VERSION "HNNBNNNYNNNNNNNNNNNNNNNNNNNNNNNNNNNNNNNNNN/4/%%%/4/'%**4NNN///"

NS_ :

BS_:

BU_: BAP_Tester Gateway_Max Getriebe_DQ Motor_konv Parksperre Schaltbetaetigung

BO_ 313 VMM_02_Auth: 32 Gateway_Max
 SG_ VMM_02_CRC : 0|8@1+ (1,0) [0|255] ""  Getriebe_DQ,Motor_konv
 SG_ VMM_02_BZ : 8|4@1+ (1,0) [0|15] ""  Getriebe_DQ,Motor_konv
 SG_ VZM_aktiver_Basisservice : 12|3@1+ (1.0,0.0) [0.0|7] ""  Motor_konv
 SG_ VZM_Anhalteweg_nicht_verfuegbar : 15|1@1+ (1.0,0.0) [0.0|1] ""  Vector__XXX
 SG_ VZM_Fahrer_bremst : 16|1@1+ (1.0,0.0) [0.0|1] ""  Motor_konv
 SG_ VZM_QBit_Fahrer_bremst : 17|1@1+ (1.0,0.0) [0.0|1] ""  Motor_konv
 SG_ VMM_MKB_codiert : 18|1@1+ (1.0,0.0) [0.0|1] ""  Vector__XXX
 SG_ VMM_Inkonsistenz_EBKV : 19|1@1+ (1.0,0.0) [0.0|1] ""  Vector__XXX
 SG_ VMM_Notstopp_Status : 20|3@1+ (1.0,0.0) [0.0|7] ""  Motor_konv
 SG_ VZM_Warnruck_nicht_verfuegbar : 23|1@1+ (1.0,0.0) [0.0|1] ""  Vector__XXX
 SG_ VZM_Warnruckeln_nicht_verfuegbar : 24|1@1+ (1.0,0.0) [0.0|1] ""  Vector__XXX
 SG_ VZM_Bkd_nicht_verfuegbar : 25|1@1+ (1.0,0.0) [0.0|1] ""  Vector__XXX
 SG_ VMM_Bremslicht_defekt : 26|1@1+ (1.0,0.0) [0.0|1] ""  Motor_konv
 SG_ VZM_Fahrer_bremst_deutlich : 27|1@1+ (1.0,0.0) [0.0|1] ""  Vector__XXX
 SG_ VZM_TSK_SRBM_Anf : 28|1@1+ (1.0,0.0) [0.0|1] ""  Motor_konv
 SG_ VZM_TSK_SRBM_nicht_verfuegbar : 29|1@1+ (1.0,0.0) [0.0|1] ""  Motor_konv
 SG_ VZM_Verz_Reg_aktiv : 30|5@1+ (1.0,0.0) [0.0|31] ""  Motor_konv
 SG_ VZM_Verz_Reg_nicht_verfuegbar : 35|1@1+ (1.0,0.0) [0.0|1] ""  Motor_konv
 SG_ VMM_Inkonsistenz_KAS : 36|1@1+ (1.0,0.0) [0.0|1] ""  Vector__XXX
 SG_ VMM_Bremslicht_unplausibel : 37|1@1+ (1.0,0.0) [0.0|1] ""  Motor_konv
 SG_ VMM_Inkonsistenz_ACC : 38|1@1+ (1.0,0.0) [0.0|1] ""  Vector__XXX
 SG_ VMM_Inkonsistenz_AWV_PCF : 39|1@1+ (1.0,0.0) [0.0|1] ""  Vector__XXX
 SG_ VMM_Inkonsistenz_ARA : 40|1@1+ (1.0,0.0) [0.0|1] ""  Vector__XXX
 SG_ VMM_Inkonsistenz_ParkAssist : 41|1@1+ (1.0,0.0) [0.0|1] ""  Vector__XXX
 SG_ VMM_Inkonsistenz_FAS_VK : 42|1@1+ (1.0,0.0) [0.0|1] ""  Vector__XXX
 SG_ VMM_Inkonsistenz_NV : 43|1@1+ (1.0,0.0) [0.0|1] ""  Vector__XXX
 SG_ VMM_Inkonsistenz_RCTA : 44|1@1+ (1.0,0.0) [0.0|1] ""  Vector__XXX
 SG_ VMM_Inkonsistenz_TSK : 45|1@1+ (1.0,0.0) [0.0|1] ""  Motor_konv
 SG_ VMM_Inkonsistenz_MO : 46|1@1+ (1.0,0.0) [0.0|1] ""  Motor_konv
 SG_ VMM_Inkonsistenz_AEB : 47|1@1+ (1.0,0.0) [0.0|1] ""  Vector__XXX
 SG_ VMM_Fahrer_Bremskraft_bestimmend : 48|1@1+ (1.0,0.0) [0.0|1] ""  Motor_konv
 SG_ VMM_Inkonsistenz_EA : 49|1@1+ (1.0,0.0) [0.0|1] ""  Vector__XXX
 SG_ VZM_Status_Wegregelung : 50|2@1+ (1.0,0.0) [0.0|3] ""  Motor_konv
 SG_ VZM_Verz_ASIL_Verfuegbarkeit : 52|3@1+ (1.0,0.0) [0.0|7] ""  Motor_konv
 SG_ VZM_aktives_System : 55|5@1+ (1.0,0.0) [0.0|31] ""  Motor_konv
 SG_ VZM_Verz_Begrenzung : 60|1@1+ (1.0,0.0) [0.0|1] ""  Motor_konv
 SG_ VZM_Systemstatus : 61|3@1+ (1.0,0.0) [0.0|7] ""  Motor_konv
 SG_ VZM_SRBM_Soll : 64|12@1+ (8,0) [0|32744] "Unit_NewtoMeter"  Vector__XXX
 SG_ VZM_SRBM_Ist : 76|12@1+ (8,0) [0|32744] "Unit_NewtoMeter"  Motor_konv
 SG_ VZM_SRBM_max_Gradient : 88|7@1+ (50,0) [0|6250] "Unit_NewtoMeterPerSecon"  Motor_konv
 SG_ VMM_Inkonsistenz_KAM : 95|1@1+ (1.0,0.0) [0.0|1] ""  Vector__XXX
 SG_ VMM_Inkonsistenz_RHP : 96|1@1+ (1.0,0.0) [0.0|1] ""  Vector__XXX
 SG_ HMS_P_beibehalten_GE : 172|2@1+ (1.0,0.0) [0.0|3] ""  Getriebe_DQ
 SG_ VZM_Unterdrueckung_Antriebsmom : 174|1@1+ (1.0,0.0) [0.0|1] ""  Getriebe_DQ,Motor_konv
 SG_ VMM_Inkonsistenz_VLK : 175|1@1+ (1.0,0.0) [0.0|1] ""  Vector__XXX
 SG_ HMS_halten_nicht_verfuegbar_02 : 176|2@1+ (1.0,0.0) [0.0|3] ""  Vector__XXX
 SG_ HMS_halten_nicht_verfuegbar : 180|1@1+ (1.0,0.0) [0.0|1] ""  Getriebe_DQ
 SG_ HMS_parken_nicht_verfuegbar : 192|1@1+ (1.0,0.0) [0.0|1] ""  Getriebe_DQ
 SG_ HMS_Anforderung_GE : 193|3@1+ (1.0,0.0) [0.0|7] ""  Getriebe_DQ
 SG_ HMS_Systemstatus : 196|4@1+ (1.0,0.0) [0.0|15] ""  Getriebe_DQ,Motor_konv
 SG_ HMS_Stillstand : 200|3@1+ (1.0,0.0) [0.0|7] ""  Getriebe_DQ,Motor_konv
 SG_ HMS_aktives_System : 203|5@1+ (1.0,0.0) [0.0|31] ""  Getriebe_DQ,Motor_konv
 SG_ VMM_Inkonsistenz_GE : 208|1@1+ (1.0,0.0) [0.0|1] ""  Vector__XXX
 SG_ VMM_Inkonsistenz_HVLM : 209|1@1+ (1.0,0.0) [0.0|1] ""  Vector__XXX
 SG_ HMS_Fehlerstatus : 210|3@1+ (1.0,0.0) [0.0|7] ""  Getriebe_DQ,Motor_konv
 SG_ HMS_Index_Haltemoment : 213|1@1+ (1.0,0.0) [0.0|1] ""  Motor_konv
 SG_ HMS_Haltemoment : 214|10@1+ (10,0) [0|10210] "Unit_NewtoMeter"  Motor_konv
 SG_ SOK_VMM_02_Signatur : 224|32@1+ (1,0) [0|4294967295] ""  Vector__XXX

BO_ 2331595858 vREM_01: 64 Gateway_Max
 SG_ vREM_Status : 12|3@1+ (1.0,0.0) [0.0|7] ""  Motor_konv
 SG_ vREM_Abstand_P0 : 15|9@1+ (1,0) [0|510] "Unit_Meter"  Motor_konv
 SG_ vREM_Abstand_P1 : 24|9@1+ (1,0) [0|510] "Unit_Meter"  Motor_konv
 SG_ vREM_Abstand_P2 : 33|9@1+ (1,0) [0|510] "Unit_Meter"  Motor_konv
 SG_ vREM_Abstand_P3 : 42|9@1+ (1,0) [0|510] "Unit_Meter"  Motor_konv
 SG_ vREM_Abstand_P4 : 51|9@1+ (1,0) [0|510] "Unit_Meter"  Motor_konv
 SG_ vREM_Abstand_P5 : 60|9@1+ (1,0) [0|510] "Unit_Meter"  Motor_konv
 SG_ vREM_Abstand_P6 : 69|9@1+ (1,0) [0|510] "Unit_Meter"  Motor_konv
 SG_ vREM_Abstand_P7 : 78|9@1+ (1,0) [0|510] "Unit_Meter"  Motor_konv
 SG_ vREM_Abstand_P8 : 87|9@1+ (1,0) [0|510] "Unit_Meter"  Motor_konv
 SG_ vREM_Abstand_P9 : 96|9@1+ (1,0) [0|510] "Unit_Meter"  Motor_konv
 SG_ vREM_Abstand_P10 : 105|9@1+ (1,0) [0|510] "Unit_Meter"  Motor_konv
 SG_ vREM_Abstand_P11 : 114|9@1+ (1,0) [0|510] "Unit_Meter"  Motor_konv
 SG_ vREM_Abstand_P12 : 123|9@1+ (1,0) [0|510] "Unit_Meter"  Motor_konv
 SG_ vREM_Abstand_P13 : 132|9@1+ (1,0) [0|510] "Unit_Meter"  Motor_konv
 SG_ vREM_Abstand_P14 : 141|9@1+ (1,0) [0|510] "Unit_Meter"  Motor_konv
 SG_ vREM_Abstand_P15 : 150|9@1+ (1,0) [0|510] "Unit_Meter"  Motor_konv
 SG_ vREM_Abstand_P16 : 159|9@1+ (1,0) [0|510] "Unit_Meter"  Motor_konv
 SG_ vREM_Abstand_P17 : 168|9@1+ (1,0) [0|510] "Unit_Meter"  Motor_konv
 SG_ vREM_Abstand_P18 : 177|9@1+ (1,0) [0|510] "Unit_Meter"  Motor_konv
 SG_ vREM_Abstand_P19 : 186|9@1+ (1,0) [0|510] "Unit_Meter"  Motor_konv
 SG_ vREM_Abstand_P20 : 195|9@1+ (1,0) [0|510] "Unit_Meter"  Motor_konv
 SG_ vREM_Abstand_P21 : 204|9@1+ (1,0) [0|510] "Unit_Meter"  Motor_konv
 SG_ vREM_Abstand_P22 : 213|9@1+ (1,0) [0|510] "Unit_Meter"  Motor_konv
 SG_ vREM_Abstand_P23 : 222|9@1+ (1,0) [0|510] "Unit_Meter"  Motor_konv
 SG_ vREM_Abstand_P24 : 231|9@1+ (1,0) [0|510] "Unit_Meter"  Motor_konv
 SG_ vREM_Abstand_P25 : 240|9@1+ (1,0) [0|510] "Unit_Meter"  Motor_konv
 SG_ vREM_Abstand_P26 : 249|9@1+ (1,0) [0|510] "Unit_Meter"  Motor_konv
 SG_ vREM_Abstand_P27 : 258|9@1+ (1,0) [0|510] "Unit_Meter"  Motor_konv
 SG_ vREM_Abstand_P28 : 267|9@1+ (1,0) [0|510] "Unit_Meter"  Motor_konv
 SG_ vREM_Abstand_P29 : 276|9@1+ (1,0) [0|510] "Unit_Meter"  Motor_konv
 SG_ vREM_Akt_Zaehler : 285|4@1+ (1,0) [0|15] ""  Motor_konv

BO_ 2331595859 vREM_02: 64 Gateway_Max
 SG_ vREM_Geschw_P0 : 16|8@1+ (0.2778,0) [0.0000|70.2834] "Unit_MeterPerSecon"  Motor_konv
 SG_ vREM_Geschw_P1 : 24|8@1+ (0.2778,0) [0.0000|70.2834] "Unit_MeterPerSecon"  Motor_konv
 SG_ vREM_Geschw_P2 : 32|8@1+ (0.2778,0) [0.0000|70.2834] "Unit_MeterPerSecon"  Motor_konv
 SG_ vREM_Geschw_P3 : 40|8@1+ (0.2778,0) [0.0000|70.2834] "Unit_MeterPerSecon"  Motor_konv
 SG_ vREM_Geschw_P4 : 48|8@1+ (0.2778,0) [0.0000|70.2834] "Unit_MeterPerSecon"  Motor_konv
 SG_ vREM_Geschw_P5 : 56|8@1+ (0.2778,0) [0.0000|70.2834] "Unit_MeterPerSecon"  Motor_konv
 SG_ vREM_Geschw_P6 : 64|8@1+ (0.2778,0) [0.0000|70.2834] "Unit_MeterPerSecon"  Motor_konv
 SG_ vREM_Geschw_P7 : 72|8@1+ (0.2778,0) [0.0000|70.2834] "Unit_MeterPerSecon"  Motor_konv
 SG_ vREM_Geschw_P8 : 80|8@1+ (0.2778,0) [0.0000|70.2834] "Unit_MeterPerSecon"  Motor_konv
 SG_ vREM_Geschw_P9 : 88|8@1+ (0.2778,0) [0.0000|70.2834] "Unit_MeterPerSecon"  Motor_konv
 SG_ vREM_Geschw_P10 : 96|8@1+ (0.2778,0) [0.0000|70.2834] "Unit_MeterPerSecon"  Motor_konv
 SG_ vREM_Geschw_P11 : 104|8@1+ (0.2778,0) [0.0000|70.2834] "Unit_MeterPerSecon"  Motor_konv
 SG_ vREM_Geschw_P12 : 112|8@1+ (0.2778,0) [0.0000|70.2834] "Unit_MeterPerSecon"  Motor_konv
 SG_ vREM_Geschw_P13 : 120|8@1+ (0.2778,0) [0.0000|70.2834] "Unit_MeterPerSecon"  Motor_konv
 SG_ vREM_Geschw_P14 : 128|8@1+ (0.2778,0) [0.0000|70.2834] "Unit_MeterPerSecon"  Motor_konv
 SG_ vREM_Geschw_P15 : 136|8@1+ (0.2778,0) [0.0000|70.2834] "Unit_MeterPerSecon"  Motor_konv
 SG_ vREM_Geschw_P16 : 144|8@1+ (0.2778,0) [0.0000|70.2834] "Unit_MeterPerSecon"  Motor_konv
 SG_ vREM_Geschw_P17 : 152|8@1+ (0.2778,0) [0.0000|70.2834] "Unit_MeterPerSecon"  Motor_konv
 SG_ vREM_Geschw_P18 : 160|8@1+ (0.2778,0) [0.0000|70.2834] "Unit_MeterPerSecon"  Motor_konv
 SG_ vREM_Geschw_P19 : 168|8@1+ (0.2778,0) [0.0000|70.2834] "Unit_MeterPerSecon"  Motor_konv
 SG_ vREM_Geschw_P20 : 176|8@1+ (0.2778,0) [0.0000|70.2834] "Unit_MeterPerSecon"  Motor_konv
 SG_ vREM_Geschw_P21 : 184|8@1+ (0.2778,0) [0.0000|70.2834] "Unit_MeterPerSecon"  Motor_konv
 SG_ vREM_Geschw_P22 : 192|8@1+ (0.2778,0) [0.0000|70.2834] "Unit_MeterPerSecon"  Motor_konv
 SG_ vREM_Geschw_P23 : 200|8@1+ (0.2778,0) [0.0000|70.2834] "Unit_MeterPerSecon"  Motor_konv
 SG_ vREM_Geschw_P24 : 208|8@1+ (0.2778,0) [0.0000|70.2834] "Unit_MeterPerSecon"  Motor_konv
 SG_ vREM_Geschw_P25 : 216|8@1+ (0.2778,0) [0.0000|70.2834] "Unit_MeterPerSecon"  Motor_konv
 SG_ vREM_Geschw_P26 : 224|8@1+ (0.2778,0) [0.0000|70.2834] "Unit_MeterPerSecon"  Motor_konv
 SG_ vREM_Geschw_P27 : 232|8@1+ (0.2778,0) [0.0000|70.2834] "Unit_MeterPerSecon"  Motor_konv
 SG_ vREM_Geschw_P28 : 240|8@1+ (0.2778,0) [0.0000|70.2834] "Unit_MeterPerSecon"  Motor_konv
 SG_ vREM_Geschw_P29 : 248|8@1+ (0.2778,0) [0.0000|70.2834] "Unit_MeterPerSecon"  Motor_konv

BO_ 2463978663 VZE_04: 32 Gateway_Max
 SG_ VZE_Anzeigemodus : 0|2@1+ (1.0,0.0) [0.0|3] ""  Vector__XXX
 SG_ VZE_Hinweistext : 2|3@1+ (1,0) [1|7] ""  Motor_konv
 SG_ VZE_Akustik_Limitwechsel : 5|1@1+ (1.0,0.0) [0.0|1] ""  Vector__XXX
 SG_ VZE_Modus_OptischeWarnung : 6|1@1+ (1.0,0.0) [0.0|1] ""  Vector__XXX
 SG_ VZE_Verkehrszeichen_Einheit : 8|1@1+ (1.0,0.0) [0.0|1] ""  Vector__XXX
 SG_ VZE_Anzeigeunterdrueck_Zeichen_3 : 9|1@1+ (1.0,0.0) [0.0|1] ""  Vector__XXX
 SG_ VZE_Anzeigeunterdrueck_Zeichen_2 : 10|1@1+ (1.0,0.0) [0.0|1] ""  Vector__XXX
 SG_ VZE_Verkehrszeichen_1 : 11|8@1+ (1,0) [1|255] ""  Motor_konv
 SG_ VZE_Verkehrszeichen_2 : 19|8@1+ (1,0) [1|255] ""  Vector__XXX
 SG_ VZE_Verkehrszeichen_3 : 27|8@1+ (1,0) [1|255] ""  Vector__XXX
 SG_ VZE_Warnung_Verkehrszeichen_1 : 35|1@1+ (1.0,0.0) [0.0|1] ""  Vector__XXX
 SG_ VZE_Warnung_Verkehrszeichen_2 : 36|1@1+ (1.0,0.0) [0.0|1] ""  Vector__XXX
 SG_ VZE_Warnung_Verkehrszeichen_3 : 37|1@1+ (1.0,0.0) [0.0|1] ""  Vector__XXX
 SG_ VZE_Zusatzschild_1 : 38|4@1+ (1,0) [1|15] ""  Vector__XXX
 SG_ VZE_Zusatzschild_2 : 42|4@1+ (1,0) [1|15] ""  Vector__XXX
 SG_ VZE_Zusatzschild_3 : 46|4@1+ (1,0) [1|15] ""  Vector__XXX
 SG_ VZE_Anzeigeunterdrueck_Zeichen_1 : 50|1@1+ (1.0,0.0) [0.0|1] ""  Vector__XXX
 SG_ VZE_Zeichen_01_KameraWied : 51|1@1+ (1.0,0.0) [0.0|1] ""  Motor_konv
 SG_ VZE_Zeichen_02_KameraWied : 52|1@1+ (1.0,0.0) [0.0|1] ""  Vector__XXX
 SG_ VZE_Zeichen_03_KameraWied : 53|1@1+ (1.0,0.0) [0.0|1] ""  Vector__XXX
 SG_ VZE_Zeichen_01_Kamera : 54|1@1+ (1.0,0.0) [0.0|1] ""  Motor_konv
 SG_ VZE_Zeichen_01_Karte : 55|1@1+ (1.0,0.0) [0.0|1] ""  Vector__XXX
 SG_ VZE_Zeichen_01_Gesetz : 56|1@1+ (1.0,0.0) [0.0|1] ""  Vector__XXX
 SG_ VZE_Zeichen_02_Kamera : 57|1@1+ (1.0,0.0) [0.0|1] ""  Vector__XXX
 SG_ VZE_Zeichen_02_Karte : 58|1@1+ (1.0,0.0) [0.0|1] ""  Vector__XXX
 SG_ VZE_Zeichen_02_Gesetz : 59|1@1+ (1.0,0.0) [0.0|1] ""  Vector__XXX
 SG_ VZE_Zeichen_03_Kamera : 60|1@1+ (1.0,0.0) [0.0|1] ""  Vector__XXX
 SG_ VZE_Zeichen_03_Karte : 61|1@1+ (1.0,0.0) [0.0|1] ""  Vector__XXX
 SG_ VZE_Zeichen_03_Gesetz : 62|1@1+ (1.0,0.0) [0.0|1] ""  Vector__XXX
 SG_ VZE_Gong : 63|1@1+ (1.0,0.0) [0.0|1] ""  Vector__XXX
 SG_ VZE_Akustik_Limitwechsel_Status : 69|1@1+ (1.0,0.0) [0.0|1] ""  Vector__XXX
 SG_ VZE_SLWF_Status : 70|2@1+ (1.0,0.0) [0.0|3] ""  Vector__XXX
 SG_ VZE_Anzeigeunterdrueck_Zeichen_5 : 72|1@1+ (1.0,0.0) [0.0|1] ""  Vector__XXX
 SG_ VZE_Zeichen_05_KameraWied : 73|1@1+ (1.0,0.0) [0.0|1] ""  Vector__XXX
 SG_ VZE_Zeichen_05_Kamera : 74|1@1+ (1.0,0.0) [0.0|1] ""  Vector__XXX
 SG_ VZE_Verkehrszeichen_4 : 75|8@1+ (1,0) [1|255] ""  Motor_konv
 SG_ VZE_Verkehrszeichen_5 : 83|8@1+ (1,0) [1|255] ""  Motor_konv
 SG_ VZE_Anhaenger_Vmax : 91|4@1+ (10,10) [10|140] "Unit_KiloMeterPerHour"  Motor_konv
 SG_ VZE_Zeichen_04_Gesetz : 95|1@1+ (1.0,0.0) [0.0|1] ""  Vector__XXX
 SG_ VZE_Zeichen_04_Kamera : 96|1@1+ (1.0,0.0) [0.0|1] ""  Vector__XXX
 SG_ VZE_Zeichen_04_KameraWied : 97|1@1+ (1.0,0.0) [0.0|1] ""  Vector__XXX
 SG_ VZE_Zeichen_04_Karte : 98|1@1+ (1.0,0.0) [0.0|1] ""  Vector__XXX
 SG_ VZE_Warnung_Verkehrszeichen_4 : 99|1@1+ (1.0,0.0) [0.0|1] ""  Vector__XXX
 SG_ VZE_Warnung_Verkehrszeichen_5 : 100|1@1+ (1.0,0.0) [0.0|1] ""  Vector__XXX
 SG_ VZE_Zeichen_05_Gesetz : 101|1@1+ (1.0,0.0) [0.0|1] ""  Vector__XXX
 SG_ VZE_Zusatzschild_4 : 102|4@1+ (1,0) [1|15] ""  Vector__XXX
 SG_ VZE_Zusatzschild_5 : 106|4@1+ (1,0) [1|15] ""  Vector__XXX
 SG_ VZE_Baustelle : 110|2@1+ (1.0,0.0) [0.0|3] ""  Vector__XXX
 SG_ VZE_Zeichen_05_Karte : 112|1@1+ (1.0,0.0) [0.0|1] ""  Vector__XXX
 SG_ VZE_Zeichen_05_Entfernung : 113|7@1+ (1,0) [1|127] "Unit_Meter"  Motor_konv
 SG_ VZE_Zeichen_05_Entfernung_StdA : 120|7@1+ (1,0) [1|127] "Unit_Meter"  Motor_konv
 SG_ VZE_Anzeigeunterdrueck_Zeichen_4 : 127|1@1+ (1.0,0.0) [0.0|1] ""  Vector__XXX
 SG_ VZE_Verkehrszeichen_6 : 128|8@1+ (1,0) [1|255] "Unit_None"  Motor_konv
 SG_ VZE_Zusatzschild_6 : 136|4@1+ (1,0) [1|15] ""  Vector__XXX
 SG_ VZE_Zeichen_06_Entfernung : 140|7@1+ (1,0) [1|127] "Unit_Meter"  Motor_konv
 SG_ VZE_Zeichen_06_Entfernung_StdA : 147|7@1+ (1,0) [1|127] "Unit_Meter"  Motor_konv
 SG_ VZE_Umweltinfo_Naesse : 154|1@1+ (1.0,0.0) [0.0|1] ""  Motor_konv
 SG_ VZE_Umweltinfo_Nebel : 155|1@1+ (1.0,0.0) [0.0|1] ""  Motor_konv
 SG_ VZE_Umweltinfo_Anhaengerbetrieb : 156|1@1+ (1.0,0.0) [0.0|1] ""  Motor_konv
 SG_ VZE_Erweiterte_Information : 157|8@1+ (1,0) [1|255] "Unit_None"  Vector__XXX
 SG_ VZE_Tempowarnung_Status : 165|1@1+ (1.0,0.0) [0.0|1] ""  Vector__XXX
 SG_ VZE_Tempowarnung_Einheit : 166|1@1+ (1.0,0.0) [0.0|1] ""  Vector__XXX
 SG_ VZE_Tempowarnung_Offset : 167|5@1+ (1,0) [1|31] ""  Vector__XXX
 SG_ VZE_FoD_Status : 206|2@1+ (1.0,0.0) [0.0|3] ""  Motor_konv
 SG_ VZE_Anzeige_ZS_1 : 208|4@1+ (1,0) [1|15] "Unit_None"  Vector__XXX
 SG_ VZE_Anzeige_ZS_2 : 212|4@1+ (1,0) [1|15] "Unit_None"  Vector__XXX
 SG_ VZE_Anzeige_ZS_3 : 216|4@1+ (1,0) [1|15] "Unit_None"  Vector__XXX
 SG_ VZE_Hinweistext_03 : 220|4@1+ (1,0) [1|15] ""  Vector__XXX
 SG_ VZE_Land : 224|5@1+ (1,0) [1|31] ""  Vector__XXX
 SG_ VZE_Warnung_VZ_1 : 229|1@1+ (1.0,0.0) [0.0|1] ""  Vector__XXX
 SG_ VZE_Warnung_VZ_2 : 230|1@1+ (1.0,0.0) [0.0|1] ""  Vector__XXX
 SG_ VZE_Warnung_VZ_3 : 231|1@1+ (1.0,0.0) [0.0|1] ""  Vector__XXX
 SG_ VZE_Anzeige_VZ_1 : 232|8@1+ (1,0) [1|255] ""  Vector__XXX
 SG_ VZE_Anzeige_VZ_2 : 240|8@1+ (1,0) [1|255] "Unit_None"  Vector__XXX
 SG_ VZE_Anzeige_VZ_3 : 248|8@1+ (1,0) [1|255] "Unit_None"  Vector__XXX

BO_ 181 Waehlhebel_04: 8 Gateway_Max
 SG_ Waehlhebel_04_CRC : 0|8@1+ (1,0) [0|255] ""  Getriebe_DQ
 SG_ Waehlhebel_04_BZ : 8|4@1+ (1,0) [0|15] ""  Getriebe_DQ
 SG_ WH_gespeicherte_Fahrstufe : 12|3@1+ (1.0,0.0) [0.0|7] ""  Gateway_Max,Getriebe_DQ
 SG_ WH_Initialisierung : 15|1@1+ (1.0,0.0) [0.0|1] ""  Vector__XXX
 SG_ WH_SensorPos_roh : 16|4@1+ (1.0,0.0) [0.0|15] ""  Vector__XXX
 SG_ WH_SensorPos_roh_inv : 20|4@1+ (1.0,0.0) [0.0|15] ""  Vector__XXX
 SG_ WH_Testergebnis : 24|8@1+ (1,0) [0|255] ""  Vector__XXX
 SG_ WH_Test_Aktiv : 32|1@1+ (1.0,0.0) [0.0|1] ""  Vector__XXX
 SG_ WH_Ist_Haltemagnet : 33|2@1+ (1.0,0.0) [0.0|3] ""  Vector__XXX
 SG_ WH_Variante : 35|4@1+ (1.0,0.0) [0.0|15] ""  Getriebe_DQ
 SG_ WH_Entsperrtaste_02 : 39|2@1+ (1.0,0.0) [0.0|3] ""  Getriebe_DQ
 SG_ WH_P_Taste : 41|2@1+ (1.0,0.0) [0.0|3] ""  Getriebe_DQ
 SG_ WH_Ende_N_Haltephase : 43|1@1+ (1.0,0.0) [0.0|1] ""  Vector__XXX
 SG_ WH_Fahrstufe : 44|4@1+ (1.0,0.0) [0.0|15] ""  Getriebe_DQ
 SG_ WH_Status_Shiftlock : 48|3@1+ (1.0,0.0) [0.0|7] ""  Vector__XXX
 SG_ WH_Zustand_N_Haltephase : 51|2@1+ (1.0,0.0) [0.0|3] ""  Vector__XXX
 SG_ WH_Zustand_N_Haltephase_2 : 53|3@1+ (1.0,0.0) [0.0|7] ""  Vector__XXX

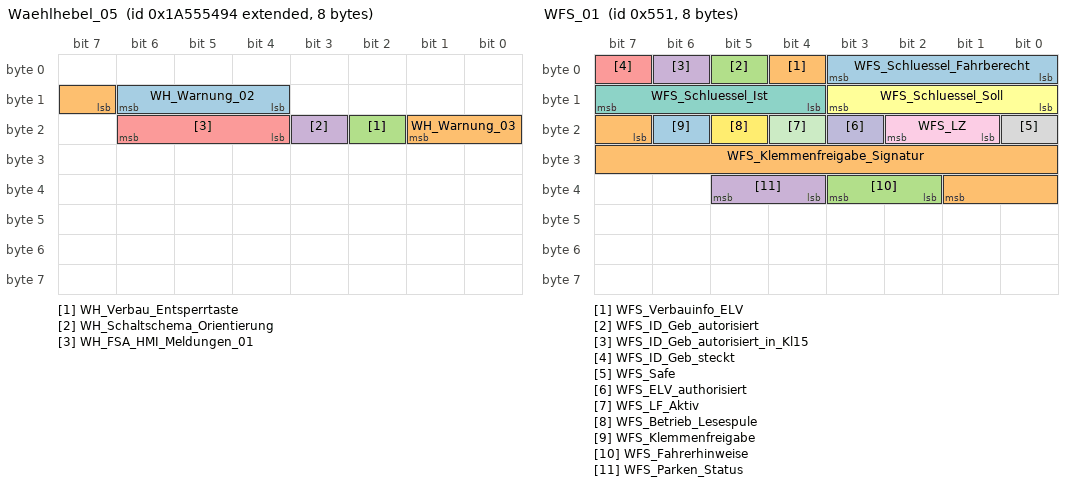
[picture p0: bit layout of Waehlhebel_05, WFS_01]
BO_ 2589283476 Waehlhebel_05: 8 Getriebe_DQ
 SG_ WH_Warnung_02 : 12|3@1+ (1.0,0.0) [0.0|7] ""  Gateway_Max
 SG_ WH_Warnung_03 : 15|3@1+ (1.0,0.0) [0.0|7] ""  Gateway_Max
 SG_ WH_Verbau_Entsperrtaste : 18|1@1+ (1.0,0.0) [0.0|1] ""  Gateway_Max
 SG_ WH_Schaltschema_Orientierung : 19|1@1+ (1.0,0.0) [0.0|1] ""  Gateway_Max
 SG_ WH_FSA_HMI_Meldungen_01 : 20|3@1+ (1.0,0.0) [0.0|7] ""  Gateway_Max

BO_ 2463978687 Waehlhebel_06: 8 Gateway_Max
 SG_ WH_Fehler_Haltemagnet : 40|1@1+ (1.0,0.0) [0.0|1] ""  Vector__XXX
 SG_ WH_Fehler_Haltemagnet_Status : 41|1@1+ (1.0,0.0) [0.0|1] ""  Vector__XXX
 SG_ WH_Fehler_CRC_SBM : 42|1@1+ (1.0,0.0) [0.0|1] ""  Getriebe_DQ
 SG_ WH_Fehler_CRC_SBM_Status : 43|1@1+ (1.0,0.0) [0.0|1] ""  Getriebe_DQ
 SG_ WH_Fehler_Timeout_SBM : 44|1@1+ (1.0,0.0) [0.0|1] ""  Getriebe_DQ
 SG_ WH_Fehler_Timeout_SBM_Status : 45|1@1+ (1.0,0.0) [0.0|1] ""  Getriebe_DQ
 SG_ WH_Fehler_Ueberspannung : 46|1@1+ (1.0,0.0) [0.0|1] ""  Getriebe_DQ
 SG_ WH_Fehler_Ueberspannung_Status : 47|1@1+ (1.0,0.0) [0.0|1] ""  Getriebe_DQ
 SG_ WH_Fehler_BZ_SBM : 48|1@1+ (1.0,0.0) [0.0|1] ""  Getriebe_DQ
 SG_ WH_Fehler_BZ_SBM_Status : 49|1@1+ (1.0,0.0) [0.0|1] ""  Getriebe_DQ
 SG_ WH_Fehler_Unterspannung : 50|1@1+ (1.0,0.0) [0.0|1] ""  Getriebe_DQ
 SG_ WH_Fehler_Unterspannung_Status : 51|1@1+ (1.0,0.0) [0.0|1] ""  Getriebe_DQ
 SG_ WH_Fehler_Ausleuchtung : 52|1@1+ (1.0,0.0) [0.0|1] ""  Getriebe_DQ
 SG_ WH_Fehler_Ausleuchtung_Status : 53|1@1+ (1.0,0.0) [0.0|1] ""  Getriebe_DQ
 SG_ WH_Fehler_Entsperrtaste : 54|1@1+ (1.0,0.0) [0.0|1] ""  Getriebe_DQ
 SG_ WH_Fehler_Entsperrtaste_Status : 55|1@1+ (1.0,0.0) [0.0|1] ""  Getriebe_DQ
 SG_ WH_Fehler_P_Taste : 56|1@1+ (1.0,0.0) [0.0|1] ""  Getriebe_DQ
 SG_ WH_Fehler_P_Taste_Status : 57|1@1+ (1.0,0.0) [0.0|1] ""  Getriebe_DQ
 SG_ WH_Fehler_Sensor_einfach : 58|1@1+ (1.0,0.0) [0.0|1] ""  Getriebe_DQ
 SG_ WH_Fehler_Sensor_einfach_Status : 59|1@1+ (1.0,0.0) [0.0|1] ""  Getriebe_DQ
 SG_ WH_Fehler_Sensor_mehrfach : 60|1@1+ (1.0,0.0) [0.0|1] ""  Getriebe_DQ
 SG_ WH_Fehler_Sensor_mehrfach_Status : 61|1@1+ (1.0,0.0) [0.0|1] ""  Getriebe_DQ
 SG_ WH_Fehler_Shiftlock : 62|1@1+ (1.0,0.0) [0.0|1] ""  Getriebe_DQ
 SG_ WH_Fehler_Shiftlock_Status : 63|1@1+ (1.0,0.0) [0.0|1] ""  Getriebe_DQ

BO_ 916 WBA_03: 8 Getriebe_DQ
 SG_ WBA_03_CRC : 0|8@1+ (1,0) [0|255] ""  Gateway_Max
 SG_ WBA_03_BZ : 8|4@1+ (1,0) [0|15] ""  Gateway_Max
 SG_ WBA_Fahrstufe_02 : 12|4@1+ (1.0,0.0) [0.0|15] ""  Gateway_Max
 SG_ WBA_ZielFahrstufe : 16|4@1+ (1.0,0.0) [0.0|15] ""  Gateway_Max
 SG_ WBA_GE_Warnung_02 : 20|4@1+ (1.0,0.0) [0.0|15] ""  Gateway_Max
 SG_ WBA_eing_Gang_02 : 24|4@1+ (1.0,0.0) [0.0|15] ""  Gateway_Max
 SG_ WBA_GE_Texte : 28|3@1+ (1.0,0.0) [0.0|7] ""  Gateway_Max
 SG_ WBA_Segeln_aktiv : 31|1@1+ (1.0,0.0) [0.0|1] ""  Gateway_Max,Motor_konv
 SG_ WBA_Schaltschema_02 : 32|3@1+ (1.0,0.0) [0.0|7] ""  Gateway_Max
 SG_ WBA_Schaltschema_FS_inaktiv : 35|2@1+ (1.0,0.0) [0.0|3] ""  Gateway_Max
 SG_ WBA_GE_Zusatzwarnungen : 37|3@1+ (1.0,0.0) [0.0|7] ""  Gateway_Max
 SG_ GE_Sollgang : 40|4@1+ (1.0,0.0) [0.0|15] ""  Gateway_Max,Motor_konv
 SG_ GE_Tipschaltempf_verfuegbar : 44|1@1+ (1.0,0.0) [0.0|1] ""  Gateway_Max
 SG_ WBA_GE_Texte_02 : 45|3@1+ (1.0,0.0) [0.0|7] ""  Gateway_Max
 SG_ WBA_Schaltschema_Tippgasse : 48|1@1+ (1.0,0.0) [0.0|1] ""  Gateway_Max
 SG_ WBA_Schaltschema_Fahreraktion : 49|1@1+ (1.0,0.0) [0.0|1] ""  Gateway_Max
 SG_ WBA_Schaltschema_FS_vorwaerts : 50|2@1+ (1.0,0.0) [0.0|3] ""  Gateway_Max
 SG_ WBA_Shiftlock_Lampe : 52|1@1+ (1.0,0.0) [0.0|1] ""  Gateway_Max
 SG_ WBA_Anforderung_Akustik : 53|1@1+ (1.0,0.0) [0.0|1] ""  Gateway_Max
 SG_ WBA_Blinken : 54|1@1+ (1.0,0.0) [0.0|1] ""  Gateway_Max
 SG_ GE_Wiederstart_Anz_Std : 55|1@1+ (1.0,0.0) [0.0|1] ""  Gateway_Max
 SG_ GE_Stoppverbot_Anz_01 : 56|1@1+ (1.0,0.0) [0.0|1] ""  Gateway_Max
 SG_ GE_Stoppverbot_Anz_02 : 57|1@1+ (1.0,0.0) [0.0|1] ""  Gateway_Max
 SG_ GE_Stoppverbot_Anz_03 : 58|1@1+ (1.0,0.0) [0.0|1] ""  Gateway_Max
 SG_ GE_Stoppverbot_Anz_04 : 59|1@1+ (1.0,0.0) [0.0|1] ""  Gateway_Max
 SG_ GE_Stoppverbot_Anz_05 : 60|1@1+ (1.0,0.0) [0.0|1] ""  Gateway_Max
 SG_ GE_Stoppverbot_Anz_06 : 61|1@1+ (1.0,0.0) [0.0|1] ""  Gateway_Max
 SG_ GE_Stoppverbot_Anz_07 : 62|1@1+ (1.0,0.0) [0.0|1] ""  Gateway_Max
 SG_ GE_Stoppverbot_Anz_Std : 63|1@1+ (1.0,0.0) [0.0|1] ""  Gateway_Max

BO_ 1361 WFS_01: 8 Gateway_Max
 SG_ WFS_Schluessel_Fahrberecht : 0|4@1+ (1.0,0.0) [0.0|15] ""  Vector__XXX
 SG_ WFS_Verbauinfo_ELV : 4|1@1+ (1.0,0.0) [0.0|1] ""  Vector__XXX
 SG_ WFS_ID_Geb_autorisiert : 5|1@1+ (1.0,0.0) [0.0|1] ""  Vector__XXX
 SG_ WFS_ID_Geb_autorisiert_in_Kl15 : 6|1@1+ (1.0,0.0) [0.0|1] ""  Motor_konv
 SG_ WFS_ID_Geb_steckt : 7|1@1+ (1.0,0.0) [0.0|1] ""  Vector__XXX
 SG_ WFS_Schluessel_Soll : 8|4@1+ (1,0) [0|8] "Unit_None"  Vector__XXX
 SG_ WFS_Schluessel_Ist : 12|4@1+ (1,0) [0|8] "Unit_None"  Vector__XXX
 SG_ WFS_Safe : 16|1@1+ (1.0,0.0) [0.0|1] ""  Vector__XXX
 SG_ WFS_LZ : 17|2@1+ (1.0,0.0) [0.0|3] ""  Vector__XXX
 SG_ WFS_ELV_authorisiert : 19|1@1+ (1.0,0.0) [0.0|1] ""  Vector__XXX
 SG_ WFS_LF_Aktiv : 20|1@1+ (1.0,0.0) [0.0|1] ""  Vector__XXX
 SG_ WFS_Betrieb_Lesespule : 21|1@1+ (1.0,0.0) [0.0|1] ""  Vector__XXX
 SG_ WFS_Klemmenfreigabe : 22|1@1+ (1.0,0.0) [0.0|1] ""  Motor_konv
 SG_ WFS_Klemmenfreigabe_Signatur : 23|11@1+ (1,0) [0|2047] ""  Vector__XXX
 SG_ WFS_Fahrerhinweise : 34|2@1+ (1.0,0.0) [0.0|3] ""  Vector__XXX
 SG_ WFS_Parken_Status : 36|2@1+ (1.0,0.0) [0.0|3] ""  Vector__XXX

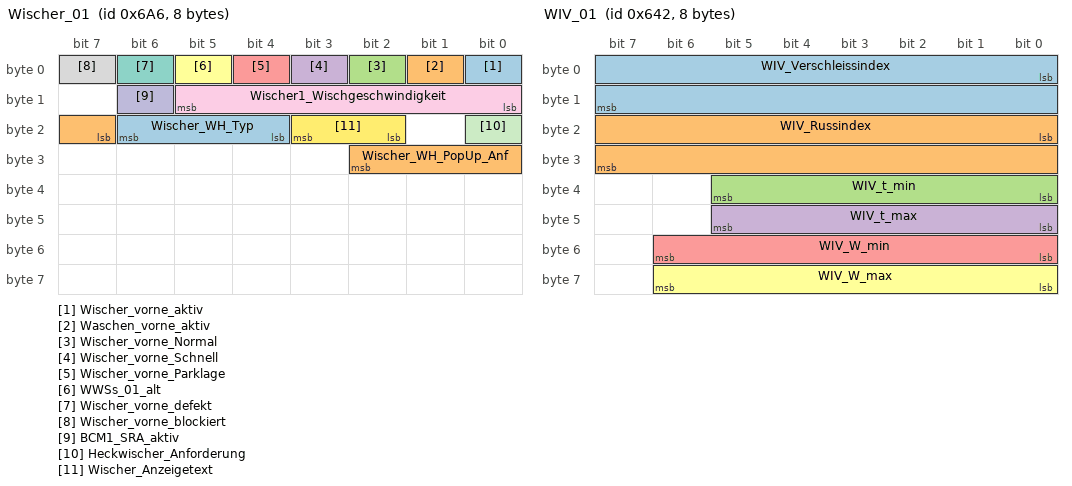
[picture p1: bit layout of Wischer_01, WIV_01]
BO_ 1702 Wischer_01: 8 Gateway_Max
 SG_ Wischer_vorne_aktiv : 0|1@1+ (1.0,0.0) [0.0|1] ""  Motor_konv
 SG_ Waschen_vorne_aktiv : 1|1@1+ (1.0,0.0) [0.0|1] ""  Motor_konv
 SG_ Wischer_vorne_Normal : 2|1@1+ (1.0,0.0) [0.0|1] ""  Vector__XXX
 SG_ Wischer_vorne_Schnell : 3|1@1+ (1.0,0.0) [0.0|1] ""  Vector__XXX
 SG_ Wischer_vorne_Parklage : 4|1@1+ (1.0,0.0) [0.0|1] ""  Vector__XXX
 SG_ WWSs_01_alt : 5|1@1+ (1.0,0.0) [0.0|1] ""  Vector__XXX
 SG_ Wischer_vorne_defekt : 6|1@1+ (1.0,0.0) [0.0|1] ""  Vector__XXX
 SG_ Wischer_vorne_blockiert : 7|1@1+ (1.0,0.0) [0.0|1] ""  Vector__XXX
 SG_ Wischer1_Wischgeschwindigkeit : 8|6@1+ (1,9) [10|70] "Unit_MinutInver"  Vector__XXX
 SG_ BCM1_SRA_aktiv : 14|1@1+ (1.0,0.0) [0.0|1] ""  Vector__XXX
 SG_ Heckwischer_Anforderung : 16|1@1+ (1.0,0.0) [0.0|1] ""  Vector__XXX
 SG_ Wischer_Anzeigetext : 18|2@1+ (1.0,0.0) [0.0|3] ""  Vector__XXX
 SG_ Wischer_WH_Typ : 20|3@1+ (1.0,0.0) [0.0|7] ""  Vector__XXX
 SG_ Wischer_WH_PopUp_Anf : 23|4@1+ (1.0,0.0) [0.0|15] ""  Vector__XXX

BO_ 1602 WIV_01: 8 Motor_konv
 SG_ WIV_Verschleissindex : 0|16@1+ (2E-8,0) [0E-8|0.00131068] ""  Gateway_Max
 SG_ WIV_Russindex : 16|16@1+ (2E-8,0) [0E-8|0.00131068] ""  Gateway_Max
 SG_ WIV_t_min : 32|6@1+ (1,0) [0|63] "Unit_Month"  Gateway_Max
 SG_ WIV_t_max : 40|6@1+ (1,0) [0|63] "Unit_Month"  Gateway_Max
 SG_ WIV_W_min : 48|7@1+ (1000,0) [0|127000] "Unit_KiloMeter"  Gateway_Max
 SG_ WIV_W_max : 56|7@1+ (1000,0) [0|127000] "Unit_KiloMeter"  Gateway_Max

BO_ 2617228832 XCP_Getriebe_CRO_20: 64 Vector__XXX
 SG_ XCP_Getriebe_CRO_20_Data : 0|512@1+ (1.0,0.0) [0.0|13407807929942597099574024998205846127479365820592393377723561443721764030073546976801874298166903427690031858186486050853753882811946569946433649006084095] ""  Getriebe_DQ

BO_ 2617228834 XCP_Getriebe_CRO_22: 64 Vector__XXX
 SG_ XCP_Getriebe_CRO_22_Data : 0|512@1+ (1.0,0.0) [0.0|13407807929942597099574024998205846127479365820592393377723561443721764030073546976801874298166903427690031858186486050853753882811946569946433649006084095] ""  Getriebe_DQ

BO_ 2617228836 XCP_Getriebe_CRO_24: 64 Vector__XXX
 SG_ XCP_Getriebe_CRO_24_Data : 0|512@1+ (1.0,0.0) [0.0|13407807929942597099574024998205846127479365820592393377723561443721764030073546976801874298166903427690031858186486050853753882811946569946433649006084095] ""  Getriebe_DQ

BO_ 2617228833 XCP_Getriebe_DTO_21: 64 Getriebe_DQ
 SG_ XCP_Getriebe_DTO_21_Data : 0|512@1+ (1.0,0.0) [0.0|13407807929942597099574024998205846127479365820592393377723561443721764030073546976801874298166903427690031858186486050853753882811946569946433649006084095] ""  Vector__XXX

BO_ 2617228835 XCP_Getriebe_DTO_23: 64 Getriebe_DQ
 SG_ XCP_Getriebe_DTO_23_Data : 0|512@1+ (1.0,0.0) [0.0|13407807929942597099574024998205846127479365820592393377723561443721764030073546976801874298166903427690031858186486050853753882811946569946433649006084095] ""  Vector__XXX

BO_ 2617228837 XCP_Getriebe_DTO_25: 64 Getriebe_DQ
 SG_ XCP_Getriebe_DTO_25_Data : 0|512@1+ (1.0,0.0) [0.0|13407807929942597099574024998205846127479365820592393377723561443721764030073546976801874298166903427690031858186486050853753882811946569946433649006084095] ""  Vector__XXX

BO_ 2617226768 XCP_Motor_CRO_01: 64 Vector__XXX
 SG_ XCP_Motor_CRO_01_Data : 0|64@1+ (1.0,0.0) [0.0|18446744073709551615] ""  Motor_konv

BO_ 2617226769 XCP_Motor_DTO_01: 64 Motor_konv
 SG_ XCP_Motor_DTO_01_Data : 0|64@1+ (1.0,0.0) [0.0|18446744073709551615] ""  Vector__XXX

BO_ 2566734336 XCP_Parksperre_CRO_01: 8 Vector__XXX
 SG_ XCP_Parksperre_CRO_01_Data : 0|64@1+ (1.0,0.0) [0.0|18446744073709551615] ""  Parksperre

BO_ 2566734337 XCP_Parksperre_DTO_01: 8 Parksperre
 SG_ XCP_Parksperre_DTO_01_Data : 0|64@1+ (1.0,0.0) [0.0|18446744073709551615] ""  Vector__XXX

BO_ 388 ZV_01: 8 Gateway_Max
 SG_ ZV_01_CRC : 0|8@1+ (1,0) [0|255] ""  Vector__XXX
 SG_ ZV_01_BZ : 8|4@1+ (1,0) [0|15] ""  Vector__XXX
 SG_ ZV_FT_verriegeln : 12|1@1+ (1.0,0.0) [0.0|1] ""  Vector__XXX
 SG_ ZV_FT_entriegeln : 13|1@1+ (1.0,0.0) [0.0|1] ""  Vector__XXX
 SG_ ZV_BT_verriegeln : 14|1@1+ (1.0,0.0) [0.0|1] ""  Vector__XXX
 SG_ ZV_BT_entriegeln : 15|1@1+ (1.0,0.0) [0.0|1] ""  Vector__XXX
 SG_ ZV_HFS_verriegeln : 16|1@1+ (1.0,0.0) [0.0|1] ""  Vector__XXX
 SG_ ZV_HFS_entriegeln : 17|1@1+ (1.0,0.0) [0.0|1] ""  Vector__XXX
 SG_ ZV_HBFS_verriegeln : 18|1@1+ (1.0,0.0) [0.0|1] ""  Vector__XXX
 SG_ ZV_HBFS_entriegeln : 19|1@1+ (1.0,0.0) [0.0|1] ""  Vector__XXX
 SG_ ZV_zentral_safen : 20|1@1+ (1.0,0.0) [0.0|1] ""  Vector__XXX
 SG_ ZV_zentral_entsafen : 21|1@1+ (1.0,0.0) [0.0|1] ""  Vector__XXX
 SG_ ZV_Spg_Anklappen : 22|1@1+ (1.0,0.0) [0.0|1] ""  Vector__XXX
 SG_ ZV_Softtouch_betaetigt : 23|1@1+ (1.0,0.0) [0.0|1] ""  Vector__XXX
 SG_ ZV_LED_Steuerung : 24|1@1+ (1.0,0.0) [0.0|1] ""  Vector__XXX
 SG_ ZV_LED_Uebernahme : 25|1@1+ (1.0,0.0) [0.0|1] ""  Vector__XXX
 SG_ ZV_auf_FT : 26|1@1+ (1.0,0.0) [0.0|1] ""  Vector__XXX
 SG_ ZV_zu_FT : 27|1@1+ (1.0,0.0) [0.0|1] ""  Vector__XXX
 SG_ ZV_auf_BT : 28|1@1+ (1.0,0.0) [0.0|1] ""  Vector__XXX
 SG_ ZV_zu_BT : 29|1@1+ (1.0,0.0) [0.0|1] ""  Vector__XXX
 SG_ ZV_auf_Kessy : 30|1@1+ (1.0,0.0) [0.0|1] ""  Vector__XXX
 SG_ ZV_zu_Kessy : 31|1@1+ (1.0,0.0) [0.0|1] ""  Vector__XXX
 SG_ ZV_auf_Funk : 32|1@1+ (1.0,0.0) [0.0|1] ""  Vector__XXX
 SG_ ZV_zu_Funk : 33|1@1+ (1.0,0.0) [0.0|1] ""  Vector__XXX
 SG_ VIP_Sensor_betaetigt : 34|1@1+ (1.0,0.0) [0.0|1] ""  Vector__XXX
 SG_ VIP_Freigabe : 35|1@1+ (1.0,0.0) [0.0|1] ""  Vector__XXX
 SG_ ZV_zu_Zeitl_Nachverr : 36|1@1+ (1.0,0.0) [0.0|1] ""  Vector__XXX
 SG_ ZV_HSK_entriegeln : 37|1@1+ (1.0,0.0) [0.0|1] ""  Vector__XXX
 SG_ ZV_HSK_verriegeln : 38|1@1+ (1.0,0.0) [0.0|1] ""  Vector__XXX
 SG_ ZV_Verdeck_zu : 39|1@1+ (1.0,0.0) [0.0|1] ""  Vector__XXX
 SG_ ZV_Verdeck_auf : 40|1@1+ (1.0,0.0) [0.0|1] ""  Vector__XXX
 SG_ FH_FT_hoch : 41|1@1+ (1.0,0.0) [0.0|1] ""  Vector__XXX
 SG_ FH_FT_tief : 42|1@1+ (1.0,0.0) [0.0|1] ""  Vector__XXX
 SG_ FH_BT_hoch : 43|1@1+ (1.0,0.0) [0.0|1] ""  Vector__XXX
 SG_ FH_BT_tief : 44|1@1+ (1.0,0.0) [0.0|1] ""  Vector__XXX
 SG_ FH_HFS_hoch : 45|1@1+ (1.0,0.0) [0.0|1] ""  Vector__XXX
 SG_ FH_HFS_tief : 46|1@1+ (1.0,0.0) [0.0|1] ""  Vector__XXX
 SG_ FH_HBFS_hoch : 47|1@1+ (1.0,0.0) [0.0|1] ""  Vector__XXX
 SG_ FH_HBFS_tief : 48|1@1+ (1.0,0.0) [0.0|1] ""  Vector__XXX
 SG_ BCM_Spg_Synchron : 49|1@1+ (1.0,0.0) [0.0|1] ""  Vector__XXX
 SG_ BCM_BF_Spg_Absenkung : 50|1@1+ (1.0,0.0) [0.0|1] ""  Vector__XXX
 SG_ ZV_Signatur : 51|11@1+ (1,0) [0|2047] ""  Vector__XXX
 SG_ ZV_entriegeln_Anf : 62|1@1+ (1.0,0.0) [0.0|1] ""  Getriebe_DQ
 SG_ ZV_auto_Ansteuerung : 63|1@1+ (1.0,0.0) [0.0|1] ""  Vector__XXX

BO_ 1411 ZV_02: 8 Gateway_Max
 SG_ ZV_verriegeln_Anf : 0|1@1+ (1.0,0.0) [0.0|1] ""  Vector__XXX
 SG_ ZV_STSG_HFS_Anf : 1|1@1+ (1.0,0.0) [0.0|1] ""  Vector__XXX
 SG_ ZV_STSG_HBFS_Anf : 2|1@1+ (1.0,0.0) [0.0|1] ""  Vector__XXX
 SG_ ZV_Anf_Challenge_Auth : 3|1@1+ (1.0,0.0) [0.0|1] ""  Vector__XXX
 SG_ ZV_STSG_Crashzustand : 4|1@1+ (1.0,0.0) [0.0|1] ""  Vector__XXX
 SG_ ZV_STSG_eKiSi_defekt : 5|1@1+ (1.0,0.0) [0.0|1] ""  Vector__XXX
 SG_ ZV_eRWK_Umfeld_Pruefung : 6|1@1+ (1.0,0.0) [0.0|1] ""  Vector__XXX
 SG_ VIP_Sensor_STSG_HFS_betaetigt : 10|1@1+ (1.0,0.0) [0.0|1] ""  Vector__XXX
 SG_ VIP_Sensor_STSG_HBFS_betaetigt : 11|1@1+ (1.0,0.0) [0.0|1] ""  Vector__XXX
 SG_ BCM_FH_Freigabe : 12|1@1+ (1.0,0.0) [0.0|1] ""  Vector__XXX
 SG_ BCM_Komfortfkt_Freigabe : 13|1@1+ (1.0,0.0) [0.0|1] ""  Vector__XXX
 SG_ BCM_HSK_Freigabe : 14|1@1+ (1.0,0.0) [0.0|1] ""  Vector__XXX
 SG_ BCM_Verdeck_Freigabe : 15|1@1+ (1.0,0.0) [0.0|1] ""  Vector__XXX
 SG_ ZV_verriegelt_intern_ist : 16|1@1+ (1.0,0.0) [0.0|1] ""  Vector__XXX
 SG_ ZV_verriegelt_extern_ist : 17|1@1+ (1.0,0.0) [0.0|1] ""  Vector__XXX
 SG_ ZV_verriegelt_intern_soll : 18|1@1+ (1.0,0.0) [0.0|1] ""  Vector__XXX
 SG_ ZV_verriegelt_extern_soll : 19|1@1+ (1.0,0.0) [0.0|1] ""  Vector__XXX
 SG_ ZV_gesafet_extern_ist : 20|1@1+ (1.0,0.0) [0.0|1] ""  Vector__XXX
 SG_ ZV_gesafet_extern_soll : 21|1@1+ (1.0,0.0) [0.0|1] ""  Vector__XXX
 SG_ ZV_Einzeltuerentriegelung : 22|1@1+ (1.0,0.0) [0.0|1] ""  Vector__XXX
 SG_ ZV_Heckeinzelentriegelung : 23|1@1+ (1.0,0.0) [0.0|1] ""  Vector__XXX
 SG_ ZV_FT_offen : 24|1@1+ (1.0,0.0) [0.0|1] ""  Getriebe_DQ,Motor_konv
 SG_ ZV_BT_offen : 25|1@1+ (1.0,0.0) [0.0|1] ""  Motor_konv
 SG_ ZV_HFS_offen : 26|1@1+ (1.0,0.0) [0.0|1] ""  Motor_konv
 SG_ ZV_HBFS_offen : 27|1@1+ (1.0,0.0) [0.0|1] ""  Motor_konv
 SG_ ZV_HD_offen : 28|1@1+ (1.0,0.0) [0.0|1] ""  Motor_konv
 SG_ ZV_HS_offen : 29|1@1+ (1.0,0.0) [0.0|1] ""  Vector__XXX
 SG_ IRUE_aktiv : 30|1@1+ (1.0,0.0) [0.0|1] ""  Vector__XXX
 SG_ DWA_aktiv : 31|1@1+ (1.0,0.0) [0.0|1] ""  Vector__XXX
 SG_ HD_Hauptraste : 32|1@1+ (1.0,0.0) [0.0|1] ""  Vector__XXX
 SG_ HD_Vorraste : 33|1@1+ (1.0,0.0) [0.0|1] ""  Vector__XXX
 SG_ FFB_HDF_Taste : 34|1@1+ (1.0,0.0) [0.0|1] ""  Vector__XXX
 SG_ FFB_Panik_Taste : 35|1@1+ (1.0,0.0) [0.0|1] ""  Vector__XXX
 SG_ FFB_Auf_Taste : 36|1@1+ (1.0,0.0) [0.0|1] ""  Vector__XXX
 SG_ FFB_Zu_Taste : 37|1@1+ (1.0,0.0) [0.0|1] ""  Vector__XXX
 SG_ FFB_CarFinder : 38|1@1+ (1.0,0.0) [0.0|1] ""  Vector__XXX
 SG_ FFB_Komfortoeffnen : 39|1@1+ (1.0,0.0) [0.0|1] ""  Vector__XXX
 SG_ FFB_Komfortschliessen : 40|1@1+ (1.0,0.0) [0.0|1] ""  Vector__XXX
 SG_ FBS_IDG_in_Reichweite : 41|1@1+ (1.0,0.0) [0.0|1] ""  Vector__XXX
 SG_ ZV_Schluessel_Zugang : 42|4@1+ (1.0,0.0) [0.0|15] ""  Vector__XXX
 SG_ ZV_SafeFunktion_aktiv : 46|1@1+ (1.0,0.0) [0.0|1] ""  Vector__XXX
 SG_ FBS_Warn_Schluessel_Batt : 47|1@1+ (1.0,0.0) [0.0|1] ""  Vector__XXX
 SG_ ZV_Oeffnungsmodus : 48|2@1+ (1.0,0.0) [0.0|3] ""  Vector__XXX
 SG_ HFS_verriegelt : 50|1@1+ (1.0,0.0) [0.0|1] ""  Vector__XXX
 SG_ HFS_gesafet : 51|1@1+ (1.0,0.0) [0.0|1] ""  Vector__XXX
 SG_ HBFS_verriegelt : 52|1@1+ (1.0,0.0) [0.0|1] ""  Vector__XXX
 SG_ HBFS_gesafet : 53|1@1+ (1.0,0.0) [0.0|1] ""  Vector__XXX
 SG_ ZV_ist_Zustand_verfuegbar : 54|1@1+ (1.0,0.0) [0.0|1] ""  Vector__XXX
 SG_ IRUE_Taster_Fkts_LED : 55|1@1+ (1.0,0.0) [0.0|1] ""  Vector__XXX
 SG_ ZV_Tankklappe_offen : 56|1@1+ (1.0,0.0) [0.0|1] ""  Vector__XXX
 SG_ ZV_Rollo_auf : 57|1@1+ (1.0,0.0) [0.0|1] ""  Vector__XXX
 SG_ ZV_Rollo_zu : 58|1@1+ (1.0,0.0) [0.0|1] ""  Vector__XXX
 SG_ ZV_SAD_auf : 59|1@1+ (1.0,0.0) [0.0|1] ""  Vector__XXX
 SG_ ZV_SAD_zu : 60|1@1+ (1.0,0.0) [0.0|1] ""  Vector__XXX
 SG_ BCM_Tankklappensteller_Fehler : 61|1@1+ (1.0,0.0) [0.0|1] ""  Vector__XXX
 SG_ ZV_verriegelt_soll : 62|2@1+ (1.0,0.0) [0.0|3] ""  Vector__XXX

BO_TX_BU_ 181 :Gateway_Max,Schaltbetaetigung;
BO_TX_BU_ 2463978687 :Gateway_Max,Schaltbetaetigung;
CM_ BO_ 916 "ersetzt WBA_02";
CM_ BO_ 1702 "MLBevo";

CM_ SG_ 313 HMS_aktives_System "Zeigt an, von welchem System die Anforderung gerade umgesetzt wird.";
CM_ SG_ 313 HMS_Anforderung_GE "Fordert vom Getriebe bestimmte Schaltstellungen an.";
CM_ SG_ 313 HMS_Fehlerstatus "Zeigt den Fehlerstatus des Haltemanagementsystems HMS an.
Details zu den Werten 3/4:
3=Systemeinschränkung, Parken EPB oder GSG nicht möglich
4=Systemstörung bzw. Parken EPB und GSG nicht möglich  ";
CM_ SG_ 313 HMS_Haltemoment "Zeigt in Abhängigkeit von HMS_Index_Haltemoment das notwendige Summen-Radmoment an (bergab: Bremsmoment; bergauf: Antriebsmoment), das mindestens notwendig ist um das Fahrzeug an der aktuellen Neigung zu halten.";
CM_ SG_ 313 HMS_halten_nicht_verfuegbar "Rueckmeldung HMS-Teilfunktion 'Halten' nicht verfuegbar.";
CM_ SG_ 313 HMS_halten_nicht_verfuegbar_02 "Erweiterung des Signals 'HMS_halten_nicht_verfuegbar':
Für Remotevorgänge (Ein-, Ausparken, etc.) ohne anwesenden Fahrer soll das Signal eine Halteverfügbarkeit signalisieren durch 'verfuegbar_ohne_Fahrer'.";
CM_ SG_ 313 HMS_Index_Haltemoment "Zeigt an, ob das Summen-HMS_Haltemoment ein Bremsmoment (bergab) oder ein Antriebsmoment (bergauf) darstellt.";
CM_ SG_ 313 HMS_P_beibehalten_GE "Fordert das Getriebe auf in Stellung 'P' zu bleiben.";
CM_ SG_ 313 HMS_parken_nicht_verfuegbar "Rueckmeldung HMS-Teilfunktionen 'Parken' nicht verfuegbar.";
CM_ SG_ 313 HMS_Stillstand "Das Signal zeigt, basierend auf den vier ESP-Raddrehzahlinformatioen, gefiltert und/oder entprellt mehrstufig den Fahrzeuggeschwindigkeitszustand an.";
CM_ SG_ 313 HMS_Systemstatus "Zeigt den aktuellen Systemstatus des HMS an.";
CM_ SG_ 313 SOK_VMM_02_Signatur "Signatur im Rahmen der durch SOK geschützten Broadcast-Kommunikation

Geschützte Funktionen: Airbag-Funktionen, Bremsfunktionen
Geschützte Botschaft: VMM_02";
CM_ SG_ 313 VMM_02_BZ "4bit Botschaftszähler, wird mit jeder Sendebotschaft inkrementiert";
CM_ SG_ 313 VMM_02_CRC "Für MLB:
Berechnung siehe Lastenheft 'Kommunikationsabsicherung für FlexRay und CAN'
Ab MQB und MLBevo:
Berechnung siehe Lastenheft 'End-to-End Kommunikationsabsicherung'

Endwerte siehe Begleitdokument 'S-PDU Kennungsfolgen'";
CM_ SG_ 313 VMM_Bremslicht_defekt "Rückmeldung ob beide Bremslichter defekt sind. Bei gestecktem Anhänger werden die Anhängerbremslichter ausgewertet.";
CM_ SG_ 313 VMM_Bremslicht_unplausibel "Bremslichtplausibilität aus Basis der CAN Anforderung";
CM_ SG_ 313 VMM_Fahrer_Bremskraft_bestimmend "Dieses Signal gibt eine Rückmeldung ob der Fahrer stärker bremst als die angeforderte Bremsung.";
CM_ SG_ 313 VMM_Inkonsistenz_ACC "Rückmeldung Inkonsistenz ACC";
CM_ SG_ 313 VMM_Inkonsistenz_AEB "Rückmeldung Inkonsistenz vom AEB";
CM_ SG_ 313 VMM_Inkonsistenz_ARA "Rückmeldung Inkonsistenz ARA 1.0";
CM_ SG_ 313 VMM_Inkonsistenz_AWV_PCF "Rückmeldung Inkonsistenz AWV PCF";
CM_ SG_ 313 VMM_Inkonsistenz_EA "Rückmeldung Inkonsistenz EA";
CM_ SG_ 313 VMM_Inkonsistenz_EBKV "Rückmeldung Inkonsistenz EBKV";
CM_ SG_ 313 VMM_Inkonsistenz_FAS_VK "Rückmeldung Inkonsistenz Fahrerassistenzsystem";
CM_ SG_ 313 VMM_Inkonsistenz_GE "Zeigt an, ob die Kommunikation und die Anforderungen plausibel sind.";
CM_ SG_ 313 VMM_Inkonsistenz_HVLM "Rückmeldung Inkonsistenz HVLM";
CM_ SG_ 313 VMM_Inkonsistenz_KAM "Rückmeldung Inkonsistenz der Kamera";
CM_ SG_ 313 VMM_Inkonsistenz_KAS "Rückmeldung Inkonsistenz KAS";
CM_ SG_ 313 VMM_Inkonsistenz_MO "Rückmeldung Inkonsistenz MO";
CM_ SG_ 313 VMM_Inkonsistenz_NV "Rückmeldung Inkonsistenz Nightvision";
CM_ SG_ 313 VMM_Inkonsistenz_ParkAssist "Rückmeldung Inkonsistenz der Parkenden Systeme";
CM_ SG_ 313 VMM_Inkonsistenz_RCTA "Rückmeldung Inkonsistenz des RCTA";
CM_ SG_ 313 VMM_Inkonsistenz_RHP "Rückmeldung Inkonsistenz RHP (Rush Hour pilot).";
CM_ SG_ 313 VMM_Inkonsistenz_TSK "Rückmeldung Inkonsistenz TSK";
CM_ SG_ 313 VMM_Inkonsistenz_VLK "Rückmeldung Inkonsistenz VLK";
CM_ SG_ 313 VMM_MKB_codiert "Das Signal kennzeichnet den Codierstatus des ESC-SG bzgl. der Funktion Multikollisionsbremse.";
CM_ SG_ 313 VMM_Notstopp_Status "Status des Notstoppsystems";
CM_ SG_ 313 VZM_aktiver_Basisservice "In diesem Signal wird der aktive Basisservice des Verzögerungsmanagement zurück gegeben.";
CM_ SG_ 313 VZM_aktives_System "Rückmeldung über das  aktiv anfordernde System bei dem Verzögerungsmanagement.";
CM_ SG_ 313 VZM_Anhalteweg_nicht_verfuegbar "Rückmeldung ob die Anhaltewegregelung verfügbar ist.";
CM_ SG_ 313 VZM_Bkd_nicht_verfuegbar "Dieses Signal gibt eine Rückmeldung ob eine Bremsenkonditionierung (Prefill und Systemtotzeitminimierung) verfügbar ist.";
CM_ SG_ 313 VZM_Fahrer_bremst "Bit wird gesetzt beim Überschreiten der Bremsdruckschwelle

Weiterführende Informationen im Lastenheft spezifiziert und in der entsprechenden Fachabteilung zu erfragen.";
CM_ SG_ 313 VZM_Fahrer_bremst_deutlich "Rückmeldung an AWV ob der Fahrer das Bremspedal deutlich betätigt hat";
CM_ SG_ 313 VZM_QBit_Fahrer_bremst "Gültigkeit der Bremsdruckschwelleninformation des Signals VZM_Fahrer_bremst und VZM_Fahrer_bremst_deutlich
0x1 = Druckschwelleninformation kann noch nicht oder aufgrund eines Fehlers nicht ausgegeben werden";
CM_ SG_ 313 VZM_SRBM_Ist "Gibt das aktuelle Summenradbremsmoment aus.";
CM_ SG_ 313 VZM_SRBM_max_Gradient "Rückmeldung aktueller Maximalgradient";
CM_ SG_ 313 VZM_SRBM_Soll "Gibt das angeforderte Summenradbremsmoment aus.";
CM_ SG_ 313 VZM_Status_Wegregelung "Rückmeldung der Wegregelung ob dieser Service Inaktiv, aktiv oder passiv ist.
Bei Passiv_Überwachend Bremseingriff durch VZM im Notfall möglich.";
CM_ SG_ 313 VZM_Systemstatus "In diesem Signal wird der aktuelle Systemstatus des Verzögerungsmanagments ausgeben.";
CM_ SG_ 313 VZM_TSK_SRBM_Anf "Quittierung für TSK (SRBM = Summenradbremsmoment) Anforderung";
CM_ SG_ 313 VZM_TSK_SRBM_nicht_verfuegbar "Rückmeldung ob das ein Summenradbremsmoment angefordert werden kann.";
CM_ SG_ 313 VZM_Unterdrueckung_Antriebsmom "Mit diesem Signal wird dem TSK signalisiert ob ein positives Antriebsmoment angefordert werden kann. In einer Notbremsung ist das positive Antriebsmoment zu unterdrücken.";
CM_ SG_ 313 VZM_Verz_ASIL_Verfuegbarkeit "Dieses Signal gibt die Rückmeldung in welchem ASIL Bereich aktuell verzögert wird.";
CM_ SG_ 313 VZM_Verz_Begrenzung "Rückmeldung angeforderte Verzögerung oder Summenradbremsmoment wird begrenzt umgesetzt";
CM_ SG_ 313 VZM_Verz_Reg_aktiv "Rueckmeldung Verzoegerungsregelung aktiv";
CM_ SG_ 313 VZM_Verz_Reg_nicht_verfuegbar "In diesem Signal wird ausgegeben ob eine Verzögerungsregelung verfügbar ist.";
CM_ SG_ 313 VZM_Warnruck_nicht_verfuegbar "Rückmeldung ob ein einfacher Warnruck angefordert werden kann.";
CM_ SG_ 313 VZM_Warnruckeln_nicht_verfuegbar "Rückmeldung ob mehrfach ein Warnruck durchgeführt werden kann.";

CM_ SG_ 2331595858 vREM_Abstand_P0 "Abstand zur REM Geschwindigkeit von Punkt Px";
CM_ SG_ 2331595858 vREM_Abstand_P1 "Abstand zur REM Geschwindigkeit von Punkt Px";
CM_ SG_ 2331595858 vREM_Abstand_P10 "Abstand zur REM Geschwindigkeit von Punkt Px";
CM_ SG_ 2331595858 vREM_Abstand_P11 "Abstand zur REM Geschwindigkeit von Punkt Px";
CM_ SG_ 2331595858 vREM_Abstand_P12 "Abstand zur REM Geschwindigkeit von Punkt Px";
CM_ SG_ 2331595858 vREM_Abstand_P13 "Abstand zur REM Geschwindigkeit von Punkt Px";
CM_ SG_ 2331595858 vREM_Abstand_P14 "Abstand zur REM Geschwindigkeit von Punkt Px";
CM_ SG_ 2331595858 vREM_Abstand_P15 "Abstand zur REM Geschwindigkeit von Punkt Px";
CM_ SG_ 2331595858 vREM_Abstand_P16 "Abstand zur REM Geschwindigkeit von Punkt Px";
CM_ SG_ 2331595858 vREM_Abstand_P17 "Abstand zur REM Geschwindigkeit von Punkt Px";
CM_ SG_ 2331595858 vREM_Abstand_P18 "Abstand zur REM Geschwindigkeit von Punkt Px";
CM_ SG_ 2331595858 vREM_Abstand_P19 "Abstand zur REM Geschwindigkeit von Punkt Px";
CM_ SG_ 2331595858 vREM_Abstand_P2 "Abstand zur REM Geschwindigkeit von Punkt Px";
CM_ SG_ 2331595858 vREM_Abstand_P20 "Abstand zur REM Geschwindigkeit von Punkt Px";
CM_ SG_ 2331595858 vREM_Abstand_P21 "Abstand zur REM Geschwindigkeit von Punkt Px";
CM_ SG_ 2331595858 vREM_Abstand_P22 "Abstand zur REM Geschwindigkeit von Punkt Px";
CM_ SG_ 2331595858 vREM_Abstand_P23 "Abstand zur REM Geschwindigkeit von Punkt Px";
CM_ SG_ 2331595858 vREM_Abstand_P24 "Abstand zur REM Geschwindigkeit von Punkt Px";
CM_ SG_ 2331595858 vREM_Abstand_P25 "Abstand zur REM Geschwindigkeit von Punkt Px";
CM_ SG_ 2331595858 vREM_Abstand_P26 "Abstand zur REM Geschwindigkeit von Punkt Px";
CM_ SG_ 2331595858 vREM_Abstand_P27 "Abstand zur REM Geschwindigkeit von Punkt Px";
CM_ SG_ 2331595858 vREM_Abstand_P28 "Abstand zur REM Geschwindigkeit von Punkt Px";
CM_ SG_ 2331595858 vREM_Abstand_P29 "Abstand zur REM Geschwindigkeit von Punkt Px";
CM_ SG_ 2331595858 vREM_Abstand_P3 "Abstand zur REM Geschwindigkeit von Punkt Px";
CM_ SG_ 2331595858 vREM_Abstand_P4 "Abstand zur REM Geschwindigkeit von Punkt Px";
CM_ SG_ 2331595858 vREM_Abstand_P5 "Abstand zur REM Geschwindigkeit von Punkt Px";
CM_ SG_ 2331595858 vREM_Abstand_P6 "Abstand zur REM Geschwindigkeit von Punkt Px";
CM_ SG_ 2331595858 vREM_Abstand_P7 "Abstand zur REM Geschwindigkeit von Punkt Px";
CM_ SG_ 2331595858 vREM_Abstand_P8 "Abstand zur REM Geschwindigkeit von Punkt Px";
CM_ SG_ 2331595858 vREM_Abstand_P9 "Abstand zur REM Geschwindigkeit von Punkt Px";
CM_ SG_ 2331595858 vREM_Akt_Zaehler "4-bit Überlaufcounter zwischen MFK und Frontradar";
CM_ SG_ 2331595858 vREM_Status "Status der REM Geschwindigkeit";

CM_ SG_ 2331595859 vREM_Geschw_P0 "Aktuell gültige REM Geschwindigkeit bei Punkt Px";
CM_ SG_ 2331595859 vREM_Geschw_P1 "Aktuell gültige REM Geschwindigkeit bei Punkt Px";
CM_ SG_ 2331595859 vREM_Geschw_P10 "Aktuell gültige REM Geschwindigkeit bei Punkt Px";
CM_ SG_ 2331595859 vREM_Geschw_P11 "Aktuell gültige REM Geschwindigkeit bei Punkt Px";
CM_ SG_ 2331595859 vREM_Geschw_P12 "Aktuell gültige REM Geschwindigkeit bei Punkt Px";
CM_ SG_ 2331595859 vREM_Geschw_P13 "Aktuell gültige REM Geschwindigkeit bei Punkt Px";
CM_ SG_ 2331595859 vREM_Geschw_P14 "Aktuell gültige REM Geschwindigkeit bei Punkt Px";
CM_ SG_ 2331595859 vREM_Geschw_P15 "Aktuell gültige REM Geschwindigkeit bei Punkt Px";
CM_ SG_ 2331595859 vREM_Geschw_P16 "Aktuell gültige REM Geschwindigkeit bei Punkt Px";
CM_ SG_ 2331595859 vREM_Geschw_P17 "Aktuell gültige REM Geschwindigkeit bei Punkt Px";
CM_ SG_ 2331595859 vREM_Geschw_P18 "Aktuell gültige REM Geschwindigkeit bei Punkt Px";
CM_ SG_ 2331595859 vREM_Geschw_P19 "Aktuell gültige REM Geschwindigkeit bei Punkt Px";
CM_ SG_ 2331595859 vREM_Geschw_P2 "Aktuell gültige REM Geschwindigkeit bei Punkt Px";
CM_ SG_ 2331595859 vREM_Geschw_P20 "Aktuell gültige REM Geschwindigkeit bei Punkt Px";
CM_ SG_ 2331595859 vREM_Geschw_P21 "Aktuell gültige REM Geschwindigkeit bei Punkt Px";
CM_ SG_ 2331595859 vREM_Geschw_P22 "Aktuell gültige REM Geschwindigkeit bei Punkt Px";
CM_ SG_ 2331595859 vREM_Geschw_P23 "Aktuell gültige REM Geschwindigkeit bei Punkt Px";
CM_ SG_ 2331595859 vREM_Geschw_P24 "Aktuell gültige REM Geschwindigkeit bei Punkt Px";
CM_ SG_ 2331595859 vREM_Geschw_P25 "Aktuell gültige REM Geschwindigkeit bei Punkt Px";
CM_ SG_ 2331595859 vREM_Geschw_P26 "Aktuell gültige REM Geschwindigkeit bei Punkt Px";
CM_ SG_ 2331595859 vREM_Geschw_P27 "Aktuell gültige REM Geschwindigkeit bei Punkt Px";
CM_ SG_ 2331595859 vREM_Geschw_P28 "Aktuell gültige REM Geschwindigkeit bei Punkt Px";
CM_ SG_ 2331595859 vREM_Geschw_P29 "Aktuell gültige REM Geschwindigkeit bei Punkt Px";
CM_ SG_ 2331595859 vREM_Geschw_P3 "Aktuell gültige REM Geschwindigkeit bei Punkt Px";
CM_ SG_ 2331595859 vREM_Geschw_P4 "Aktuell gültige REM Geschwindigkeit bei Punkt Px";
CM_ SG_ 2331595859 vREM_Geschw_P5 "Aktuell gültige REM Geschwindigkeit bei Punkt Px";
CM_ SG_ 2331595859 vREM_Geschw_P6 "Aktuell gültige REM Geschwindigkeit bei Punkt Px";
CM_ SG_ 2331595859 vREM_Geschw_P7 "Aktuell gültige REM Geschwindigkeit bei Punkt Px";
CM_ SG_ 2331595859 vREM_Geschw_P8 "Aktuell gültige REM Geschwindigkeit bei Punkt Px";
CM_ SG_ 2331595859 vREM_Geschw_P9 "Aktuell gültige REM Geschwindigkeit bei Punkt Px";

CM_ SG_ 2463978663 VZE_Akustik_Limitwechsel "Anforderung eines Signaltons bei Tempolimitwechsel.";
CM_ SG_ 2463978663 VZE_Akustik_Limitwechsel_Status "Das Signal überträgt die Information, ob der Kunde, in den Einstellungen, die akustische Information, bei einem Tempolimitwechsel, ausgewählt hat.";
CM_ SG_ 2463978663 VZE_Anhaenger_Vmax "Übertragung der aus Kundeneinstellung und länderspezifischen Regelungen (StVO, Rechtsprechung...) berechneten legalen Höchstgeschwindigkeit für das Gespann.

10+ 0*10 = 10 km/h
10+ 1*10 = 20 km/h
...
10+ 5*10 = 60 km/h
10+ 6*10 = 70 km/h
...
10+ 1";
CM_ SG_ 2463978663 VZE_Anzeige_VZ_1 "Das Signal spiegelt eines der Verkehrszeichen: Geschwindigkeitsgebot, Überholverbot, Aufhebungszeichen wider.

Wertebereich lt. Hashtabelle";
CM_ SG_ 2463978663 VZE_Anzeige_VZ_2 "Das Signal spiegelt eines der Verkehrszeichen: Geschwindigkeitsgebot, Überholverbot, Aufhebungszeichen wider.

Wertebereich lt. Hashtabelle";
CM_ SG_ 2463978663 VZE_Anzeige_VZ_3 "Das Signal spiegelt eines der Verkehrszeichen: Geschwindigkeitsgebot, Überholverbot, Aufhebungszeichen wider.

Wertebereich lt. Hashtabelle";
CM_ SG_ 2463978663 VZE_Anzeige_ZS_1 "Zusatzsschild, das zu Verkehrszeichen 1 angezeigt werden soll.

Wertebereich lt. Hashtabelle";
CM_ SG_ 2463978663 VZE_Anzeige_ZS_2 "Zusatzsschild, das zu Verkehrszeichen 1 angezeigt werden soll.

Wertebereich lt. Hashtabelle";
CM_ SG_ 2463978663 VZE_Anzeige_ZS_3 "Zusatzsschild, das zu Verkehrszeichen 1 angezeigt werden soll.

Wertebereich lt. Hashtabelle";
CM_ SG_ 2463978663 VZE_Anzeigemodus "Steuert die verschiedenen Möglichkeiten der Anzeige.";
CM_ SG_ 2463978663 VZE_Anzeigeunterdrueck_Zeichen_1 "Steuerungssignal zur Steuerung der Sichtbarkeit von Verkehrszeichen ";
CM_ SG_ 2463978663 VZE_Anzeigeunterdrueck_Zeichen_2 "Anzeigerelevanz des Zeichens in VZE_Verkehrszeichen_2";
CM_ SG_ 2463978663 VZE_Anzeigeunterdrueck_Zeichen_3 "Anzeigerelevanz des Zeichens in VZE_Verkehrszeichen_3";
CM_ SG_ 2463978663 VZE_Anzeigeunterdrueck_Zeichen_4 "Anzeigerelevanz des Zeichens in VZE_Anzeigerelevanz_Zeichen_4";
CM_ SG_ 2463978663 VZE_Anzeigeunterdrueck_Zeichen_5 "Anzeigerelevanz des Zeichens in VZE_Anzeigerelevanz_Zeichen_5";
CM_ SG_ 2463978663 VZE_Baustelle "Das Signal gibt an, ob aktuell ein Baustellenschild von der VZE erkannt wurde.";
CM_ SG_ 2463978663 VZE_Erweiterte_Information "In dem Signal spiegelt erweiterte Verkehrszeicheninformationen wieder (Ortsschild, Autobahnbeginn, Autobahnende)

Wertebereich lt. Hashtabelle";
CM_ SG_ 2463978663 VZE_FoD_Status "Status der VZE für FoD";
CM_ SG_ 2463978663 VZE_Gong "Das Signal signalisiert dem Kombiinstrument ob bei der VZE-Tempowarnung ein Gong getriggert werden soll.";
CM_ SG_ 2463978663 VZE_Hinweistext "Über Index wird ein Hinweistext beschrieben, der durch das Kombi dargestellte werden soll.

Wertebereich lt. Hashtabelle";
CM_ SG_ 2463978663 VZE_Hinweistext_03 "Über Index wird ein Hinweistext beschrieben, der durch das Kombi dargestellte werden soll.

Wertebereich lt. Hashtabelle";
CM_ SG_ 2463978663 VZE_Land "Steuert die verschiedenen Möglichkeiten der Anzeige.";
CM_ SG_ 2463978663 VZE_Modus_OptischeWarnung "Das Signal gibt an, ob eine optische Warnung blinkend oder dauerhaft ausgegeben werden soll.";
CM_ SG_ 2463978663 VZE_SLWF_Status "Das Signal zeigt den SLWF Zustand der VZE an.";
CM_ SG_ 2463978663 VZE_Tempowarnung_Einheit "0 - Einheit Warnoffset km/h
1 -  Einheit Warnoffset mph";
CM_ SG_ 2463978663 VZE_Tempowarnung_Offset "das Signal überträgt den im CAR:Menü gewählten Offset für die VZE-Tempowarnung an das pACC Steuergerät. Die zugrhörige Einheit wird im Signal VZE_Tempowarnung_Einheit übertragen";
CM_ SG_ 2463978663 VZE_Tempowarnung_Status "0 - Tempowarnung aktiv
1 -  Tempowarnung desktiv";
CM_ SG_ 2463978663 VZE_Umweltinfo_Anhaengerbetrieb "In dem Signal werden für die Verkehrszeichenerkennung relevante Umweltinformationen übertragen.

Info: Anhängerbetrieb";
CM_ SG_ 2463978663 VZE_Umweltinfo_Naesse "In dem Signal werden für die Verkehrszeichenerkennung relevante Umweltinformationen übertragen.

Info: Nässe";
CM_ SG_ 2463978663 VZE_Umweltinfo_Nebel "In dem Signal werden für die Verkehrszeichenerkennung relevante Umweltinformationen übertragen.

Info: Nebel";
CM_ SG_ 2463978663 VZE_Verkehrszeichen_1 "Das Signal spiegelt eines der Verkehrszeichen: Geschwindigkeitsgebot, Überholverbot, Aufhebungszeichen wider.

Wertebereich lt. Hashtabelle";
CM_ SG_ 2463978663 VZE_Verkehrszeichen_2 "Das Signal spiegelt eines der Verkehrszeichen: Geschwindigkeitsgebot, Überholverbot, Aufhebungszeichen wider.

Wertebereich lt. Hashtabelle";
CM_ SG_ 2463978663 VZE_Verkehrszeichen_3 "Das Signal spiegelt eines der Verkehrszeichen: Geschwindigkeitsgebot, Überholverbot, Aufhebungszeichen wider.

Wertebereich lt. Hashtabelle";
CM_ SG_ 2463978663 VZE_Verkehrszeichen_4 "Das Signal spiegelt eines der Verkehrszeichen: Geschwindigkeitsgebot, Überholverbot, Aufhebungszeichen wider.

Wertebereich lt. Hashtabelle";
CM_ SG_ 2463978663 VZE_Verkehrszeichen_5 "Das Signal spiegelt eines der Verkehrszeichen: Geschwindigkeitsgebot, Überholverbot, Aufhebungszeichen wider.

Wertebereich lt. Hashtabelle";
CM_ SG_ 2463978663 VZE_Verkehrszeichen_6 "Das Signal spiegelt eines der Verkehrszeichen: Geschwindigkeitsgebot, Überholverbot, Aufhebungszeichen wider.

Wertebereich lt. Hashtabelle";
CM_ SG_ 2463978663 VZE_Verkehrszeichen_Einheit "Signal gibt an ob das übertragene Verkehrszeichen in mph oder km/h übermittelt wird";
CM_ SG_ 2463978663 VZE_Warnung_Verkehrszeichen_1 "Ist das Signal gesetzt, so ist für das Verkehrszeichen 1 eine Warnung auszugeben.";
CM_ SG_ 2463978663 VZE_Warnung_Verkehrszeichen_2 "Ist das Signal gesetzt, so ist für das Verkehrszeichen 2 eine Warnung auszugeben.";
CM_ SG_ 2463978663 VZE_Warnung_Verkehrszeichen_3 "Ist das Signal gesetzt, so ist für das Verkehrszeichen 3 eine Warnung auszugeben.";
CM_ SG_ 2463978663 VZE_Warnung_Verkehrszeichen_4 "Ist das Signal gesetzt, so ist für das Verkehrszeichen 4 eine Warnung auszugeben.";
CM_ SG_ 2463978663 VZE_Warnung_Verkehrszeichen_5 "Ist das Signal gesetzt, so ist für das Verkehrszeichen 5 eine Warnung auszugeben.";
CM_ SG_ 2463978663 VZE_Warnung_VZ_1 "Ist das Signal gesetzt, so ist für das Verkehrszeichen 1 eine Warnung auszugeben.";
CM_ SG_ 2463978663 VZE_Warnung_VZ_2 "Ist das Signal gesetzt, so ist für das Verkehrszeichen 1 eine Warnung auszugeben.";
CM_ SG_ 2463978663 VZE_Warnung_VZ_3 "Ist das Signal gesetzt, so ist für das Verkehrszeichen 1 eine Warnung auszugeben.";
CM_ SG_ 2463978663 VZE_Zeichen_01_Gesetz "Das VZE-Tempolimit in Verkehrszeichen1  ist das gesetzlich geltende Tempolimit (je Land/Straßenklasse).";
CM_ SG_ 2463978663 VZE_Zeichen_01_Kamera "Das VZE-Tempolimit in Verkehrszeichen1 wurde von der Kamera erkannt.";
CM_ SG_ 2463978663 VZE_Zeichen_01_KameraWied "Das VZE-Tempolimit  in Verkehrszeichen1 wurde als Wiederholungsschild von der Kamera erkannt.";
CM_ SG_ 2463978663 VZE_Zeichen_01_Karte "Das VZE-Tempolimit in Verkehrszeichen1 stammt aus den Navigationskartendaten.";
CM_ SG_ 2463978663 VZE_Zeichen_02_Gesetz "Das VZE-Tempolimit in Verkehrszeichen2  ist das gesetzlich geltende Tempolimit (je Land/Straßenklasse).";
CM_ SG_ 2463978663 VZE_Zeichen_02_Kamera "Das VZE-Tempolimit in Verkehrszeichen2 wurde von der Kamera erkannt.";
CM_ SG_ 2463978663 VZE_Zeichen_02_KameraWied "Das VZE-Tempolimit  in Verkehrszeichen2 wurde als Wiederholungsschild von der Kamera erkannt.";
CM_ SG_ 2463978663 VZE_Zeichen_02_Karte "Das VZE-Tempolimit in Verkehrszeichen2 stammt aus den Navigationskartendaten.";
CM_ SG_ 2463978663 VZE_Zeichen_03_Gesetz "Das VZE-Tempolimit in Verkehrszeichen3  ist das gesetzlich geltende Tempolimit (je Land/Straßenklasse).";
CM_ SG_ 2463978663 VZE_Zeichen_03_Kamera "Das VZE-Tempolimit in Verkehrszeichen3 wurde von der Kamera erkannt.";
CM_ SG_ 2463978663 VZE_Zeichen_03_KameraWied "Das VZE-Tempolimit  in Verkehrszeichen3 wurde als Wiederholungsschild von der Kamera erkannt.";
CM_ SG_ 2463978663 VZE_Zeichen_03_Karte "Das VZE-Tempolimit in Verkehrszeichen3 stammt aus den Navigationskartendaten.";
CM_ SG_ 2463978663 VZE_Zeichen_04_Gesetz "Das VZE-Tempolimit ist das gesetzlich geltende Tempolimit (je Land/Straßenklasse).";
CM_ SG_ 2463978663 VZE_Zeichen_04_Kamera "Das VZE-Tempolimit wurde von der Kamera erkannt.";
CM_ SG_ 2463978663 VZE_Zeichen_04_KameraWied "Das VZE-Tempolimit wurde als Wiederholungsschild von der Kamera erkannt.";
CM_ SG_ 2463978663 VZE_Zeichen_04_Karte "Das VZE-Tempolimit stammt aus den Navigationskartendaten.";
CM_ SG_ 2463978663 VZE_Zeichen_05_Entfernung "In dem Signal wird die Entfernung zum Verkehrszeichen5 übertragen";
CM_ SG_ 2463978663 VZE_Zeichen_05_Entfernung_StdA "In dem Signal wird die Standardabweichung bzgl. der Entfernung zum Verkehrszeichen5 übertragen ";
CM_ SG_ 2463978663 VZE_Zeichen_05_Gesetz "Das VZE-Tempolimit ist das gesetzlich geltende Tempolimit (je Land/Straßenklasse).";
CM_ SG_ 2463978663 VZE_Zeichen_05_Kamera "Das VZE-Tempolimit wurde von der Kamera erkannt.";
CM_ SG_ 2463978663 VZE_Zeichen_05_KameraWied "Das VZE-Tempolimit wurde als Wiederholungsschild von der Kamera erkannt.";
CM_ SG_ 2463978663 VZE_Zeichen_05_Karte "Das VZE-Tempolimit stammt aus den Navigationskartendaten.";
CM_ SG_ 2463978663 VZE_Zeichen_06_Entfernung "In dem Signal wird die Entfernung zum Verkehrszeichen6 übertragen";
CM_ SG_ 2463978663 VZE_Zeichen_06_Entfernung_StdA "In dem Signal wird die Standardabweichung bzgl. der Entfernung zum Verkehrszeichen6 übertragen ";
CM_ SG_ 2463978663 VZE_Zusatzschild_1 "Zusatzsschild, das zu Verkehrszeichen 1 angezeigt werden soll.

Wertebereich lt. Hashtabelle";
CM_ SG_ 2463978663 VZE_Zusatzschild_2 "Zusatzsschild, das zu Verkehrszeichen 2 angezeigt werden soll.

Wertebereich lt. Hashtabelle";
CM_ SG_ 2463978663 VZE_Zusatzschild_3 "Zusatzsschild, das zu Verkehrszeichen 3 angezeigt werden soll.

Wertebereich lt. Hashtabelle";
CM_ SG_ 2463978663 VZE_Zusatzschild_4 "Zusatzsschild, das zu Verkehrszeichen 4 angezeigt werden soll.

Wertebereich lt. Hashtabelle";
CM_ SG_ 2463978663 VZE_Zusatzschild_5 "Zusatzsschild, das zu Verkehrszeichen 5 angezeigt werden soll.

Wertebereich lt. Hashtabelle";
CM_ SG_ 2463978663 VZE_Zusatzschild_6 "Zusatzsschild, das zu Verkehrszeichen 6 angezeigt werden soll.

Wertebereich lt. Hashtabelle";

CM_ SG_ 181 Waehlhebel_04_CRC "Für MLB:
'Berechnung siehe Lastenheft 'Kommunikationsabsicherung für FlexRay und CAN''

Ab MQB und MLBevo:
'Berechnung siehe Lastenheft 'End-to-End Kommunikationsabsicherung''

Endwerte siehe Begleitdokument 'S-PDU Kennungsfolgen'";
CM_ SG_ 181 WH_Ende_N_Haltephase "Signalisiert dem Getriebe/ASG das Ende der N-Haltephase, damit die Parksperre eingelegt werden kann.";
CM_ SG_ 181 WH_Entsperrtaste_02 "Das Bit zeigt den entprellten Status der Entsperrtaste am Wählhebel an, inklusive Fehler- und Init-Zuständen.";
CM_ SG_ 181 WH_Fahrstufe "Fahrstufenwunsch der Schaltbetätigung (berechnet aus Fahreraktion am Bedienelement)";
CM_ SG_ 181 WH_gespeicherte_Fahrstufe "Kurzzeit-Fahrstufenspeicherung in Abhängigkeit von GE_Ist_Fahrstufe.";
CM_ SG_ 181 WH_Initialisierung "Das Bit zeigt dem Empfänger an, dass der Wählhebel in der Initialisierung ist (z.B. Reset). Das Signal steht für maximal 500ms ab Sendebeginn auf 1, danach dauerhaft auf 0.";
CM_ SG_ 181 WH_Ist_Haltemagnet "Status der Ansteuerung des Parksperren - Haltemagneten im Waehlhebel";
CM_ SG_ 181 WH_P_Taste "Das Signal zeigt den Status der P-Taste an.";
CM_ SG_ 181 WH_SensorPos_roh "Zustand Wählhebelposition. Wird das Signal WH_Variante nicht bedient, ist die Signalcodierung 
wie im MQB zu verwenden.

MQB:
0=Init
1=Position_1
2=Position_2
3=Position_3
4=nicht_betaetigt
5=Position_D
6=Position_N
7=Position_R
8=Position_P
";
CM_ SG_ 181 WH_SensorPos_roh_inv "Zustand Wählhebelposition. Wird das Signal WH_Variante nicht bedient, ist die Signalcodierung 
wie im MQB zu verwenden.

MQB:
0=Fehler
1=Position_Tipp_Gasse
2=Position_L
3=Position_S
4=Position_Tipp_-
5=Position_Tipp_+
6=Position_N_ohne_Spotausl";
CM_ SG_ 181 WH_Status_Shiftlock "Status des Hardware-Shiftlocks (die Schaltbetätigung kann in P oder N gesperrt werden)";
CM_ SG_ 181 WH_Test_Aktiv "Das Bit wird auf 1 gesetzt, wenn ein gültiges Testergebnis (Antwort) gesendet wird.";
CM_ SG_ 181 WH_Testergebnis "Ergebnis (Antwort) des Controllertests initiert durch Test Freigabe Flag
und Testparameter 1 + 2";
CM_ SG_ 181 WH_Variante "Verwendete Schaltungs-Variante im Fahrzeug
Beschreibung:

Rastierter Wählhebel
Übermittlung Absolutpositionen P,R,N,D,S,M

Tasten:
Übermittlung Absolutpositionen P,R,N,D

Monostabil_2x2:
Übermittlung Relativpositionen, Entsperrtaste und P-Taste";
CM_ SG_ 181 WH_Zustand_N_Haltephase "Signalisiert dem Schaltbetätigungsmaster (GSG bzw. ASG), in welchem Zustand sich die N-Haltephase in der Schaltbetätigung befindet. Abhängig davon fordert der Schaltbetätigungsmster P an oder behält N bei.";
CM_ SG_ 181 WH_Zustand_N_Haltephase_2 "Signalisiert dem Schaltbetaetigungsmaster den Zustand der N Haltephase";

CM_ SG_ 2589283476 WH_FSA_HMI_Meldungen_01 "FuRe Fahrstufenauswahl: Fahrerhinweise für das HMI";
CM_ SG_ 2589283476 WH_Schaltschema_Orientierung "Gibt für die Schaltschemaanzeige im Kombi an, wie die Fahrstufen auf der Schaltbetätigung positioniert sind. Die erstgenannte Fahrstufe liegt 'vorne' (in Kombianzeige 'oben'), die letztgenannte 'hinten' (in Kombianzeige 'unten'). Das Signal ist nur im Zus";
CM_ SG_ 2589283476 WH_Verbau_Entsperrtaste "Zeigt dem Kombi-Instument den Verbau der Entsperrtaste in der Schaltbetätigung an.
Diese Info wird benötigt, um zwischen „Zum Einlegen einer Fahrstufe Fußbremse betätigen' und „Zum Einlegen einer Fahrstufe Fußbremse UND ENTSPERRTASTE betätigen“ untersche";
CM_ SG_ 2589283476 WH_Warnung_02 "Warnmeldungen vom Waehlhebel an das Kombi";
CM_ SG_ 2589283476 WH_Warnung_03 "Warnungen des CGS im Lambo Urus";

CM_ SG_ 2463978687 WH_Fehler_Ausleuchtung "Fehler in der Ausleuchtung der Fahrstufe erkannt";
CM_ SG_ 2463978687 WH_Fehler_Ausleuchtung_Status "Status des Tests 'Fehler in der Ausleuchtung der Fahrstufe erkannt'";
CM_ SG_ 2463978687 WH_Fehler_BZ_SBM "Fehler des Botschaftszählers des Schaltbetätigungsmasters erkannt";
CM_ SG_ 2463978687 WH_Fehler_BZ_SBM_Status "Status des Tests 'Fehler des Botschaftszählers des Schaltbetätigungsmasters erkannt'";
CM_ SG_ 2463978687 WH_Fehler_CRC_SBM "Fehler der Checksumme des Schaltbetätigungsmasters erkannt";
CM_ SG_ 2463978687 WH_Fehler_CRC_SBM_Status "Status des Tests 'Fehler der Checksumme des Schaltbetätigungsmasters erkannt'";
CM_ SG_ 2463978687 WH_Fehler_Entsperrtaste "Fehler der Entsperrtaste erkannt";
CM_ SG_ 2463978687 WH_Fehler_Entsperrtaste_Status "Status des Tests 'Fehler der Entsperrtaste erkannt'";
CM_ SG_ 2463978687 WH_Fehler_Haltemagnet "Elektrischer_Fehler_Ansteuerung_Haltemagnet erkannt";
CM_ SG_ 2463978687 WH_Fehler_Haltemagnet_Status "Status des Tests 'Elektrischer Fehler Haltemagnetansteuerung'";
CM_ SG_ 2463978687 WH_Fehler_P_Taste "Fehler der P-Taste erkannt";
CM_ SG_ 2463978687 WH_Fehler_P_Taste_Status "Status des Tests 'Fehler der P-Taste erkannt'";
CM_ SG_ 2463978687 WH_Fehler_Sensor_einfach "Einfacher Positionssensorfehler erkannt";
CM_ SG_ 2463978687 WH_Fehler_Sensor_einfach_Status "Status des Tests 'einfacher Positionssensorfehler erkannt'";
CM_ SG_ 2463978687 WH_Fehler_Sensor_mehrfach "Mehrfacher Positionssensorfehler erkannt";
CM_ SG_ 2463978687 WH_Fehler_Sensor_mehrfach_Status "Status des Tests 'mehrfacher Positionssensorfehler erkannt'";
CM_ SG_ 2463978687 WH_Fehler_Shiftlock "Fehler Hardware-Shiftlock erkannt";
CM_ SG_ 2463978687 WH_Fehler_Shiftlock_Status "Status des Tests 'Fehler Hardware-Shiftlock erkannt'";
CM_ SG_ 2463978687 WH_Fehler_Timeout_SBM "Timeout des Schaltbetätigungsmasters erkannt";
CM_ SG_ 2463978687 WH_Fehler_Timeout_SBM_Status "Status des Tests 'Timeout des Schaltbetätigungsmasters erkannt'";
CM_ SG_ 2463978687 WH_Fehler_Ueberspannung "Ueberspannungsfehler erkannt";
CM_ SG_ 2463978687 WH_Fehler_Ueberspannung_Status "Status des Tests 'Ueberspannungsfehler erkannt'";
CM_ SG_ 2463978687 WH_Fehler_Unterspannung "Unterspannungsfehler erkannt";
CM_ SG_ 2463978687 WH_Fehler_Unterspannung_Status "Status des Tests 'Unterspannungsfehler erkannt'";

CM_ SG_ 916 GE_Sollgang "Signalisiert den Sollgang, in den getippt werden soll. Abhängig vom Signal 'WBA_eing_Gang_02' und dem Sollgang kann dann das Kombi die Hochschaltempfehlung in Tip darstellen.";
CM_ SG_ 916 GE_Stoppverbot_Anz_01 "Dieses Signal gibt die detaillierte Begründung für ein Stoppverbot vom Getriebesteuergerät an.";
CM_ SG_ 916 GE_Stoppverbot_Anz_02 "Dieses Signal gibt die detaillierte Begründung für ein Stoppverbot vom Getriebesteuergerät an.";
CM_ SG_ 916 GE_Stoppverbot_Anz_03 "Dieses Signal gibt die detaillierte Begründung für ein Stoppverbot vom Getriebesteuergerät an.";
CM_ SG_ 916 GE_Stoppverbot_Anz_04 "Dieses Signal gibt die detaillierte Begründung für ein Stoppverbot vom Getriebesteuergerät an.";
CM_ SG_ 916 GE_Stoppverbot_Anz_05 "Dieses Signal gibt die detaillierte Begründung für ein Stoppverbot vom Getriebesteuergerät an.";
CM_ SG_ 916 GE_Stoppverbot_Anz_06 "Dieses Signal gibt die detaillierte Begründung für ein Stoppverbot vom Getriebesteuergerät an.";
CM_ SG_ 916 GE_Stoppverbot_Anz_07 "Dieses Signal gibt die detaillierte Begründung für ein Stoppverbot vom Getriebesteuergerät an.";
CM_ SG_ 916 GE_Stoppverbot_Anz_Std "Dieses Signal gibt die detaillierte Begründung für ein Stoppverbot vom Getriebesteuergerät an.";
CM_ SG_ 916 GE_Tipschaltempf_verfuegbar "Signalisierung, ob eine Hochschaltempfehlung im Tipmodus verfügbar ist oder nicht.";
CM_ SG_ 916 GE_Wiederstart_Anz_Std "Dieses Signal gibt die detaillierte Begründung für einen Wiederstart vom Getriebesteuergerät an. ";
CM_ SG_ 916 WBA_03_CRC "Für MLB:
'Berechnung siehe Lastenheft 'Kommunikationsabsicherung für FlexRay und CAN''

Ab MQB und MLBevo:
'Berechnung siehe Lastenheft 'End-to-End Kommunikationsabsicherung''

Endwerte siehe Begleitdokument 'S-PDU Kennungsfolgen'";
CM_ SG_ 916 WBA_Anforderung_Akustik "Anforderung eines Signaltons bei Anwahl der Fahrstufe R";
CM_ SG_ 916 WBA_Blinken "Dieses Bit steuert die Fehlerlampe an oder wird zum Blinken der WBA-Anzeige genutzt - nur falls WBA_Senderkennung = 00 (GSG)
";
CM_ SG_ 916 WBA_eing_Gang_02 "Das Automatikgetriebe gibt den aktuell eingelegten Gang aus.
Besonderheiten:
0x0 = marktabhängig wird auf Ganganzeige zur Fahrstufe komplett verzichtet
0xA = kurzzeitige Unterdrückung der Ganganzeige (z. B. Segeln, Zwischenstellung, etc.)";
CM_ SG_ 916 WBA_Fahrstufe_02 "Bei Automatgetrieben wird in diesem Signal die aktuelle anzuzeigende Fahrstufe ausgegeben.

Die Signalkodierungen 0x9, 0xA und 0xB werden im MSS-R8NF und MQB-A1/B/A2 verwendet.

Die Signalkodierungen 0xC und 0xD werden nur im MQB-A1/B/A2 verwendet.
";
CM_ SG_ 916 WBA_GE_Texte "Fahrerhinweise für das Kombi";
CM_ SG_ 916 WBA_GE_Texte_02 "Fahrerhinweise für das Kombi";
CM_ SG_ 916 WBA_GE_Warnung_02 "Prioritätswarnungen Getriebe";
CM_ SG_ 916 WBA_GE_Zusatzwarnungen "Prioritaetswarnungen Getriebe an Kombi
Audi MLB Wertebereich 0 bis 3
VW MQB Projekte verwenden nur den Wertebereich 0 bis 2
VW MQB Getriebefehler werden über das Signal  GE_Warnungen_02 gesendet.";
CM_ SG_ 916 WBA_Schaltschema_02 "Basis-Layout des Schaltschemas zur Anzeige im Kombiinstrument";
CM_ SG_ 916 WBA_Schaltschema_Fahreraktion "Signalisiert Fahreraktion an der Schaltbetaetigung";
CM_ SG_ 916 WBA_Schaltschema_FS_inaktiv "Gibt an, welche Fahrstufen innerhalb von WBA_Schaltschema_02 aktuell nicht erreichbar sind (z.B. aufgrund zu hoher Fahrzeuggeschwindigkeit oder fehlender Fahrbereitschaft).";
CM_ SG_ 916 WBA_Schaltschema_FS_vorwaerts "Zeigt an, welche der zwei Vorwärtsfahrstufen aktiv ist und ob in die inaktive geschaltet werden kann.";
CM_ SG_ 916 WBA_Schaltschema_Tippgasse "Zeigt den Verbau einer Tippgasse zur Anzeige im Schaltschema an.";
CM_ SG_ 916 WBA_Segeln_aktiv "Getriebe geht in den Segelbetrieb";
CM_ SG_ 916 WBA_Shiftlock_Lampe "Signalisiert dem Kombi, dass die Shiftlock-Lampe (grünes 'Bremse treten' Symbol) anzuzeigen ist.

Anmerkung: Signal ist nur von Kombis auszuwerten, die die Shiftlock-Info über Soft- oder Hard-LED und nicht als reine Textmeldung anzeigen.";
CM_ SG_ 916 WBA_ZielFahrstufe "Zielfahrprogramm (Darstellung), für getipptes S/E/M mit neuem Wählhebel im MQB";

CM_ SG_ 1361 WFS_Betrieb_Lesespule "Schlüsselkommunikation über die Lesespule";
CM_ SG_ 1361 WFS_ELV_authorisiert "Authorisierung der elektrischen Lenkungsverriegelung an der WFS";
CM_ SG_ 1361 WFS_Fahrerhinweise "Meldungen, Fahrer- und Warnhinweise der Wegfahrsperre";
CM_ SG_ 1361 WFS_ID_Geb_autorisiert "Authorisierung Schluessel (ID-Geber)";
CM_ SG_ 1361 WFS_ID_Geb_autorisiert_in_Kl15 "Authorisierung des Schlüssels im aktiven Klemme-15-Zyklus";
CM_ SG_ 1361 WFS_ID_Geb_steckt "Schluessel (ID-Geber) im Zuendschloss
";
CM_ SG_ 1361 WFS_Klemmenfreigabe "Freigabe von der WFS zum Einschalten der Klemme 15 und Klemme S";
CM_ SG_ 1361 WFS_Klemmenfreigabe_Signatur "Signatur zur Klemmenfreigabe durch die WFS";
CM_ SG_ 1361 WFS_LF_Aktiv "LF Schluesselkommunikation
";
CM_ SG_ 1361 WFS_LZ "Anforderung aus Lastenheft WFS V
";
CM_ SG_ 1361 WFS_Parken_Status "Schnittstelle zwischen WFS und ZFAS für das Pilotierte Parken um in Richtung ZFAS den Status der WFS im BCM2 zu kommunizieren";
CM_ SG_ 1361 WFS_Safe "Status WFS";
CM_ SG_ 1361 WFS_Schluessel_Fahrberecht "Schlüsselnummer Fahrberechtigung
0 = ungueltig, xxxx = Schluessel-Nr.";
CM_ SG_ 1361 WFS_Schluessel_Ist "Istwert der gelernten Schluessel";
CM_ SG_ 1361 WFS_Schluessel_Soll "Sollwert der zu lernenden Schluessel";
CM_ SG_ 1361 WFS_Verbauinfo_ELV "Info über die Konfiguration der ELV im WFS-Master";

CM_ SG_ 1702 BCM1_SRA_aktiv "Status Scheinwerferreinigungsanlage";
CM_ SG_ 1702 Heckwischer_Anforderung "Das Signal beschreibt die Anforderung an den Signalausgang im BCM2 zur Ansteuerung des Heckwischers.";
CM_ SG_ 1702 Waschen_vorne_aktiv "Status: Waschen vorne aktiv";
CM_ SG_ 1702 Wischer1_Wischgeschwindigkeit "aktuelle, durch Sensorik gemessene Wischgeschwindigkeit";
CM_ SG_ 1702 Wischer_Anzeigetext "Das Signal fordert einen Kombi-Pop-Up mit entsprechenden Texten an";
CM_ SG_ 1702 Wischer_vorne_aktiv "Status: Wischer vorne";
CM_ SG_ 1702 Wischer_vorne_blockiert "Blockade Wischer vorne (z.B. durch Schnee)";
CM_ SG_ 1702 Wischer_vorne_defekt "Fehlerstatus Wischer vorne (Anzeige im Kombi)";
CM_ SG_ 1702 Wischer_vorne_Normal "Wischer Front normal aktiv";
CM_ SG_ 1702 Wischer_vorne_Parklage "Wischer Front in Parklage";
CM_ SG_ 1702 Wischer_vorne_Schnell "Wischer vorne schnell aktiv";
CM_ SG_ 1702 Wischer_WH_PopUp_Anf "Anzeige von Wischerstufen im Kombi.";
CM_ SG_ 1702 Wischer_WH_Typ "Signal beinhaltet Lenkstockschaltertyp für grafische Anzeige im Kombi zur Wischerfunktion";
CM_ SG_ 1702 WWSs_01_alt "Veraltet Bit für die LIN-Botschaft WWSs_01.

Betroffene Signale:

Wischer_vorne_aktiv";

CM_ SG_ 1602 WIV_Russindex "Nur für Diesel, Rußwert, bei Otto Wert = 0";
CM_ SG_ 1602 WIV_t_max "Maximales Wartungsintervall für WIV in Monaten";
CM_ SG_ 1602 WIV_t_min "Minimales Wartungsintervall für WIV in Monaten";
CM_ SG_ 1602 WIV_Verschleissindex "Bei Otto Verbrauch, bei Diesel Verschleiss";
CM_ SG_ 1602 WIV_W_max "Maximales Wartungsintervall für WIV in km";
CM_ SG_ 1602 WIV_W_min "Minimales Wartungsintervall für WIV in km";

CM_ SG_ 2617226768 XCP_Motor_CRO_01_Data "INCA -> MSG";

CM_ SG_ 2617226769 XCP_Motor_DTO_01_Data "MSG -> INCA";

CM_ SG_ 388 BCM_BF_Spg_Absenkung "Spiegelabsenkung Beifahrerseite";
CM_ SG_ 388 BCM_Spg_Synchron "Anforderung zur Aktivierung der synchronen Spiegelverstellung";
CM_ SG_ 388 FH_BT_hoch "Freigabeinformation fuer die FH-Komfortfunktion";
CM_ SG_ 388 FH_BT_tief "Freigabeinformation fuer die FH-Komfortfunktion";
CM_ SG_ 388 FH_FT_hoch "Freigabeinformation fuer die FH-Komfortfunktion";
CM_ SG_ 388 FH_FT_tief "Freigabeinformation fuer die FH-Komfortfunktion";
CM_ SG_ 388 FH_HBFS_hoch "Freigabeinformation fuer die FH-Komfortfunktion";
CM_ SG_ 388 FH_HBFS_tief "Freigabeinformation fuer die FH-Komfortfunktion";
CM_ SG_ 388 FH_HFS_hoch "Freigabeinformation fuer die FH-Komfortfunktion";
CM_ SG_ 388 FH_HFS_tief "Freigabeinformation fuer die FH-Komfortfunktion";
CM_ SG_ 388 VIP_Freigabe "Vituelles Pedal ist über HMI freigeschaltet.";
CM_ SG_ 388 VIP_Sensor_betaetigt "Heckentriegelung durch die Bedienstelle Virtuelles Pedal(VIP) erkannt. Der VIP Sensor hat eine Fusskickbewegung erkannt und es wurde ein Kessy - Schlüssel im Heckaussenbereich erkannt.";
CM_ SG_ 388 ZV_01_CRC "Für MLB:
'Berechnung siehe Lastenheft 'Kommunikationsabsicherung für FlexRay und CAN''

Ab MQB und MLBevo:
'Berechnung siehe Lastenheft 'End-to-End Kommunikationsabsicherung''

Endwerte siehe Begleitdokument 'S-PDU Kennungsfolgen'";
CM_ SG_ 388 ZV_auf_BT "ZV Schliessstelle";
CM_ SG_ 388 ZV_auf_FT "ZV Schliessstelle";
CM_ SG_ 388 ZV_auf_Funk "ZV Schliessstelle";
CM_ SG_ 388 ZV_auf_Kessy "ZV Schliessstelle";
CM_ SG_ 388 ZV_auto_Ansteuerung "Kennung für die automatische Ansteuerung der Zentralverriegelung (Autolock/Autounlock)";
CM_ SG_ 388 ZV_BT_entriegeln "Beifahrertür entriegeln (Anforderung ZV)";
CM_ SG_ 388 ZV_BT_verriegeln "Verriegelungsanforderung ZV für BT";
CM_ SG_ 388 ZV_entriegeln_Anf "Bei ZV Anforderung erfolgt die Entriegelung des Ladesteckers";
CM_ SG_ 388 ZV_FT_entriegeln "Entriegelungsanforderung ZV für FT";
CM_ SG_ 388 ZV_FT_verriegeln "Verriegelungsanforderung ZV für FT";
CM_ SG_ 388 ZV_HBFS_entriegeln "Entriegelungsanforderung ZV für HBFS
";
CM_ SG_ 388 ZV_HBFS_verriegeln "Verriegelungsanforderung ZV für HBFS
";
CM_ SG_ 388 ZV_HFS_entriegeln "Entriegelungsanforderung ZV für HFS
";
CM_ SG_ 388 ZV_HFS_verriegeln "Verriegelungsanforderung ZV für HFS
";
CM_ SG_ 388 ZV_HSK_entriegeln "Anforderungssignal zur Ansteuerung des Handschuhkastenmotors in Richtung Entriegeln. ";
CM_ SG_ 388 ZV_HSK_verriegeln "Anforderungssignal zur Ansteuerung des Handschuhkastenmotors in Richtung Verriegeln. ";
CM_ SG_ 388 ZV_LED_Steuerung "Ansteuerung der LED's in den Tueren; BAF gilt nicht für dieses Bit";
CM_ SG_ 388 ZV_LED_Uebernahme "Uebernahme der LED Steuerung durch das TSG FT";
CM_ SG_ 388 ZV_Signatur "Signatur der ZV";
CM_ SG_ 388 ZV_Softtouch_betaetigt "Betätigung Softtouch";
CM_ SG_ 388 ZV_Spg_Anklappen "Anforderung über ZV: Spiegel sind anzuklappen";
CM_ SG_ 388 ZV_Verdeck_auf "Anforderungssignal für ein Komfortöffnen des Verdecks. 
Signal wird angefordert wenn  SKontakt = 0 und eine Doppelbetätigung Schließzylinder_auf oder Funkfernbedienung_Taste_auf  innerhalb zwei Sekunden empfangen wird. Signal wird auch angefordert wenn S";
CM_ SG_ 388 ZV_Verdeck_zu "Anforderungssignal für ein Komfortschließen des Verdecks. 
Signal wird angefordert wenn  SKontakt = 0 und eine Doppelbetätigung Schließzylinder_Zu oder Funkfernbedienung_Taste_zu  innerhalb zwei Sekunden empfangen wird. Signal wird auch angefordert wenn ";
CM_ SG_ 388 ZV_zentral_entsafen "Zentral entsafen";
CM_ SG_ 388 ZV_zentral_safen "Zentral safen";
CM_ SG_ 388 ZV_zu_BT "ZV Schliessstelle";
CM_ SG_ 388 ZV_zu_FT "ZV Schliessstelle";
CM_ SG_ 388 ZV_zu_Funk "ZV Schliessstelle";
CM_ SG_ 388 ZV_zu_Kessy "ZV Schliessstelle";
CM_ SG_ 388 ZV_zu_Zeitl_Nachverr "ZV Schliessstelle";

CM_ SG_ 1411 BCM_FH_Freigabe "Funktionsfreigabe Fensterheber";
CM_ SG_ 1411 BCM_HSK_Freigabe "Handschuhkastenfreigabe";
CM_ SG_ 1411 BCM_Komfortfkt_Freigabe "globale Freigabe der Komfortfunktion";
CM_ SG_ 1411 BCM_Tankklappensteller_Fehler "Fehler: nicht Funktionalität des Tankklappenstellers";
CM_ SG_ 1411 BCM_Verdeck_Freigabe "Freigabe Verdeckbetrieb
";
CM_ SG_ 1411 DWA_aktiv "Status DWA  aktiv";
CM_ SG_ 1411 FBS_IDG_in_Reichweite "Für elektrisch betätigte Türen und Klappen muss für eine Betätigung über Funk eine Reichweitenbegrenzung eingeführt werden. Diese Bit zeigt an, dass sich der Funkschlüssel innerhalb der geforderten Reichweite befindet";
CM_ SG_ 1411 FBS_Warn_Schluessel_Batt "Kombi Prio Warnung Schluessel Batterie
'Bitte Schlüsselbatterie wechseln!'";
CM_ SG_ 1411 FFB_Auf_Taste "Auf-Taste Funkschluessel

";
CM_ SG_ 1411 FFB_CarFinder "Car Finder Funktion (Blinken ohne zu entriegeln)";
CM_ SG_ 1411 FFB_HDF_Taste "HDF Taste am Funkschluessel
";
CM_ SG_ 1411 FFB_Komfortoeffnen "Komfortoeffnen Funk
";
CM_ SG_ 1411 FFB_Komfortschliessen "Komfortschliessen Funk
";
CM_ SG_ 1411 FFB_Panik_Taste "Panik Taste Funkschluessel
";
CM_ SG_ 1411 FFB_Zu_Taste "Zu-Taste Funkschluessel
";
CM_ SG_ 1411 HBFS_gesafet "HBFS Tuer gesafet.
Im Zustand Safe wird auch das Signal HBFS_verriegelt = 1 gesendet.";
CM_ SG_ 1411 HBFS_verriegelt "Verriegelungsstatus Tür";
CM_ SG_ 1411 HD_Hauptraste "SBL-Schloss (MQB/MLBevo): Drehfalle Heckdeckel
sonst (MQB): Hauptraste Heckdeckel";
CM_ SG_ 1411 HD_Vorraste "SBL_Schloss (MQB/MLBevo): Sperrklinke Heckdeckel
sonst (MQB): Vorraste Heckdeckel";
CM_ SG_ 1411 HFS_gesafet "HFS Tuer gesafet.
Im Zustand Safe wird auch das Signal HFS_verriegelt = 1 gesendet.";
CM_ SG_ 1411 HFS_verriegelt "HFS Tuer verriegelt";
CM_ SG_ 1411 IRUE_aktiv "Status Innenraumüberwachung
";
CM_ SG_ 1411 IRUE_Taster_Fkts_LED "Anforderung Funktions-LED IRUE-Taster (LED wird vom TSG angesteuert)
MQB: Bei Verbau eines einzelnen Taster zur Deaktivierung von IRUE und NGS wird dieses Signal zur Ansteuerung der Funktions-LED gesendet.";
CM_ SG_ 1411 VIP_Sensor_STSG_HBFS_betaetigt "Schiebetürlauf HBFS wurde durch VIP angefordert und als berechtigt eingestuft.";
CM_ SG_ 1411 VIP_Sensor_STSG_HFS_betaetigt "Schiebetürlauf HFS wurde durch VIP angefordert und als berechtigt eingestuft.";
CM_ SG_ 1411 ZV_Anf_Challenge_Auth "Anforderung an alle beteiligten Steuergeräte die Challenge an den ZV-Master zu senden.";
CM_ SG_ 1411 ZV_BT_offen "gespiegeltes Bit BT_Tuer_geoeffnet TSG_BT_1 Botschaft";
CM_ SG_ 1411 ZV_Einzeltuerentriegelung "Einzeltürentriegelung ZV
";
CM_ SG_ 1411 ZV_eRWK_Umfeld_Pruefung "Anforderung an PDC/PLA im eRWK-Modus eine Umfeldprüfung durchzuführen";
CM_ SG_ 1411 ZV_FT_offen "gespiegeltes Bit FT_Tuer_geoeffnet TSG_FT_1 Botschaft";
CM_ SG_ 1411 ZV_gesafet_extern_ist "Istzustand: Fahrzeug aussen gesafet
";
CM_ SG_ 1411 ZV_gesafet_extern_soll "Sollzustand: Fahrzeug gesafet extern
";
CM_ SG_ 1411 ZV_HBFS_offen "gespiegeltes Bit HBFS_Tuer_geoeffnet TSG_HBFS_1 Botschaft";
CM_ SG_ 1411 ZV_HD_offen "Status Heckdeckel
";
CM_ SG_ 1411 ZV_Heckeinzelentriegelung "Heckdeckeleinzelentriegelung";
CM_ SG_ 1411 ZV_HFS_offen "gespiegeltes Bit HFS_Tuer_geoeffnet TSG_HFS_1 Botschaft";
CM_ SG_ 1411 ZV_HS_offen "Status Heckscheibe
";
CM_ SG_ 1411 ZV_ist_Zustand_verfuegbar "Verfügbarkeit IST-Zustand ZV

";
CM_ SG_ 1411 ZV_Oeffnungsmodus "Konfigurierter Oeffnungsmodus fuer ZV:
0 = globale Oeffnung (alle Tueren)
1 = ZV mit Einzeltuerentriegelung (FFB - nur Fahrertuer, Kessy - nur bediente Tuer)
2 = ZV individuell selektive Oeffnung (FFB - Fahrerseite, Kessy - bediente Tuer + Fahrertuer)";
CM_ SG_ 1411 ZV_Rollo_auf "Komfortöffnen des Dachrollos";
CM_ SG_ 1411 ZV_Rollo_zu "Komfortschließen des Dachrollos";
CM_ SG_ 1411 ZV_SAD_auf "Komfortöffnen des Schiebeausstelldaches";
CM_ SG_ 1411 ZV_SAD_zu "Komfortschließen des Schiebeausstelldaches";
CM_ SG_ 1411 ZV_SafeFunktion_aktiv "Statusübermittlung ob die Safe Funktion im Fzg. aktiv ist. Das Kombi benötigt das Signal, um den Text Safelock aktiv anzuzeigen. ";
CM_ SG_ 1411 ZV_Schluessel_Zugang "aktuelle Funkschlüsselnummer";
CM_ SG_ 1411 ZV_STSG_Crashzustand "Statusübermittlung ob der Crashzustand der Schiebetüren dauerhaft im Fzg. aktiv ist. Das Kombi benötigt das Signal, um die Meldung anzuzeigen.";
CM_ SG_ 1411 ZV_STSG_eKiSi_defekt "Statusübermittlung ob die elektronische Kindersicherung der Schiebetüren im Fzg. defekt ist. Das Kombi benötigt das Signal, um die Meldung anzuzeigen.";
CM_ SG_ 1411 ZV_STSG_HBFS_Anf "Die ZV fordert einen Lauf bzw. Stopp der Schiebetür an.";
CM_ SG_ 1411 ZV_STSG_HFS_Anf "Die ZV fordert einen Lauf bzw. Stopp der Schiebetür an.";
CM_ SG_ 1411 ZV_Tankklappe_offen "Öffnungsstatus der Tankklappe";
CM_ SG_ 1411 ZV_verriegeln_Anf "Gesammelte externe ZV-Verriegelungsanforderung des Kunden (z. B. zur Aktivierung der Anzeige des Ladezustands über Aussenlicht).";
CM_ SG_ 1411 ZV_verriegelt_extern_ist "Istzustand: Verriegelung Fahrzeug aussen
";
CM_ SG_ 1411 ZV_verriegelt_extern_soll "Sollzustand: Verriegelung Fahrzeug aussen
";
CM_ SG_ 1411 ZV_verriegelt_intern_ist "Istzustand: Verriegelung Fahrzeug innen
";
CM_ SG_ 1411 ZV_verriegelt_intern_soll "Sollzustand: Verriegelung Fahrzeug innen
";
CM_ SG_ 1411 ZV_verriegelt_soll "Fahrzeug Gesamtverriegelungsstatus Sollzustand für Ladestecker- und Ladeklappenverriegelung. ";
BA_DEF_REL_ BU_SG_REL_  "GenSigTimeoutTime" INT 0 65535;
BA_DEF_ BO_  "DiagRequest" ENUM "No", "Yes";
BA_DEF_ BO_  "DiagResponse" ENUM "No", "Yes";
BA_DEF_ BO_  "DiagState" ENUM "No", "Yes";
BA_DEF_ BO_  "GenMsgChkConstant" HEX 0 4095;
BA_DEF_ BO_  "GenMsgCycleTime" INT 0 65535;
BA_DEF_ BO_  "GenMsgCycleTimeFast" INT 0 65535;
BA_DEF_ BO_  "GenMsgDelayTime" INT 0 100000;
BA_DEF_ BO_  "GenMsgILSupport" ENUM "No", "Yes";
BA_DEF_ BO_  "GenMsgNrOfRepetition" INT 0 100;
BA_DEF_ BO_  "GenMsgPDUConstants" STRING;
BA_DEF_ BO_  "GenMsgSendType" ENUM "Cyclic", "not_used", "not_used", "not_used", "not_used", "not_used", "not_used", "IfActive", "NoMsgSendType";
BA_DEF_ BO_  "GenMsgStartDelayTime" INT 0 100000;
BA_DEF_ BO_  "NmMessage" ENUM "No", "Yes";
BA_DEF_ BO_  "NmhMessage" ENUM "No", "Yes";
BA_DEF_ BO_  "MsgType" ENUM "Application", "NM ", "NMH", "TP2.0", "ISO-TP ", "BAP", "EID", "KS", "XCP_PRE_CONFIGURED", "XCP_RUNTIME_CONFIGURED";
BA_DEF_ BO_  "VAGTP20_API" HEX 0 255;
BA_DEF_ BO_  "VAGTP20_DynConnection" ENUM "No", "Yes";
BA_DEF_ BO_  "VAGTP20_DynSetup" ENUM "No", "Yes";
BA_DEF_ BO_  "VAGTP20_StatConnection" ENUM "No", "Yes";
BA_DEF_ BO_  "CANFD_BRS" ENUM "0", "1";
BA_DEF_ BO_  "VFrameFormat" ENUM "StandardCAN", "ExtendedCAN", "reserved", "reserved", "reserved", "reserved", "reserved", "reserved", "reserved", "reserved", "reserved", "reserved", "reserved", "reserved", "StandardCAN_FD", "ExtendedCAN_FD";
BA_DEF_ SG_  "GenSigActiveRepetitions" INT -2147483648 2147483647;
BA_DEF_ SG_  "GenSigInactiveValue" INT -2147483648 2147483647;
BA_DEF_ SG_  "GenSigSendType" ENUM "Cyclic", "OnWrite", "OnWriteWithRepetition", "OnChange", "OnChangeWithRepetition", "IfActive", "IfActiveWithRepetition", "NoSigSendType", "OnChangeAndIfActive", "OnChangeAndIfActiveWithRepetition";
BA_DEF_ SG_  "GenSigStartValue" INT -2147483648 2147483647;
BA_DEF_ SG_  "NWM-WakeupAllowed" ENUM "No", "Yes";
BA_DEF_ SG_  "GenSigFuncType" ENUM "NoFunction", "MsgCounter", "CRC-8", "XOR", "XOR-2", "DatedBit", "SW-Kl15", "CHK", "Constant", "Protocol", "CRC-8-SAE_J1850", "CRC-32", "DataLength", "DataID", "MsgCounter16", "SOK-Signatur", "Cluster";
BA_DEF_ SG_  "GenSigSwitchedByIgnition" ENUM "No", "Yes";
BA_DEF_ SG_  "Fehlerwert" HEX 0 2147483647;
BA_DEF_ SG_  "GenSigMissingSourceValue" HEX 0 2147483647;
BA_DEF_DEF_REL_  "GenSigTimeoutTime" 0;
BA_DEF_DEF_  "DiagRequest" "No";
BA_DEF_DEF_  "DiagResponse" "No";
BA_DEF_DEF_  "DiagState" "No";
BA_DEF_DEF_  "GenMsgChkConstant" 0;
BA_DEF_DEF_  "GenMsgCycleTime" 0;
BA_DEF_DEF_  "GenMsgCycleTimeFast" 0;
BA_DEF_DEF_  "GenMsgDelayTime" 0;
BA_DEF_DEF_  "GenMsgILSupport" "No";
BA_DEF_DEF_  "GenMsgNrOfRepetition" 0;
BA_DEF_DEF_  "GenMsgPDUConstants" "";
BA_DEF_DEF_  "GenMsgSendType" "NoMsgSendType";
BA_DEF_DEF_  "GenMsgStartDelayTime" 0;
BA_DEF_DEF_  "NmMessage" "No";
BA_DEF_DEF_  "NmhMessage" "No";
BA_DEF_DEF_  "MsgType" "Application";
BA_DEF_DEF_  "VAGTP20_API" 0;
BA_DEF_DEF_  "VAGTP20_DynConnection" "No";
BA_DEF_DEF_  "VAGTP20_DynSetup" "No";
BA_DEF_DEF_  "VAGTP20_StatConnection" "No";
BA_DEF_DEF_  "CANFD_BRS" "1";
BA_DEF_DEF_  "VFrameFormat" "StandardCAN";
BA_DEF_DEF_  "GenSigActiveRepetitions" 0;
BA_DEF_DEF_  "GenSigInactiveValue" 0;
BA_DEF_DEF_  "GenSigSendType" "NoSigSendType";
BA_DEF_DEF_  "GenSigStartValue" 0;
BA_DEF_DEF_  "NWM-WakeupAllowed" "No";
BA_DEF_DEF_  "GenSigFuncType" "NoFunction";
BA_DEF_DEF_  "GenSigSwitchedByIgnition" "Yes";
BA_DEF_DEF_  "Fehlerwert" 0;
BA_DEF_DEF_  "GenSigMissingSourceValue" 0;
BA_ "GenMsgCycleTime" BO_ 313 20;
BA_ "GenMsgILSupport" BO_ 313 1;
BA_ "GenMsgPDUConstants" BO_ 313 "0x96,0x92,0x95,0xb5,0x6e,0xe3,0xbd,0xb4,0xfa,0xae,0xbe,0xcb,0xcf,0xa5,0x77,0xef";
BA_ "GenMsgSendType" BO_ 313 0;
BA_ "VFrameFormat" BO_ 313 14;
BA_ "GenMsgCycleTime" BO_ 2331595858 40;
BA_ "GenMsgILSupport" BO_ 2331595858 1;
BA_ "GenMsgSendType" BO_ 2331595858 0;
BA_ "VFrameFormat" BO_ 2331595858 15;
BA_ "GenMsgCycleTime" BO_ 2331595859 40;
BA_ "GenMsgILSupport" BO_ 2331595859 1;
BA_ "GenMsgSendType" BO_ 2331595859 0;
BA_ "VFrameFormat" BO_ 2331595859 15;
BA_ "GenMsgCycleTime" BO_ 2463978663 200;
BA_ "GenMsgDelayTime" BO_ 2463978663 40;
BA_ "GenMsgILSupport" BO_ 2463978663 1;
BA_ "GenMsgSendType" BO_ 2463978663 0;
BA_ "VFrameFormat" BO_ 2463978663 15;
BA_ "GenMsgChkConstant" BO_ 181 228;
BA_ "GenMsgCycleTime" BO_ 181 10;
BA_ "GenMsgILSupport" BO_ 181 1;
BA_ "GenMsgPDUConstants" BO_ 181 "0xe4,0xe4,0xe4,0xe4,0xe4,0xe4,0xe4,0xe4,0xe4,0xe4,0xe4,0xe4,0xe4,0xe4,0xe4,0xe4";
BA_ "GenMsgSendType" BO_ 181 0;
BA_ "VFrameFormat" BO_ 181 14;
BA_ "GenMsgCycleTime" BO_ 2589283476 1000;
BA_ "GenMsgDelayTime" BO_ 2589283476 100;
BA_ "GenMsgILSupport" BO_ 2589283476 1;
BA_ "GenMsgSendType" BO_ 2589283476 0;
BA_ "VFrameFormat" BO_ 2589283476 15;
BA_ "GenMsgCycleTime" BO_ 2463978687 1000;
BA_ "GenMsgDelayTime" BO_ 2463978687 100;
BA_ "GenMsgILSupport" BO_ 2463978687 1;
BA_ "GenMsgSendType" BO_ 2463978687 0;
BA_ "VFrameFormat" BO_ 2463978687 15;
BA_ "GenMsgCycleTime" BO_ 916 160;
BA_ "GenMsgCycleTimeFast" BO_ 916 10;
BA_ "GenMsgDelayTime" BO_ 916 10;
BA_ "GenMsgILSupport" BO_ 916 1;
BA_ "GenMsgNrOfRepetition" BO_ 916 3;
BA_ "GenMsgPDUConstants" BO_ 916 "0x47,0x94,0x92,0x6a,0x67,0xb5,0x0d,0x38,0xe3,0x8a,0x5d,0xb4,0x54,0xab,0xae,0x27";
BA_ "GenMsgSendType" BO_ 916 0;
BA_ "VFrameFormat" BO_ 916 14;
BA_ "GenMsgCycleTime" BO_ 1361 200;
BA_ "GenMsgDelayTime" BO_ 1361 50;
BA_ "GenMsgILSupport" BO_ 1361 1;
BA_ "GenMsgSendType" BO_ 1361 0;
BA_ "VFrameFormat" BO_ 1361 14;
BA_ "GenMsgCycleTime" BO_ 1702 1000;
BA_ "GenMsgDelayTime" BO_ 1702 50;
BA_ "GenMsgILSupport" BO_ 1702 1;
BA_ "GenMsgSendType" BO_ 1702 0;
BA_ "VFrameFormat" BO_ 1702 14;
BA_ "GenMsgCycleTime" BO_ 1602 2000;
BA_ "GenMsgILSupport" BO_ 1602 1;
BA_ "GenMsgSendType" BO_ 1602 0;
BA_ "VFrameFormat" BO_ 1602 14;
BA_ "MsgType" BO_ 2617228832 6;
BA_ "VFrameFormat" BO_ 2617228832 15;
BA_ "MsgType" BO_ 2617228834 6;
BA_ "VFrameFormat" BO_ 2617228834 15;
BA_ "MsgType" BO_ 2617228836 6;
BA_ "VFrameFormat" BO_ 2617228836 15;
BA_ "MsgType" BO_ 2617228833 6;
BA_ "VFrameFormat" BO_ 2617228833 15;
BA_ "MsgType" BO_ 2617228835 6;
BA_ "VFrameFormat" BO_ 2617228835 15;
BA_ "MsgType" BO_ 2617228837 6;
BA_ "VFrameFormat" BO_ 2617228837 15;
BA_ "MsgType" BO_ 2617226768 8;
BA_ "VFrameFormat" BO_ 2617226768 15;
BA_ "MsgType" BO_ 2617226769 9;
BA_ "VFrameFormat" BO_ 2617226769 15;
BA_ "MsgType" BO_ 2566734336 8;
BA_ "VFrameFormat" BO_ 2566734336 15;
BA_ "MsgType" BO_ 2566734337 9;
BA_ "VFrameFormat" BO_ 2566734337 15;
BA_ "GenMsgCycleTime" BO_ 388 1000;
BA_ "GenMsgCycleTimeFast" BO_ 388 20;
BA_ "GenMsgILSupport" BO_ 388 1;
BA_ "GenMsgNrOfRepetition" BO_ 388 5;
BA_ "GenMsgPDUConstants" BO_ 388 "0xe3,0xe8,0xc4,0x7f,0xf1,0x95,0xd8,0xb0,0xc7,0xa3,0xf4,0x6c,0xe7,0xc3,0x5a,0xf7";
BA_ "GenMsgSendType" BO_ 388 0;
BA_ "VFrameFormat" BO_ 388 14;
BA_ "GenMsgCycleTime" BO_ 1411 200;
BA_ "GenMsgCycleTimeFast" BO_ 1411 50;
BA_ "GenMsgDelayTime" BO_ 1411 20;
BA_ "GenMsgILSupport" BO_ 1411 1;
BA_ "GenMsgNrOfRepetition" BO_ 1411 3;
BA_ "GenMsgSendType" BO_ 1411 0;
BA_ "VFrameFormat" BO_ 1411 14;
BA_ "GenSigSendType" SG_ 313 HMS_aktives_System 0;
BA_ "GenSigSwitchedByIgnition" SG_ 313 HMS_aktives_System 0;
BA_ "GenSigSendType" SG_ 313 HMS_Anforderung_GE 0;
BA_ "GenSigSwitchedByIgnition" SG_ 313 HMS_Anforderung_GE 0;
BA_ "GenSigSendType" SG_ 313 HMS_Fehlerstatus 0;
BA_ "GenSigSwitchedByIgnition" SG_ 313 HMS_Fehlerstatus 0;
BA_ "GenSigSendType" SG_ 313 HMS_Haltemoment 0;
BA_ "GenSigStartValue" SG_ 313 HMS_Haltemoment 1022;
BA_ "GenSigSwitchedByIgnition" SG_ 313 HMS_Haltemoment 0;
BA_ "Fehlerwert" SG_ 313 HMS_Haltemoment 1023;
BA_ "GenSigSendType" SG_ 313 HMS_halten_nicht_verfuegbar 0;
BA_ "GenSigSwitchedByIgnition" SG_ 313 HMS_halten_nicht_verfuegbar 0;
BA_ "GenSigSendType" SG_ 313 HMS_halten_nicht_verfuegbar_02 0;
BA_ "GenSigSwitchedByIgnition" SG_ 313 HMS_halten_nicht_verfuegbar_02 0;
BA_ "GenSigSendType" SG_ 313 HMS_Index_Haltemoment 0;
BA_ "GenSigSwitchedByIgnition" SG_ 313 HMS_Index_Haltemoment 0;
BA_ "GenSigSendType" SG_ 313 HMS_P_beibehalten_GE 0;
BA_ "GenSigStartValue" SG_ 313 HMS_P_beibehalten_GE 2;
BA_ "GenSigSwitchedByIgnition" SG_ 313 HMS_P_beibehalten_GE 0;
BA_ "Fehlerwert" SG_ 313 HMS_P_beibehalten_GE 3;
BA_ "GenSigSendType" SG_ 313 HMS_parken_nicht_verfuegbar 0;
BA_ "GenSigSwitchedByIgnition" SG_ 313 HMS_parken_nicht_verfuegbar 0;
BA_ "GenSigSendType" SG_ 313 HMS_Stillstand 0;
BA_ "GenSigStartValue" SG_ 313 HMS_Stillstand 6;
BA_ "GenSigSwitchedByIgnition" SG_ 313 HMS_Stillstand 0;
BA_ "Fehlerwert" SG_ 313 HMS_Stillstand 7;
BA_ "GenSigSendType" SG_ 313 HMS_Systemstatus 0;
BA_ "GenSigStartValue" SG_ 313 HMS_Systemstatus 14;
BA_ "GenSigSwitchedByIgnition" SG_ 313 HMS_Systemstatus 0;
BA_ "Fehlerwert" SG_ 313 HMS_Systemstatus 15;
BA_ "GenSigSendType" SG_ 313 SOK_VMM_02_Signatur 0;
BA_ "GenSigFuncType" SG_ 313 SOK_VMM_02_Signatur 15;
BA_ "GenSigSendType" SG_ 313 VMM_02_BZ 0;
BA_ "GenSigFuncType" SG_ 313 VMM_02_BZ 1;
BA_ "GenSigSwitchedByIgnition" SG_ 313 VMM_02_BZ 0;
BA_ "GenSigSendType" SG_ 313 VMM_02_CRC 0;
BA_ "GenSigFuncType" SG_ 313 VMM_02_CRC 2;
BA_ "GenSigSwitchedByIgnition" SG_ 313 VMM_02_CRC 0;
BA_ "GenSigSendType" SG_ 313 VMM_Bremslicht_defekt 0;
BA_ "GenSigSwitchedByIgnition" SG_ 313 VMM_Bremslicht_defekt 0;
BA_ "GenSigSendType" SG_ 313 VMM_Bremslicht_unplausibel 0;
BA_ "GenSigSwitchedByIgnition" SG_ 313 VMM_Bremslicht_unplausibel 0;
BA_ "GenSigSendType" SG_ 313 VMM_Fahrer_Bremskraft_bestimmend 0;
BA_ "GenSigSwitchedByIgnition" SG_ 313 VMM_Fahrer_Bremskraft_bestimmend 0;
BA_ "GenSigSendType" SG_ 313 VMM_Inkonsistenz_ACC 0;
BA_ "GenSigSwitchedByIgnition" SG_ 313 VMM_Inkonsistenz_ACC 0;
BA_ "GenSigSendType" SG_ 313 VMM_Inkonsistenz_AEB 0;
BA_ "GenSigSwitchedByIgnition" SG_ 313 VMM_Inkonsistenz_AEB 0;
BA_ "GenSigSendType" SG_ 313 VMM_Inkonsistenz_ARA 0;
BA_ "GenSigSwitchedByIgnition" SG_ 313 VMM_Inkonsistenz_ARA 0;
BA_ "GenSigSendType" SG_ 313 VMM_Inkonsistenz_AWV_PCF 0;
BA_ "GenSigSwitchedByIgnition" SG_ 313 VMM_Inkonsistenz_AWV_PCF 0;
BA_ "GenSigSendType" SG_ 313 VMM_Inkonsistenz_EA 0;
BA_ "GenSigSwitchedByIgnition" SG_ 313 VMM_Inkonsistenz_EA 0;
BA_ "GenSigSendType" SG_ 313 VMM_Inkonsistenz_EBKV 0;
BA_ "GenSigSwitchedByIgnition" SG_ 313 VMM_Inkonsistenz_EBKV 0;
BA_ "GenSigSendType" SG_ 313 VMM_Inkonsistenz_FAS_VK 0;
BA_ "GenSigSwitchedByIgnition" SG_ 313 VMM_Inkonsistenz_FAS_VK 0;
BA_ "GenSigSendType" SG_ 313 VMM_Inkonsistenz_GE 0;
BA_ "GenSigSwitchedByIgnition" SG_ 313 VMM_Inkonsistenz_GE 0;
BA_ "GenSigSendType" SG_ 313 VMM_Inkonsistenz_HVLM 0;
BA_ "GenSigSwitchedByIgnition" SG_ 313 VMM_Inkonsistenz_HVLM 0;
BA_ "GenSigSendType" SG_ 313 VMM_Inkonsistenz_KAM 0;
BA_ "GenSigSwitchedByIgnition" SG_ 313 VMM_Inkonsistenz_KAM 0;
BA_ "GenSigSendType" SG_ 313 VMM_Inkonsistenz_KAS 0;
BA_ "GenSigSwitchedByIgnition" SG_ 313 VMM_Inkonsistenz_KAS 0;
BA_ "GenSigSendType" SG_ 313 VMM_Inkonsistenz_MO 0;
BA_ "GenSigSwitchedByIgnition" SG_ 313 VMM_Inkonsistenz_MO 0;
BA_ "GenSigSendType" SG_ 313 VMM_Inkonsistenz_NV 0;
BA_ "GenSigSwitchedByIgnition" SG_ 313 VMM_Inkonsistenz_NV 0;
BA_ "GenSigSendType" SG_ 313 VMM_Inkonsistenz_ParkAssist 0;
BA_ "GenSigSwitchedByIgnition" SG_ 313 VMM_Inkonsistenz_ParkAssist 0;
BA_ "GenSigSendType" SG_ 313 VMM_Inkonsistenz_RCTA 0;
BA_ "GenSigSwitchedByIgnition" SG_ 313 VMM_Inkonsistenz_RCTA 0;
BA_ "GenSigSendType" SG_ 313 VMM_Inkonsistenz_RHP 0;
BA_ "GenSigSwitchedByIgnition" SG_ 313 VMM_Inkonsistenz_RHP 0;
BA_ "GenSigSendType" SG_ 313 VMM_Inkonsistenz_TSK 0;
BA_ "GenSigSwitchedByIgnition" SG_ 313 VMM_Inkonsistenz_TSK 0;
BA_ "GenSigSendType" SG_ 313 VMM_Inkonsistenz_VLK 0;
BA_ "GenSigSwitchedByIgnition" SG_ 313 VMM_Inkonsistenz_VLK 0;
BA_ "GenSigSendType" SG_ 313 VMM_MKB_codiert 0;
BA_ "GenSigSwitchedByIgnition" SG_ 313 VMM_MKB_codiert 0;
BA_ "GenSigSendType" SG_ 313 VMM_Notstopp_Status 0;
BA_ "GenSigSwitchedByIgnition" SG_ 313 VMM_Notstopp_Status 0;
BA_ "Fehlerwert" SG_ 313 VMM_Notstopp_Status 7;
BA_ "GenSigSendType" SG_ 313 VZM_aktiver_Basisservice 0;
BA_ "GenSigSwitchedByIgnition" SG_ 313 VZM_aktiver_Basisservice 0;
BA_ "GenSigSendType" SG_ 313 VZM_aktives_System 0;
BA_ "GenSigSwitchedByIgnition" SG_ 313 VZM_aktives_System 0;
BA_ "GenSigSendType" SG_ 313 VZM_Anhalteweg_nicht_verfuegbar 0;
BA_ "GenSigSwitchedByIgnition" SG_ 313 VZM_Anhalteweg_nicht_verfuegbar 0;
BA_ "GenSigSendType" SG_ 313 VZM_Bkd_nicht_verfuegbar 0;
BA_ "GenSigSwitchedByIgnition" SG_ 313 VZM_Bkd_nicht_verfuegbar 0;
BA_ "GenSigSendType" SG_ 313 VZM_Fahrer_bremst 0;
BA_ "GenSigSwitchedByIgnition" SG_ 313 VZM_Fahrer_bremst 0;
BA_ "GenSigSendType" SG_ 313 VZM_Fahrer_bremst_deutlich 0;
BA_ "GenSigSwitchedByIgnition" SG_ 313 VZM_Fahrer_bremst_deutlich 0;
BA_ "GenSigSendType" SG_ 313 VZM_QBit_Fahrer_bremst 0;
BA_ "GenSigStartValue" SG_ 313 VZM_QBit_Fahrer_bremst 1;
BA_ "GenSigSwitchedByIgnition" SG_ 313 VZM_QBit_Fahrer_bremst 0;
BA_ "GenSigSendType" SG_ 313 VZM_SRBM_Ist 0;
BA_ "GenSigStartValue" SG_ 313 VZM_SRBM_Ist 4094;
BA_ "GenSigSwitchedByIgnition" SG_ 313 VZM_SRBM_Ist 0;
BA_ "Fehlerwert" SG_ 313 VZM_SRBM_Ist 4095;
BA_ "GenSigSendType" SG_ 313 VZM_SRBM_max_Gradient 0;
BA_ "GenSigStartValue" SG_ 313 VZM_SRBM_max_Gradient 126;
BA_ "GenSigSwitchedByIgnition" SG_ 313 VZM_SRBM_max_Gradient 0;
BA_ "Fehlerwert" SG_ 313 VZM_SRBM_max_Gradient 127;
BA_ "GenSigSendType" SG_ 313 VZM_SRBM_Soll 0;
BA_ "GenSigStartValue" SG_ 313 VZM_SRBM_Soll 4094;
BA_ "GenSigSwitchedByIgnition" SG_ 313 VZM_SRBM_Soll 0;
BA_ "Fehlerwert" SG_ 313 VZM_SRBM_Soll 4095;
BA_ "GenSigSendType" SG_ 313 VZM_Status_Wegregelung 0;
BA_ "GenSigSwitchedByIgnition" SG_ 313 VZM_Status_Wegregelung 0;
BA_ "GenSigSendType" SG_ 313 VZM_Systemstatus 0;
BA_ "GenSigSwitchedByIgnition" SG_ 313 VZM_Systemstatus 0;
BA_ "Fehlerwert" SG_ 313 VZM_Systemstatus 4;
BA_ "GenSigSendType" SG_ 313 VZM_TSK_SRBM_Anf 0;
BA_ "GenSigSwitchedByIgnition" SG_ 313 VZM_TSK_SRBM_Anf 0;
BA_ "GenSigSendType" SG_ 313 VZM_TSK_SRBM_nicht_verfuegbar 0;
BA_ "GenSigSwitchedByIgnition" SG_ 313 VZM_TSK_SRBM_nicht_verfuegbar 0;
BA_ "GenSigSendType" SG_ 313 VZM_Unterdrueckung_Antriebsmom 0;
BA_ "GenSigSwitchedByIgnition" SG_ 313 VZM_Unterdrueckung_Antriebsmom 0;
BA_ "GenSigSendType" SG_ 313 VZM_Verz_ASIL_Verfuegbarkeit 0;
BA_ "GenSigSwitchedByIgnition" SG_ 313 VZM_Verz_ASIL_Verfuegbarkeit 0;
BA_ "GenSigSendType" SG_ 313 VZM_Verz_Begrenzung 0;
BA_ "GenSigSwitchedByIgnition" SG_ 313 VZM_Verz_Begrenzung 0;
BA_ "GenSigSendType" SG_ 313 VZM_Verz_Reg_aktiv 0;
BA_ "GenSigSwitchedByIgnition" SG_ 313 VZM_Verz_Reg_aktiv 0;
BA_ "GenSigSendType" SG_ 313 VZM_Verz_Reg_nicht_verfuegbar 0;
BA_ "GenSigSwitchedByIgnition" SG_ 313 VZM_Verz_Reg_nicht_verfuegbar 0;
BA_ "GenSigSendType" SG_ 313 VZM_Warnruck_nicht_verfuegbar 0;
BA_ "GenSigSwitchedByIgnition" SG_ 313 VZM_Warnruck_nicht_verfuegbar 0;
BA_ "GenSigSendType" SG_ 313 VZM_Warnruckeln_nicht_verfuegbar 0;
BA_ "GenSigSwitchedByIgnition" SG_ 313 VZM_Warnruckeln_nicht_verfuegbar 0;
BA_ "GenSigSendType" SG_ 2331595858 vREM_Abstand_P0 0;
BA_ "GenSigStartValue" SG_ 2331595858 vREM_Abstand_P0 511;
BA_ "GenSigSwitchedByIgnition" SG_ 2331595858 vREM_Abstand_P0 0;
BA_ "GenSigSendType" SG_ 2331595858 vREM_Abstand_P1 0;
BA_ "GenSigStartValue" SG_ 2331595858 vREM_Abstand_P1 511;
BA_ "GenSigSwitchedByIgnition" SG_ 2331595858 vREM_Abstand_P1 0;
BA_ "GenSigSendType" SG_ 2331595858 vREM_Abstand_P10 0;
BA_ "GenSigStartValue" SG_ 2331595858 vREM_Abstand_P10 511;
BA_ "GenSigSwitchedByIgnition" SG_ 2331595858 vREM_Abstand_P10 0;
BA_ "GenSigSendType" SG_ 2331595858 vREM_Abstand_P11 0;
BA_ "GenSigStartValue" SG_ 2331595858 vREM_Abstand_P11 511;
BA_ "GenSigSwitchedByIgnition" SG_ 2331595858 vREM_Abstand_P11 0;
BA_ "GenSigSendType" SG_ 2331595858 vREM_Abstand_P12 0;
BA_ "GenSigStartValue" SG_ 2331595858 vREM_Abstand_P12 511;
BA_ "GenSigSwitchedByIgnition" SG_ 2331595858 vREM_Abstand_P12 0;
BA_ "GenSigSendType" SG_ 2331595858 vREM_Abstand_P13 0;
BA_ "GenSigStartValue" SG_ 2331595858 vREM_Abstand_P13 511;
BA_ "GenSigSwitchedByIgnition" SG_ 2331595858 vREM_Abstand_P13 0;
BA_ "GenSigSendType" SG_ 2331595858 vREM_Abstand_P14 0;
BA_ "GenSigStartValue" SG_ 2331595858 vREM_Abstand_P14 511;
BA_ "GenSigSwitchedByIgnition" SG_ 2331595858 vREM_Abstand_P14 0;
BA_ "GenSigSendType" SG_ 2331595858 vREM_Abstand_P15 0;
BA_ "GenSigStartValue" SG_ 2331595858 vREM_Abstand_P15 511;
BA_ "GenSigSwitchedByIgnition" SG_ 2331595858 vREM_Abstand_P15 0;
BA_ "GenSigSendType" SG_ 2331595858 vREM_Abstand_P16 0;
BA_ "GenSigStartValue" SG_ 2331595858 vREM_Abstand_P16 511;
BA_ "GenSigSwitchedByIgnition" SG_ 2331595858 vREM_Abstand_P16 0;
BA_ "GenSigSendType" SG_ 2331595858 vREM_Abstand_P17 0;
BA_ "GenSigStartValue" SG_ 2331595858 vREM_Abstand_P17 511;
BA_ "GenSigSwitchedByIgnition" SG_ 2331595858 vREM_Abstand_P17 0;
BA_ "GenSigSendType" SG_ 2331595858 vREM_Abstand_P18 0;
BA_ "GenSigStartValue" SG_ 2331595858 vREM_Abstand_P18 511;
BA_ "GenSigSwitchedByIgnition" SG_ 2331595858 vREM_Abstand_P18 0;
BA_ "GenSigSendType" SG_ 2331595858 vREM_Abstand_P19 0;
BA_ "GenSigStartValue" SG_ 2331595858 vREM_Abstand_P19 511;
BA_ "GenSigSwitchedByIgnition" SG_ 2331595858 vREM_Abstand_P19 0;
BA_ "GenSigSendType" SG_ 2331595858 vREM_Abstand_P2 0;
BA_ "GenSigStartValue" SG_ 2331595858 vREM_Abstand_P2 511;
BA_ "GenSigSwitchedByIgnition" SG_ 2331595858 vREM_Abstand_P2 0;
BA_ "GenSigSendType" SG_ 2331595858 vREM_Abstand_P20 0;
BA_ "GenSigStartValue" SG_ 2331595858 vREM_Abstand_P20 511;
BA_ "GenSigSwitchedByIgnition" SG_ 2331595858 vREM_Abstand_P20 0;
BA_ "GenSigSendType" SG_ 2331595858 vREM_Abstand_P21 0;
BA_ "GenSigStartValue" SG_ 2331595858 vREM_Abstand_P21 511;
BA_ "GenSigSwitchedByIgnition" SG_ 2331595858 vREM_Abstand_P21 0;
BA_ "GenSigSendType" SG_ 2331595858 vREM_Abstand_P22 0;
BA_ "GenSigStartValue" SG_ 2331595858 vREM_Abstand_P22 511;
BA_ "GenSigSwitchedByIgnition" SG_ 2331595858 vREM_Abstand_P22 0;
BA_ "GenSigSendType" SG_ 2331595858 vREM_Abstand_P23 0;
BA_ "GenSigStartValue" SG_ 2331595858 vREM_Abstand_P23 511;
BA_ "GenSigSwitchedByIgnition" SG_ 2331595858 vREM_Abstand_P23 0;
BA_ "GenSigSendType" SG_ 2331595858 vREM_Abstand_P24 0;
BA_ "GenSigStartValue" SG_ 2331595858 vREM_Abstand_P24 511;
BA_ "GenSigSwitchedByIgnition" SG_ 2331595858 vREM_Abstand_P24 0;
BA_ "GenSigSendType" SG_ 2331595858 vREM_Abstand_P25 0;
BA_ "GenSigStartValue" SG_ 2331595858 vREM_Abstand_P25 511;
BA_ "GenSigSwitchedByIgnition" SG_ 2331595858 vREM_Abstand_P25 0;
BA_ "GenSigSendType" SG_ 2331595858 vREM_Abstand_P26 0;
BA_ "GenSigStartValue" SG_ 2331595858 vREM_Abstand_P26 511;
BA_ "GenSigSwitchedByIgnition" SG_ 2331595858 vREM_Abstand_P26 0;
BA_ "GenSigSendType" SG_ 2331595858 vREM_Abstand_P27 0;
BA_ "GenSigStartValue" SG_ 2331595858 vREM_Abstand_P27 511;
BA_ "GenSigSwitchedByIgnition" SG_ 2331595858 vREM_Abstand_P27 0;
BA_ "GenSigSendType" SG_ 2331595858 vREM_Abstand_P28 0;
BA_ "GenSigStartValue" SG_ 2331595858 vREM_Abstand_P28 511;
BA_ "GenSigSwitchedByIgnition" SG_ 2331595858 vREM_Abstand_P28 0;
BA_ "GenSigSendType" SG_ 2331595858 vREM_Abstand_P29 0;
BA_ "GenSigStartValue" SG_ 2331595858 vREM_Abstand_P29 511;
BA_ "GenSigSwitchedByIgnition" SG_ 2331595858 vREM_Abstand_P29 0;
BA_ "GenSigSendType" SG_ 2331595858 vREM_Abstand_P3 0;
BA_ "GenSigStartValue" SG_ 2331595858 vREM_Abstand_P3 511;
BA_ "GenSigSwitchedByIgnition" SG_ 2331595858 vREM_Abstand_P3 0;
BA_ "GenSigSendType" SG_ 2331595858 vREM_Abstand_P4 0;
BA_ "GenSigStartValue" SG_ 2331595858 vREM_Abstand_P4 511;
BA_ "GenSigSwitchedByIgnition" SG_ 2331595858 vREM_Abstand_P4 0;
BA_ "GenSigSendType" SG_ 2331595858 vREM_Abstand_P5 0;
BA_ "GenSigStartValue" SG_ 2331595858 vREM_Abstand_P5 511;
BA_ "GenSigSwitchedByIgnition" SG_ 2331595858 vREM_Abstand_P5 0;
BA_ "GenSigSendType" SG_ 2331595858 vREM_Abstand_P6 0;
BA_ "GenSigStartValue" SG_ 2331595858 vREM_Abstand_P6 511;
BA_ "GenSigSwitchedByIgnition" SG_ 2331595858 vREM_Abstand_P6 0;
BA_ "GenSigSendType" SG_ 2331595858 vREM_Abstand_P7 0;
BA_ "GenSigStartValue" SG_ 2331595858 vREM_Abstand_P7 511;
BA_ "GenSigSwitchedByIgnition" SG_ 2331595858 vREM_Abstand_P7 0;
BA_ "GenSigSendType" SG_ 2331595858 vREM_Abstand_P8 0;
BA_ "GenSigStartValue" SG_ 2331595858 vREM_Abstand_P8 511;
BA_ "GenSigSwitchedByIgnition" SG_ 2331595858 vREM_Abstand_P8 0;
BA_ "GenSigSendType" SG_ 2331595858 vREM_Abstand_P9 0;
BA_ "GenSigStartValue" SG_ 2331595858 vREM_Abstand_P9 511;
BA_ "GenSigSwitchedByIgnition" SG_ 2331595858 vREM_Abstand_P9 0;
BA_ "GenSigSendType" SG_ 2331595858 vREM_Akt_Zaehler 0;
BA_ "GenSigSwitchedByIgnition" SG_ 2331595858 vREM_Akt_Zaehler 0;
BA_ "GenSigSendType" SG_ 2331595858 vREM_Status 0;
BA_ "GenSigSwitchedByIgnition" SG_ 2331595858 vREM_Status 0;
BA_ "GenSigSendType" SG_ 2331595859 vREM_Geschw_P0 0;
BA_ "GenSigStartValue" SG_ 2331595859 vREM_Geschw_P0 254;
BA_ "GenSigSwitchedByIgnition" SG_ 2331595859 vREM_Geschw_P0 0;
BA_ "GenSigSendType" SG_ 2331595859 vREM_Geschw_P1 0;
BA_ "GenSigStartValue" SG_ 2331595859 vREM_Geschw_P1 254;
BA_ "GenSigSwitchedByIgnition" SG_ 2331595859 vREM_Geschw_P1 0;
BA_ "GenSigSendType" SG_ 2331595859 vREM_Geschw_P10 0;
BA_ "GenSigStartValue" SG_ 2331595859 vREM_Geschw_P10 254;
BA_ "GenSigSwitchedByIgnition" SG_ 2331595859 vREM_Geschw_P10 0;
BA_ "GenSigSendType" SG_ 2331595859 vREM_Geschw_P11 0;
BA_ "GenSigStartValue" SG_ 2331595859 vREM_Geschw_P11 254;
BA_ "GenSigSwitchedByIgnition" SG_ 2331595859 vREM_Geschw_P11 0;
BA_ "GenSigSendType" SG_ 2331595859 vREM_Geschw_P12 0;
BA_ "GenSigStartValue" SG_ 2331595859 vREM_Geschw_P12 254;
BA_ "GenSigSwitchedByIgnition" SG_ 2331595859 vREM_Geschw_P12 0;
BA_ "GenSigSendType" SG_ 2331595859 vREM_Geschw_P13 0;
BA_ "GenSigStartValue" SG_ 2331595859 vREM_Geschw_P13 254;
BA_ "GenSigSwitchedByIgnition" SG_ 2331595859 vREM_Geschw_P13 0;
BA_ "GenSigSendType" SG_ 2331595859 vREM_Geschw_P14 0;
BA_ "GenSigStartValue" SG_ 2331595859 vREM_Geschw_P14 254;
BA_ "GenSigSwitchedByIgnition" SG_ 2331595859 vREM_Geschw_P14 0;
BA_ "GenSigSendType" SG_ 2331595859 vREM_Geschw_P15 0;
BA_ "GenSigStartValue" SG_ 2331595859 vREM_Geschw_P15 254;
BA_ "GenSigSwitchedByIgnition" SG_ 2331595859 vREM_Geschw_P15 0;
BA_ "GenSigSendType" SG_ 2331595859 vREM_Geschw_P16 0;
BA_ "GenSigStartValue" SG_ 2331595859 vREM_Geschw_P16 254;
BA_ "GenSigSwitchedByIgnition" SG_ 2331595859 vREM_Geschw_P16 0;
BA_ "GenSigSendType" SG_ 2331595859 vREM_Geschw_P17 0;
BA_ "GenSigStartValue" SG_ 2331595859 vREM_Geschw_P17 254;
BA_ "GenSigSwitchedByIgnition" SG_ 2331595859 vREM_Geschw_P17 0;
BA_ "GenSigSendType" SG_ 2331595859 vREM_Geschw_P18 0;
BA_ "GenSigStartValue" SG_ 2331595859 vREM_Geschw_P18 254;
BA_ "GenSigSwitchedByIgnition" SG_ 2331595859 vREM_Geschw_P18 0;
BA_ "GenSigSendType" SG_ 2331595859 vREM_Geschw_P19 0;
BA_ "GenSigStartValue" SG_ 2331595859 vREM_Geschw_P19 254;
BA_ "GenSigSwitchedByIgnition" SG_ 2331595859 vREM_Geschw_P19 0;
BA_ "GenSigSendType" SG_ 2331595859 vREM_Geschw_P2 0;
BA_ "GenSigStartValue" SG_ 2331595859 vREM_Geschw_P2 254;
BA_ "GenSigSwitchedByIgnition" SG_ 2331595859 vREM_Geschw_P2 0;
BA_ "GenSigSendType" SG_ 2331595859 vREM_Geschw_P20 0;
BA_ "GenSigStartValue" SG_ 2331595859 vREM_Geschw_P20 254;
BA_ "GenSigSwitchedByIgnition" SG_ 2331595859 vREM_Geschw_P20 0;
BA_ "GenSigSendType" SG_ 2331595859 vREM_Geschw_P21 0;
BA_ "GenSigStartValue" SG_ 2331595859 vREM_Geschw_P21 254;
BA_ "GenSigSwitchedByIgnition" SG_ 2331595859 vREM_Geschw_P21 0;
BA_ "GenSigSendType" SG_ 2331595859 vREM_Geschw_P22 0;
BA_ "GenSigStartValue" SG_ 2331595859 vREM_Geschw_P22 254;
BA_ "GenSigSwitchedByIgnition" SG_ 2331595859 vREM_Geschw_P22 0;
BA_ "GenSigSendType" SG_ 2331595859 vREM_Geschw_P23 0;
BA_ "GenSigStartValue" SG_ 2331595859 vREM_Geschw_P23 254;
BA_ "GenSigSwitchedByIgnition" SG_ 2331595859 vREM_Geschw_P23 0;
BA_ "GenSigSendType" SG_ 2331595859 vREM_Geschw_P24 0;
BA_ "GenSigStartValue" SG_ 2331595859 vREM_Geschw_P24 254;
BA_ "GenSigSwitchedByIgnition" SG_ 2331595859 vREM_Geschw_P24 0;
BA_ "GenSigSendType" SG_ 2331595859 vREM_Geschw_P25 0;
BA_ "GenSigStartValue" SG_ 2331595859 vREM_Geschw_P25 254;
BA_ "GenSigSwitchedByIgnition" SG_ 2331595859 vREM_Geschw_P25 0;
BA_ "GenSigSendType" SG_ 2331595859 vREM_Geschw_P26 0;
BA_ "GenSigStartValue" SG_ 2331595859 vREM_Geschw_P26 254;
BA_ "GenSigSwitchedByIgnition" SG_ 2331595859 vREM_Geschw_P26 0;
BA_ "GenSigSendType" SG_ 2331595859 vREM_Geschw_P27 0;
BA_ "GenSigStartValue" SG_ 2331595859 vREM_Geschw_P27 254;
BA_ "GenSigSwitchedByIgnition" SG_ 2331595859 vREM_Geschw_P27 0;
BA_ "GenSigSendType" SG_ 2331595859 vREM_Geschw_P28 0;
BA_ "GenSigStartValue" SG_ 2331595859 vREM_Geschw_P28 254;
BA_ "GenSigSwitchedByIgnition" SG_ 2331595859 vREM_Geschw_P28 0;
BA_ "GenSigSendType" SG_ 2331595859 vREM_Geschw_P29 0;
BA_ "GenSigStartValue" SG_ 2331595859 vREM_Geschw_P29 254;
BA_ "GenSigSwitchedByIgnition" SG_ 2331595859 vREM_Geschw_P29 0;
BA_ "GenSigSendType" SG_ 2331595859 vREM_Geschw_P3 0;
BA_ "GenSigStartValue" SG_ 2331595859 vREM_Geschw_P3 254;
BA_ "GenSigSwitchedByIgnition" SG_ 2331595859 vREM_Geschw_P3 0;
BA_ "GenSigSendType" SG_ 2331595859 vREM_Geschw_P4 0;
BA_ "GenSigStartValue" SG_ 2331595859 vREM_Geschw_P4 254;
BA_ "GenSigSwitchedByIgnition" SG_ 2331595859 vREM_Geschw_P4 0;
BA_ "GenSigSendType" SG_ 2331595859 vREM_Geschw_P5 0;
BA_ "GenSigStartValue" SG_ 2331595859 vREM_Geschw_P5 254;
BA_ "GenSigSwitchedByIgnition" SG_ 2331595859 vREM_Geschw_P5 0;
BA_ "GenSigSendType" SG_ 2331595859 vREM_Geschw_P6 0;
BA_ "GenSigStartValue" SG_ 2331595859 vREM_Geschw_P6 254;
BA_ "GenSigSwitchedByIgnition" SG_ 2331595859 vREM_Geschw_P6 0;
BA_ "GenSigSendType" SG_ 2331595859 vREM_Geschw_P7 0;
BA_ "GenSigStartValue" SG_ 2331595859 vREM_Geschw_P7 254;
BA_ "GenSigSwitchedByIgnition" SG_ 2331595859 vREM_Geschw_P7 0;
BA_ "GenSigSendType" SG_ 2331595859 vREM_Geschw_P8 0;
BA_ "GenSigStartValue" SG_ 2331595859 vREM_Geschw_P8 254;
BA_ "GenSigSwitchedByIgnition" SG_ 2331595859 vREM_Geschw_P8 0;
BA_ "GenSigSendType" SG_ 2331595859 vREM_Geschw_P9 0;
BA_ "GenSigStartValue" SG_ 2331595859 vREM_Geschw_P9 254;
BA_ "GenSigSwitchedByIgnition" SG_ 2331595859 vREM_Geschw_P9 0;
BA_ "GenSigSendType" SG_ 2463978663 VZE_Akustik_Limitwechsel 0;
BA_ "GenSigSendType" SG_ 2463978663 VZE_Akustik_Limitwechsel_Status 0;
BA_ "GenSigSendType" SG_ 2463978663 VZE_Anhaenger_Vmax 3;
BA_ "GenSigStartValue" SG_ 2463978663 VZE_Anhaenger_Vmax 14;
BA_ "Fehlerwert" SG_ 2463978663 VZE_Anhaenger_Vmax 15;
BA_ "GenSigSendType" SG_ 2463978663 VZE_Anzeige_VZ_1 0;
BA_ "GenSigSendType" SG_ 2463978663 VZE_Anzeige_VZ_2 0;
BA_ "GenSigSendType" SG_ 2463978663 VZE_Anzeige_VZ_3 0;
BA_ "GenSigSendType" SG_ 2463978663 VZE_Anzeige_ZS_1 0;
BA_ "GenSigSendType" SG_ 2463978663 VZE_Anzeige_ZS_2 0;
BA_ "GenSigSendType" SG_ 2463978663 VZE_Anzeige_ZS_3 0;
BA_ "GenSigSendType" SG_ 2463978663 VZE_Anzeigemodus 3;
BA_ "GenSigSendType" SG_ 2463978663 VZE_Anzeigeunterdrueck_Zeichen_1 3;
BA_ "GenSigSendType" SG_ 2463978663 VZE_Anzeigeunterdrueck_Zeichen_2 3;
BA_ "GenSigSendType" SG_ 2463978663 VZE_Anzeigeunterdrueck_Zeichen_3 3;
BA_ "GenSigSendType" SG_ 2463978663 VZE_Anzeigeunterdrueck_Zeichen_4 3;
BA_ "GenSigSendType" SG_ 2463978663 VZE_Anzeigeunterdrueck_Zeichen_5 3;
BA_ "GenSigSendType" SG_ 2463978663 VZE_Baustelle 3;
BA_ "GenSigSendType" SG_ 2463978663 VZE_Erweiterte_Information 0;
BA_ "GenSigSendType" SG_ 2463978663 VZE_FoD_Status 0;
BA_ "GenSigSendType" SG_ 2463978663 VZE_Gong 3;
BA_ "GenSigSendType" SG_ 2463978663 VZE_Hinweistext 3;
BA_ "GenSigSendType" SG_ 2463978663 VZE_Hinweistext_03 0;
BA_ "GenSigSendType" SG_ 2463978663 VZE_Land 0;
BA_ "GenSigSendType" SG_ 2463978663 VZE_Modus_OptischeWarnung 0;
BA_ "GenSigSendType" SG_ 2463978663 VZE_SLWF_Status 0;
BA_ "GenSigSendType" SG_ 2463978663 VZE_Tempowarnung_Einheit 0;
BA_ "GenSigSendType" SG_ 2463978663 VZE_Tempowarnung_Offset 0;
BA_ "GenSigSendType" SG_ 2463978663 VZE_Tempowarnung_Status 0;
BA_ "GenSigSendType" SG_ 2463978663 VZE_Umweltinfo_Anhaengerbetrieb 0;
BA_ "GenSigSendType" SG_ 2463978663 VZE_Umweltinfo_Naesse 0;
BA_ "GenSigSendType" SG_ 2463978663 VZE_Umweltinfo_Nebel 0;
BA_ "GenSigSendType" SG_ 2463978663 VZE_Verkehrszeichen_1 3;
BA_ "GenSigSendType" SG_ 2463978663 VZE_Verkehrszeichen_2 3;
BA_ "GenSigSendType" SG_ 2463978663 VZE_Verkehrszeichen_3 3;
BA_ "GenSigSendType" SG_ 2463978663 VZE_Verkehrszeichen_4 3;
BA_ "GenSigSendType" SG_ 2463978663 VZE_Verkehrszeichen_5 3;
BA_ "GenSigSendType" SG_ 2463978663 VZE_Verkehrszeichen_6 0;
BA_ "GenSigSendType" SG_ 2463978663 VZE_Verkehrszeichen_Einheit 3;
BA_ "GenSigSendType" SG_ 2463978663 VZE_Warnung_Verkehrszeichen_1 3;
BA_ "GenSigSendType" SG_ 2463978663 VZE_Warnung_Verkehrszeichen_2 3;
BA_ "GenSigSendType" SG_ 2463978663 VZE_Warnung_Verkehrszeichen_3 3;
BA_ "GenSigSendType" SG_ 2463978663 VZE_Warnung_Verkehrszeichen_4 3;
BA_ "GenSigSendType" SG_ 2463978663 VZE_Warnung_Verkehrszeichen_5 3;
BA_ "GenSigSendType" SG_ 2463978663 VZE_Warnung_VZ_1 0;
BA_ "GenSigSendType" SG_ 2463978663 VZE_Warnung_VZ_2 0;
BA_ "GenSigSendType" SG_ 2463978663 VZE_Warnung_VZ_3 0;
BA_ "GenSigSendType" SG_ 2463978663 VZE_Zeichen_01_Gesetz 3;
BA_ "GenSigSendType" SG_ 2463978663 VZE_Zeichen_01_Kamera 3;
BA_ "GenSigSendType" SG_ 2463978663 VZE_Zeichen_01_KameraWied 3;
BA_ "GenSigSendType" SG_ 2463978663 VZE_Zeichen_01_Karte 3;
BA_ "GenSigSendType" SG_ 2463978663 VZE_Zeichen_02_Gesetz 3;
BA_ "GenSigSendType" SG_ 2463978663 VZE_Zeichen_02_Kamera 3;
BA_ "GenSigSendType" SG_ 2463978663 VZE_Zeichen_02_KameraWied 3;
BA_ "GenSigSendType" SG_ 2463978663 VZE_Zeichen_02_Karte 3;
BA_ "GenSigSendType" SG_ 2463978663 VZE_Zeichen_03_Gesetz 3;
BA_ "GenSigSendType" SG_ 2463978663 VZE_Zeichen_03_Kamera 3;
BA_ "GenSigSendType" SG_ 2463978663 VZE_Zeichen_03_KameraWied 3;
BA_ "GenSigSendType" SG_ 2463978663 VZE_Zeichen_03_Karte 3;
BA_ "GenSigSendType" SG_ 2463978663 VZE_Zeichen_04_Gesetz 3;
BA_ "GenSigSendType" SG_ 2463978663 VZE_Zeichen_04_Kamera 3;
BA_ "GenSigSendType" SG_ 2463978663 VZE_Zeichen_04_KameraWied 3;
BA_ "GenSigSendType" SG_ 2463978663 VZE_Zeichen_04_Karte 3;
BA_ "GenSigSendType" SG_ 2463978663 VZE_Zeichen_05_Entfernung 0;
BA_ "GenSigSendType" SG_ 2463978663 VZE_Zeichen_05_Entfernung_StdA 0;
BA_ "GenSigSendType" SG_ 2463978663 VZE_Zeichen_05_Gesetz 3;
BA_ "GenSigSendType" SG_ 2463978663 VZE_Zeichen_05_Kamera 3;
BA_ "GenSigSendType" SG_ 2463978663 VZE_Zeichen_05_KameraWied 3;
BA_ "GenSigSendType" SG_ 2463978663 VZE_Zeichen_05_Karte 3;
BA_ "GenSigSendType" SG_ 2463978663 VZE_Zeichen_06_Entfernung 0;
BA_ "GenSigSendType" SG_ 2463978663 VZE_Zeichen_06_Entfernung_StdA 0;
BA_ "GenSigSendType" SG_ 2463978663 VZE_Zusatzschild_1 3;
BA_ "GenSigSendType" SG_ 2463978663 VZE_Zusatzschild_2 3;
BA_ "GenSigSendType" SG_ 2463978663 VZE_Zusatzschild_3 3;
BA_ "GenSigSendType" SG_ 2463978663 VZE_Zusatzschild_4 3;
BA_ "GenSigSendType" SG_ 2463978663 VZE_Zusatzschild_5 3;
BA_ "GenSigSendType" SG_ 2463978663 VZE_Zusatzschild_6 0;
BA_ "GenSigSendType" SG_ 181 Waehlhebel_04_BZ 0;
BA_ "GenSigFuncType" SG_ 181 Waehlhebel_04_BZ 1;
BA_ "GenSigSwitchedByIgnition" SG_ 181 Waehlhebel_04_BZ 0;
BA_ "GenSigSendType" SG_ 181 Waehlhebel_04_CRC 0;
BA_ "GenSigFuncType" SG_ 181 Waehlhebel_04_CRC 2;
BA_ "GenSigSwitchedByIgnition" SG_ 181 Waehlhebel_04_CRC 0;
BA_ "GenSigSendType" SG_ 181 WH_Ende_N_Haltephase 0;
BA_ "GenSigSwitchedByIgnition" SG_ 181 WH_Ende_N_Haltephase 0;
BA_ "GenSigSendType" SG_ 181 WH_Entsperrtaste_02 0;
BA_ "GenSigSwitchedByIgnition" SG_ 181 WH_Entsperrtaste_02 0;
BA_ "Fehlerwert" SG_ 181 WH_Entsperrtaste_02 3;
BA_ "GenSigSendType" SG_ 181 WH_Fahrstufe 0;
BA_ "GenSigSwitchedByIgnition" SG_ 181 WH_Fahrstufe 0;
BA_ "Fehlerwert" SG_ 181 WH_Fahrstufe 15;
BA_ "GenSigSendType" SG_ 181 WH_gespeicherte_Fahrstufe 0;
BA_ "GenSigSwitchedByIgnition" SG_ 181 WH_gespeicherte_Fahrstufe 0;
BA_ "GenSigSendType" SG_ 181 WH_Initialisierung 0;
BA_ "GenSigStartValue" SG_ 181 WH_Initialisierung 1;
BA_ "GenSigSwitchedByIgnition" SG_ 181 WH_Initialisierung 0;
BA_ "GenSigSendType" SG_ 181 WH_Ist_Haltemagnet 0;
BA_ "GenSigSwitchedByIgnition" SG_ 181 WH_Ist_Haltemagnet 0;
BA_ "Fehlerwert" SG_ 181 WH_Ist_Haltemagnet 3;
BA_ "GenSigSendType" SG_ 181 WH_P_Taste 0;
BA_ "GenSigSwitchedByIgnition" SG_ 181 WH_P_Taste 0;
BA_ "Fehlerwert" SG_ 181 WH_P_Taste 3;
BA_ "GenSigSendType" SG_ 181 WH_SensorPos_roh 0;
BA_ "GenSigSwitchedByIgnition" SG_ 181 WH_SensorPos_roh 0;
BA_ "Fehlerwert" SG_ 181 WH_SensorPos_roh 15;
BA_ "GenSigSendType" SG_ 181 WH_SensorPos_roh_inv 0;
BA_ "GenSigStartValue" SG_ 181 WH_SensorPos_roh_inv 15;
BA_ "GenSigSwitchedByIgnition" SG_ 181 WH_SensorPos_roh_inv 0;
BA_ "GenSigSendType" SG_ 181 WH_Status_Shiftlock 0;
BA_ "GenSigSwitchedByIgnition" SG_ 181 WH_Status_Shiftlock 0;
BA_ "Fehlerwert" SG_ 181 WH_Status_Shiftlock 7;
BA_ "GenSigSendType" SG_ 181 WH_Test_Aktiv 0;
BA_ "GenSigSwitchedByIgnition" SG_ 181 WH_Test_Aktiv 0;
BA_ "GenSigSendType" SG_ 181 WH_Testergebnis 0;
BA_ "GenSigSwitchedByIgnition" SG_ 181 WH_Testergebnis 0;
BA_ "GenSigSendType" SG_ 181 WH_Variante 0;
BA_ "GenSigSwitchedByIgnition" SG_ 181 WH_Variante 0;
BA_ "GenSigSendType" SG_ 181 WH_Zustand_N_Haltephase 0;
BA_ "GenSigSwitchedByIgnition" SG_ 181 WH_Zustand_N_Haltephase 0;
BA_ "GenSigSendType" SG_ 181 WH_Zustand_N_Haltephase_2 0;
BA_ "GenSigSwitchedByIgnition" SG_ 181 WH_Zustand_N_Haltephase_2 0;
BA_ "GenSigSendType" SG_ 2589283476 WH_FSA_HMI_Meldungen_01 0;
BA_ "GenSigSwitchedByIgnition" SG_ 2589283476 WH_FSA_HMI_Meldungen_01 0;
BA_ "GenSigSendType" SG_ 2589283476 WH_Schaltschema_Orientierung 0;
BA_ "GenSigSwitchedByIgnition" SG_ 2589283476 WH_Schaltschema_Orientierung 0;
BA_ "GenSigSendType" SG_ 2589283476 WH_Verbau_Entsperrtaste 0;
BA_ "GenSigSwitchedByIgnition" SG_ 2589283476 WH_Verbau_Entsperrtaste 0;
BA_ "GenSigSendType" SG_ 2589283476 WH_Warnung_02 3;
BA_ "GenSigSwitchedByIgnition" SG_ 2589283476 WH_Warnung_02 0;
BA_ "GenSigSendType" SG_ 2589283476 WH_Warnung_03 3;
BA_ "GenSigSwitchedByIgnition" SG_ 2589283476 WH_Warnung_03 0;
BA_ "GenSigSendType" SG_ 2463978687 WH_Fehler_Ausleuchtung 3;
BA_ "GenSigSwitchedByIgnition" SG_ 2463978687 WH_Fehler_Ausleuchtung 0;
BA_ "GenSigSendType" SG_ 2463978687 WH_Fehler_Ausleuchtung_Status 3;
BA_ "GenSigSwitchedByIgnition" SG_ 2463978687 WH_Fehler_Ausleuchtung_Status 0;
BA_ "GenSigSendType" SG_ 2463978687 WH_Fehler_BZ_SBM 3;
BA_ "GenSigSwitchedByIgnition" SG_ 2463978687 WH_Fehler_BZ_SBM 0;
BA_ "GenSigSendType" SG_ 2463978687 WH_Fehler_BZ_SBM_Status 3;
BA_ "GenSigSwitchedByIgnition" SG_ 2463978687 WH_Fehler_BZ_SBM_Status 0;
BA_ "GenSigSendType" SG_ 2463978687 WH_Fehler_CRC_SBM 3;
BA_ "GenSigSwitchedByIgnition" SG_ 2463978687 WH_Fehler_CRC_SBM 0;
BA_ "GenSigSendType" SG_ 2463978687 WH_Fehler_CRC_SBM_Status 3;
BA_ "GenSigSwitchedByIgnition" SG_ 2463978687 WH_Fehler_CRC_SBM_Status 0;
BA_ "GenSigSendType" SG_ 2463978687 WH_Fehler_Entsperrtaste 3;
BA_ "GenSigSwitchedByIgnition" SG_ 2463978687 WH_Fehler_Entsperrtaste 0;
BA_ "GenSigSendType" SG_ 2463978687 WH_Fehler_Entsperrtaste_Status 3;
BA_ "GenSigSwitchedByIgnition" SG_ 2463978687 WH_Fehler_Entsperrtaste_Status 0;
BA_ "GenSigSendType" SG_ 2463978687 WH_Fehler_Haltemagnet 3;
BA_ "GenSigSwitchedByIgnition" SG_ 2463978687 WH_Fehler_Haltemagnet 0;
BA_ "GenSigSendType" SG_ 2463978687 WH_Fehler_Haltemagnet_Status 3;
BA_ "GenSigSwitchedByIgnition" SG_ 2463978687 WH_Fehler_Haltemagnet_Status 0;
BA_ "GenSigSendType" SG_ 2463978687 WH_Fehler_P_Taste 3;
BA_ "GenSigSwitchedByIgnition" SG_ 2463978687 WH_Fehler_P_Taste 0;
BA_ "GenSigSendType" SG_ 2463978687 WH_Fehler_P_Taste_Status 3;
BA_ "GenSigSwitchedByIgnition" SG_ 2463978687 WH_Fehler_P_Taste_Status 0;
BA_ "GenSigSendType" SG_ 2463978687 WH_Fehler_Sensor_einfach 3;
BA_ "GenSigSwitchedByIgnition" SG_ 2463978687 WH_Fehler_Sensor_einfach 0;
BA_ "GenSigSendType" SG_ 2463978687 WH_Fehler_Sensor_einfach_Status 3;
BA_ "GenSigSwitchedByIgnition" SG_ 2463978687 WH_Fehler_Sensor_einfach_Status 0;
BA_ "GenSigSendType" SG_ 2463978687 WH_Fehler_Sensor_mehrfach 3;
BA_ "GenSigSwitchedByIgnition" SG_ 2463978687 WH_Fehler_Sensor_mehrfach 0;
BA_ "GenSigSendType" SG_ 2463978687 WH_Fehler_Sensor_mehrfach_Status 3;
BA_ "GenSigSwitchedByIgnition" SG_ 2463978687 WH_Fehler_Sensor_mehrfach_Status 0;
BA_ "GenSigSendType" SG_ 2463978687 WH_Fehler_Shiftlock 3;
BA_ "GenSigSwitchedByIgnition" SG_ 2463978687 WH_Fehler_Shiftlock 0;
BA_ "GenSigSendType" SG_ 2463978687 WH_Fehler_Shiftlock_Status 3;
BA_ "GenSigSwitchedByIgnition" SG_ 2463978687 WH_Fehler_Shiftlock_Status 0;
BA_ "GenSigSendType" SG_ 2463978687 WH_Fehler_Timeout_SBM 3;
BA_ "GenSigSwitchedByIgnition" SG_ 2463978687 WH_Fehler_Timeout_SBM 0;
BA_ "GenSigSendType" SG_ 2463978687 WH_Fehler_Timeout_SBM_Status 3;
BA_ "GenSigSwitchedByIgnition" SG_ 2463978687 WH_Fehler_Timeout_SBM_Status 0;
BA_ "GenSigSendType" SG_ 2463978687 WH_Fehler_Ueberspannung 3;
BA_ "GenSigSwitchedByIgnition" SG_ 2463978687 WH_Fehler_Ueberspannung 0;
BA_ "GenSigSendType" SG_ 2463978687 WH_Fehler_Ueberspannung_Status 3;
BA_ "GenSigSwitchedByIgnition" SG_ 2463978687 WH_Fehler_Ueberspannung_Status 0;
BA_ "GenSigSendType" SG_ 2463978687 WH_Fehler_Unterspannung 3;
BA_ "GenSigSwitchedByIgnition" SG_ 2463978687 WH_Fehler_Unterspannung 0;
BA_ "GenSigSendType" SG_ 2463978687 WH_Fehler_Unterspannung_Status 3;
BA_ "GenSigSwitchedByIgnition" SG_ 2463978687 WH_Fehler_Unterspannung_Status 0;
BA_ "GenSigSendType" SG_ 916 GE_Sollgang 4;
BA_ "GenSigSwitchedByIgnition" SG_ 916 GE_Sollgang 0;
BA_ "GenSigSendType" SG_ 916 GE_Stoppverbot_Anz_01 0;
BA_ "GenSigSwitchedByIgnition" SG_ 916 GE_Stoppverbot_Anz_01 0;
BA_ "GenSigSendType" SG_ 916 GE_Stoppverbot_Anz_02 0;
BA_ "GenSigSwitchedByIgnition" SG_ 916 GE_Stoppverbot_Anz_02 0;
BA_ "GenSigSendType" SG_ 916 GE_Stoppverbot_Anz_03 0;
BA_ "GenSigSwitchedByIgnition" SG_ 916 GE_Stoppverbot_Anz_03 0;
BA_ "GenSigSendType" SG_ 916 GE_Stoppverbot_Anz_04 0;
BA_ "GenSigSwitchedByIgnition" SG_ 916 GE_Stoppverbot_Anz_04 0;
BA_ "GenSigSendType" SG_ 916 GE_Stoppverbot_Anz_05 0;
BA_ "GenSigSwitchedByIgnition" SG_ 916 GE_Stoppverbot_Anz_05 0;
BA_ "GenSigSendType" SG_ 916 GE_Stoppverbot_Anz_06 0;
BA_ "GenSigSwitchedByIgnition" SG_ 916 GE_Stoppverbot_Anz_06 0;
BA_ "GenSigSendType" SG_ 916 GE_Stoppverbot_Anz_07 0;
BA_ "GenSigSwitchedByIgnition" SG_ 916 GE_Stoppverbot_Anz_07 0;
BA_ "GenSigSendType" SG_ 916 GE_Stoppverbot_Anz_Std 0;
BA_ "GenSigSwitchedByIgnition" SG_ 916 GE_Stoppverbot_Anz_Std 0;
BA_ "GenSigSendType" SG_ 916 GE_Tipschaltempf_verfuegbar 0;
BA_ "GenSigFuncType" SG_ 916 GE_Tipschaltempf_verfuegbar 8;
BA_ "GenSigSwitchedByIgnition" SG_ 916 GE_Tipschaltempf_verfuegbar 0;
BA_ "GenSigSendType" SG_ 916 GE_Wiederstart_Anz_Std 0;
BA_ "GenSigSwitchedByIgnition" SG_ 916 GE_Wiederstart_Anz_Std 0;
BA_ "GenSigSendType" SG_ 916 WBA_03_BZ 0;
BA_ "GenSigFuncType" SG_ 916 WBA_03_BZ 1;
BA_ "GenSigSwitchedByIgnition" SG_ 916 WBA_03_BZ 0;
BA_ "GenSigSendType" SG_ 916 WBA_03_CRC 0;
BA_ "GenSigFuncType" SG_ 916 WBA_03_CRC 2;
BA_ "GenSigSwitchedByIgnition" SG_ 916 WBA_03_CRC 0;
BA_ "GenSigSendType" SG_ 916 WBA_Anforderung_Akustik 4;
BA_ "GenSigSwitchedByIgnition" SG_ 916 WBA_Anforderung_Akustik 0;
BA_ "GenSigSendType" SG_ 916 WBA_Blinken 3;
BA_ "GenSigSwitchedByIgnition" SG_ 916 WBA_Blinken 0;
BA_ "GenSigSendType" SG_ 916 WBA_eing_Gang_02 4;
BA_ "GenSigSwitchedByIgnition" SG_ 916 WBA_eing_Gang_02 0;
BA_ "GenSigSendType" SG_ 916 WBA_Fahrstufe_02 4;
BA_ "GenSigSwitchedByIgnition" SG_ 916 WBA_Fahrstufe_02 0;
BA_ "GenSigSendType" SG_ 916 WBA_GE_Texte 4;
BA_ "GenSigSwitchedByIgnition" SG_ 916 WBA_GE_Texte 0;
BA_ "GenSigSendType" SG_ 916 WBA_GE_Texte_02 0;
BA_ "GenSigSwitchedByIgnition" SG_ 916 WBA_GE_Texte_02 0;
BA_ "GenSigSendType" SG_ 916 WBA_GE_Warnung_02 4;
BA_ "GenSigSwitchedByIgnition" SG_ 916 WBA_GE_Warnung_02 0;
BA_ "GenSigSendType" SG_ 916 WBA_GE_Zusatzwarnungen 4;
BA_ "GenSigSwitchedByIgnition" SG_ 916 WBA_GE_Zusatzwarnungen 0;
BA_ "GenSigSendType" SG_ 916 WBA_Schaltschema_02 4;
BA_ "GenSigSwitchedByIgnition" SG_ 916 WBA_Schaltschema_02 0;
BA_ "GenSigSendType" SG_ 916 WBA_Schaltschema_Fahreraktion 4;
BA_ "GenSigSwitchedByIgnition" SG_ 916 WBA_Schaltschema_Fahreraktion 0;
BA_ "GenSigSendType" SG_ 916 WBA_Schaltschema_FS_inaktiv 4;
BA_ "GenSigSwitchedByIgnition" SG_ 916 WBA_Schaltschema_FS_inaktiv 0;
BA_ "GenSigSendType" SG_ 916 WBA_Schaltschema_FS_vorwaerts 4;
BA_ "GenSigSwitchedByIgnition" SG_ 916 WBA_Schaltschema_FS_vorwaerts 0;
BA_ "GenSigSendType" SG_ 916 WBA_Schaltschema_Tippgasse 4;
BA_ "GenSigSwitchedByIgnition" SG_ 916 WBA_Schaltschema_Tippgasse 0;
BA_ "GenSigSendType" SG_ 916 WBA_Segeln_aktiv 4;
BA_ "GenSigSwitchedByIgnition" SG_ 916 WBA_Segeln_aktiv 0;
BA_ "GenSigSendType" SG_ 916 WBA_Shiftlock_Lampe 4;
BA_ "GenSigSwitchedByIgnition" SG_ 916 WBA_Shiftlock_Lampe 0;
BA_ "GenSigSendType" SG_ 916 WBA_ZielFahrstufe 3;
BA_ "GenSigSwitchedByIgnition" SG_ 916 WBA_ZielFahrstufe 0;
BA_ "GenSigSendType" SG_ 1361 WFS_Betrieb_Lesespule 3;
BA_ "GenSigSwitchedByIgnition" SG_ 1361 WFS_Betrieb_Lesespule 0;
BA_ "GenSigSendType" SG_ 1361 WFS_ELV_authorisiert 3;
BA_ "GenSigSwitchedByIgnition" SG_ 1361 WFS_ELV_authorisiert 0;
BA_ "GenSigSendType" SG_ 1361 WFS_Fahrerhinweise 3;
BA_ "GenSigSwitchedByIgnition" SG_ 1361 WFS_Fahrerhinweise 0;
BA_ "GenSigSendType" SG_ 1361 WFS_ID_Geb_autorisiert 3;
BA_ "GenSigSwitchedByIgnition" SG_ 1361 WFS_ID_Geb_autorisiert 0;
BA_ "GenSigSendType" SG_ 1361 WFS_ID_Geb_autorisiert_in_Kl15 3;
BA_ "GenSigSwitchedByIgnition" SG_ 1361 WFS_ID_Geb_autorisiert_in_Kl15 0;
BA_ "GenSigSendType" SG_ 1361 WFS_ID_Geb_steckt 3;
BA_ "GenSigSwitchedByIgnition" SG_ 1361 WFS_ID_Geb_steckt 0;
BA_ "GenSigSendType" SG_ 1361 WFS_Klemmenfreigabe 3;
BA_ "GenSigSwitchedByIgnition" SG_ 1361 WFS_Klemmenfreigabe 0;
BA_ "GenSigSendType" SG_ 1361 WFS_Klemmenfreigabe_Signatur 3;
BA_ "GenSigSwitchedByIgnition" SG_ 1361 WFS_Klemmenfreigabe_Signatur 0;
BA_ "GenSigSendType" SG_ 1361 WFS_LF_Aktiv 3;
BA_ "GenSigSwitchedByIgnition" SG_ 1361 WFS_LF_Aktiv 0;
BA_ "GenSigSendType" SG_ 1361 WFS_LZ 3;
BA_ "GenSigSwitchedByIgnition" SG_ 1361 WFS_LZ 0;
BA_ "GenSigSendType" SG_ 1361 WFS_Parken_Status 3;
BA_ "GenSigSwitchedByIgnition" SG_ 1361 WFS_Parken_Status 0;
BA_ "GenSigSendType" SG_ 1361 WFS_Safe 3;
BA_ "GenSigSwitchedByIgnition" SG_ 1361 WFS_Safe 0;
BA_ "GenSigSendType" SG_ 1361 WFS_Schluessel_Fahrberecht 0;
BA_ "GenSigSwitchedByIgnition" SG_ 1361 WFS_Schluessel_Fahrberecht 0;
BA_ "GenSigSendType" SG_ 1361 WFS_Schluessel_Ist 3;
BA_ "GenSigSwitchedByIgnition" SG_ 1361 WFS_Schluessel_Ist 0;
BA_ "GenSigSendType" SG_ 1361 WFS_Schluessel_Soll 3;
BA_ "GenSigSwitchedByIgnition" SG_ 1361 WFS_Schluessel_Soll 0;
BA_ "GenSigSendType" SG_ 1361 WFS_Verbauinfo_ELV 3;
BA_ "GenSigSwitchedByIgnition" SG_ 1361 WFS_Verbauinfo_ELV 0;
BA_ "GenSigSendType" SG_ 1702 BCM1_SRA_aktiv 3;
BA_ "GenSigSwitchedByIgnition" SG_ 1702 BCM1_SRA_aktiv 0;
BA_ "GenSigActiveRepetitions" SG_ 1702 Heckwischer_Anforderung 3;
BA_ "GenSigSendType" SG_ 1702 Heckwischer_Anforderung 4;
BA_ "GenSigSwitchedByIgnition" SG_ 1702 Heckwischer_Anforderung 0;
BA_ "GenSigSendType" SG_ 1702 Waschen_vorne_aktiv 3;
BA_ "GenSigSwitchedByIgnition" SG_ 1702 Waschen_vorne_aktiv 0;
BA_ "GenSigSendType" SG_ 1702 Wischer1_Wischgeschwindigkeit 0;
BA_ "GenSigStartValue" SG_ 1702 Wischer1_Wischgeschwindigkeit 62;
BA_ "GenSigSwitchedByIgnition" SG_ 1702 Wischer1_Wischgeschwindigkeit 0;
BA_ "Fehlerwert" SG_ 1702 Wischer1_Wischgeschwindigkeit 63;
BA_ "GenSigSendType" SG_ 1702 Wischer_Anzeigetext 3;
BA_ "GenSigSwitchedByIgnition" SG_ 1702 Wischer_Anzeigetext 0;
BA_ "GenSigSendType" SG_ 1702 Wischer_vorne_aktiv 3;
BA_ "GenSigSwitchedByIgnition" SG_ 1702 Wischer_vorne_aktiv 0;
BA_ "GenSigSendType" SG_ 1702 Wischer_vorne_blockiert 3;
BA_ "GenSigSwitchedByIgnition" SG_ 1702 Wischer_vorne_blockiert 0;
BA_ "GenSigSendType" SG_ 1702 Wischer_vorne_defekt 3;
BA_ "GenSigSwitchedByIgnition" SG_ 1702 Wischer_vorne_defekt 0;
BA_ "GenSigSendType" SG_ 1702 Wischer_vorne_Normal 3;
BA_ "GenSigSwitchedByIgnition" SG_ 1702 Wischer_vorne_Normal 0;
BA_ "GenSigSendType" SG_ 1702 Wischer_vorne_Parklage 3;
BA_ "GenSigStartValue" SG_ 1702 Wischer_vorne_Parklage 1;
BA_ "GenSigSwitchedByIgnition" SG_ 1702 Wischer_vorne_Parklage 0;
BA_ "GenSigSendType" SG_ 1702 Wischer_vorne_Schnell 3;
BA_ "GenSigSwitchedByIgnition" SG_ 1702 Wischer_vorne_Schnell 0;
BA_ "GenSigSendType" SG_ 1702 Wischer_WH_PopUp_Anf 3;
BA_ "GenSigSwitchedByIgnition" SG_ 1702 Wischer_WH_PopUp_Anf 0;
BA_ "GenSigSendType" SG_ 1702 Wischer_WH_Typ 0;
BA_ "GenSigSwitchedByIgnition" SG_ 1702 Wischer_WH_Typ 0;
BA_ "GenSigSendType" SG_ 1702 WWSs_01_alt 0;
BA_ "GenSigStartValue" SG_ 1702 WWSs_01_alt 1;
BA_ "GenSigFuncType" SG_ 1702 WWSs_01_alt 5;
BA_ "GenSigSwitchedByIgnition" SG_ 1702 WWSs_01_alt 0;
BA_ "GenSigSendType" SG_ 1602 WIV_Russindex 0;
BA_ "GenSigSwitchedByIgnition" SG_ 1602 WIV_Russindex 0;
BA_ "Fehlerwert" SG_ 1602 WIV_Russindex 65535;
BA_ "GenSigSendType" SG_ 1602 WIV_t_max 0;
BA_ "GenSigStartValue" SG_ 1602 WIV_t_max 24;
BA_ "GenSigSwitchedByIgnition" SG_ 1602 WIV_t_max 0;
BA_ "GenSigSendType" SG_ 1602 WIV_t_min 0;
BA_ "GenSigStartValue" SG_ 1602 WIV_t_min 12;
BA_ "GenSigSwitchedByIgnition" SG_ 1602 WIV_t_min 0;
BA_ "GenSigSendType" SG_ 1602 WIV_Verschleissindex 0;
BA_ "GenSigSwitchedByIgnition" SG_ 1602 WIV_Verschleissindex 0;
BA_ "Fehlerwert" SG_ 1602 WIV_Verschleissindex 65535;
BA_ "GenSigSendType" SG_ 1602 WIV_W_max 0;
BA_ "GenSigStartValue" SG_ 1602 WIV_W_max 31;
BA_ "GenSigSwitchedByIgnition" SG_ 1602 WIV_W_max 0;
BA_ "GenSigSendType" SG_ 1602 WIV_W_min 0;
BA_ "GenSigStartValue" SG_ 1602 WIV_W_min 17;
BA_ "GenSigSwitchedByIgnition" SG_ 1602 WIV_W_min 0;
BA_ "GenSigFuncType" SG_ 2617228832 XCP_Getriebe_CRO_20_Data 9;
BA_ "GenSigSwitchedByIgnition" SG_ 2617228832 XCP_Getriebe_CRO_20_Data 0;
BA_ "GenSigFuncType" SG_ 2617228834 XCP_Getriebe_CRO_22_Data 9;
BA_ "GenSigSwitchedByIgnition" SG_ 2617228834 XCP_Getriebe_CRO_22_Data 0;
BA_ "GenSigFuncType" SG_ 2617228836 XCP_Getriebe_CRO_24_Data 9;
BA_ "GenSigSwitchedByIgnition" SG_ 2617228836 XCP_Getriebe_CRO_24_Data 0;
BA_ "GenSigFuncType" SG_ 2617228833 XCP_Getriebe_DTO_21_Data 9;
BA_ "GenSigSwitchedByIgnition" SG_ 2617228833 XCP_Getriebe_DTO_21_Data 0;
BA_ "GenSigFuncType" SG_ 2617228835 XCP_Getriebe_DTO_23_Data 9;
BA_ "GenSigSwitchedByIgnition" SG_ 2617228835 XCP_Getriebe_DTO_23_Data 0;
BA_ "GenSigFuncType" SG_ 2617228837 XCP_Getriebe_DTO_25_Data 9;
BA_ "GenSigSwitchedByIgnition" SG_ 2617228837 XCP_Getriebe_DTO_25_Data 0;
BA_ "GenSigFuncType" SG_ 2617226768 XCP_Motor_CRO_01_Data 9;
BA_ "GenSigSwitchedByIgnition" SG_ 2617226768 XCP_Motor_CRO_01_Data 0;
BA_ "GenSigFuncType" SG_ 2617226769 XCP_Motor_DTO_01_Data 9;
BA_ "GenSigSwitchedByIgnition" SG_ 2617226769 XCP_Motor_DTO_01_Data 0;
BA_ "GenSigSwitchedByIgnition" SG_ 2566734336 XCP_Parksperre_CRO_01_Data 0;
BA_ "GenSigSwitchedByIgnition" SG_ 2566734337 XCP_Parksperre_DTO_01_Data 0;
BA_ "GenSigSendType" SG_ 388 BCM_BF_Spg_Absenkung 0;
BA_ "GenSigSwitchedByIgnition" SG_ 388 BCM_BF_Spg_Absenkung 0;
BA_ "GenSigSendType" SG_ 388 BCM_Spg_Synchron 0;
BA_ "GenSigSwitchedByIgnition" SG_ 388 BCM_Spg_Synchron 0;
BA_ "GenSigSendType" SG_ 388 FH_BT_hoch 6;
BA_ "GenSigSwitchedByIgnition" SG_ 388 FH_BT_hoch 0;
BA_ "GenSigSendType" SG_ 388 FH_BT_tief 6;
BA_ "GenSigSwitchedByIgnition" SG_ 388 FH_BT_tief 0;
BA_ "GenSigSendType" SG_ 388 FH_FT_hoch 6;
BA_ "GenSigSwitchedByIgnition" SG_ 388 FH_FT_hoch 0;
BA_ "GenSigSendType" SG_ 388 FH_FT_tief 6;
BA_ "GenSigSwitchedByIgnition" SG_ 388 FH_FT_tief 0;
BA_ "GenSigSendType" SG_ 388 FH_HBFS_hoch 6;
BA_ "GenSigSwitchedByIgnition" SG_ 388 FH_HBFS_hoch 0;
BA_ "GenSigSendType" SG_ 388 FH_HBFS_tief 6;
BA_ "GenSigSwitchedByIgnition" SG_ 388 FH_HBFS_tief 0;
BA_ "GenSigSendType" SG_ 388 FH_HFS_hoch 6;
BA_ "GenSigSwitchedByIgnition" SG_ 388 FH_HFS_hoch 0;
BA_ "GenSigSendType" SG_ 388 FH_HFS_tief 6;
BA_ "GenSigSwitchedByIgnition" SG_ 388 FH_HFS_tief 0;
BA_ "GenSigSendType" SG_ 388 VIP_Freigabe 0;
BA_ "GenSigSwitchedByIgnition" SG_ 388 VIP_Freigabe 0;
BA_ "GenSigSendType" SG_ 388 VIP_Sensor_betaetigt 6;
BA_ "GenSigSwitchedByIgnition" SG_ 388 VIP_Sensor_betaetigt 0;
BA_ "GenSigSendType" SG_ 388 ZV_01_BZ 0;
BA_ "GenSigFuncType" SG_ 388 ZV_01_BZ 1;
BA_ "GenSigSendType" SG_ 388 ZV_01_CRC 0;
BA_ "GenSigFuncType" SG_ 388 ZV_01_CRC 2;
BA_ "GenSigSendType" SG_ 388 ZV_auf_BT 6;
BA_ "GenSigSwitchedByIgnition" SG_ 388 ZV_auf_BT 0;
BA_ "GenSigSendType" SG_ 388 ZV_auf_FT 6;
BA_ "GenSigSwitchedByIgnition" SG_ 388 ZV_auf_FT 0;
BA_ "GenSigSendType" SG_ 388 ZV_auf_Funk 6;
BA_ "GenSigSwitchedByIgnition" SG_ 388 ZV_auf_Funk 0;
BA_ "GenSigSendType" SG_ 388 ZV_auf_Kessy 6;
BA_ "GenSigSwitchedByIgnition" SG_ 388 ZV_auf_Kessy 0;
BA_ "GenSigSendType" SG_ 388 ZV_auto_Ansteuerung 6;
BA_ "GenSigSwitchedByIgnition" SG_ 388 ZV_auto_Ansteuerung 0;
BA_ "GenSigSendType" SG_ 388 ZV_BT_entriegeln 6;
BA_ "GenSigSwitchedByIgnition" SG_ 388 ZV_BT_entriegeln 0;
BA_ "GenSigSendType" SG_ 388 ZV_BT_verriegeln 6;
BA_ "GenSigSwitchedByIgnition" SG_ 388 ZV_BT_verriegeln 0;
BA_ "GenSigSendType" SG_ 388 ZV_entriegeln_Anf 6;
BA_ "GenSigSwitchedByIgnition" SG_ 388 ZV_entriegeln_Anf 0;
BA_ "GenSigSendType" SG_ 388 ZV_FT_entriegeln 6;
BA_ "GenSigSwitchedByIgnition" SG_ 388 ZV_FT_entriegeln 0;
BA_ "GenSigSendType" SG_ 388 ZV_FT_verriegeln 6;
BA_ "GenSigSwitchedByIgnition" SG_ 388 ZV_FT_verriegeln 0;
BA_ "GenSigSendType" SG_ 388 ZV_HBFS_entriegeln 6;
BA_ "GenSigSwitchedByIgnition" SG_ 388 ZV_HBFS_entriegeln 0;
BA_ "GenSigSendType" SG_ 388 ZV_HBFS_verriegeln 6;
BA_ "GenSigSwitchedByIgnition" SG_ 388 ZV_HBFS_verriegeln 0;
BA_ "GenSigSendType" SG_ 388 ZV_HFS_entriegeln 6;
BA_ "GenSigSwitchedByIgnition" SG_ 388 ZV_HFS_entriegeln 0;
BA_ "GenSigSendType" SG_ 388 ZV_HFS_verriegeln 6;
BA_ "GenSigSwitchedByIgnition" SG_ 388 ZV_HFS_verriegeln 0;
BA_ "GenSigSendType" SG_ 388 ZV_HSK_entriegeln 6;
BA_ "GenSigSwitchedByIgnition" SG_ 388 ZV_HSK_entriegeln 0;
BA_ "GenSigSendType" SG_ 388 ZV_HSK_verriegeln 6;
BA_ "GenSigSwitchedByIgnition" SG_ 388 ZV_HSK_verriegeln 0;
BA_ "GenSigSendType" SG_ 388 ZV_LED_Steuerung 6;
BA_ "GenSigSwitchedByIgnition" SG_ 388 ZV_LED_Steuerung 0;
BA_ "GenSigSendType" SG_ 388 ZV_LED_Uebernahme 6;
BA_ "GenSigSwitchedByIgnition" SG_ 388 ZV_LED_Uebernahme 0;
BA_ "GenSigSendType" SG_ 388 ZV_Signatur 6;
BA_ "GenSigSwitchedByIgnition" SG_ 388 ZV_Signatur 0;
BA_ "GenSigSendType" SG_ 388 ZV_Softtouch_betaetigt 6;
BA_ "GenSigSwitchedByIgnition" SG_ 388 ZV_Softtouch_betaetigt 0;
BA_ "GenSigSendType" SG_ 388 ZV_Spg_Anklappen 6;
BA_ "GenSigSwitchedByIgnition" SG_ 388 ZV_Spg_Anklappen 0;
BA_ "GenSigSendType" SG_ 388 ZV_Verdeck_auf 6;
BA_ "GenSigSwitchedByIgnition" SG_ 388 ZV_Verdeck_auf 0;
BA_ "GenSigSendType" SG_ 388 ZV_Verdeck_zu 6;
BA_ "GenSigSwitchedByIgnition" SG_ 388 ZV_Verdeck_zu 0;
BA_ "GenSigSendType" SG_ 388 ZV_zentral_entsafen 6;
BA_ "GenSigSwitchedByIgnition" SG_ 388 ZV_zentral_entsafen 0;
BA_ "GenSigSendType" SG_ 388 ZV_zentral_safen 6;
BA_ "GenSigSwitchedByIgnition" SG_ 388 ZV_zentral_safen 0;
BA_ "GenSigSendType" SG_ 388 ZV_zu_BT 6;
BA_ "GenSigSwitchedByIgnition" SG_ 388 ZV_zu_BT 0;
BA_ "GenSigSendType" SG_ 388 ZV_zu_FT 6;
BA_ "GenSigSwitchedByIgnition" SG_ 388 ZV_zu_FT 0;
BA_ "GenSigSendType" SG_ 388 ZV_zu_Funk 6;
BA_ "GenSigSwitchedByIgnition" SG_ 388 ZV_zu_Funk 0;
BA_ "GenSigSendType" SG_ 388 ZV_zu_Kessy 6;
BA_ "GenSigSwitchedByIgnition" SG_ 388 ZV_zu_Kessy 0;
BA_ "GenSigSendType" SG_ 388 ZV_zu_Zeitl_Nachverr 6;
BA_ "GenSigSwitchedByIgnition" SG_ 388 ZV_zu_Zeitl_Nachverr 0;
BA_ "GenSigSendType" SG_ 1411 BCM_FH_Freigabe 3;
BA_ "GenSigSwitchedByIgnition" SG_ 1411 BCM_FH_Freigabe 0;
BA_ "GenSigSendType" SG_ 1411 BCM_HSK_Freigabe 3;
BA_ "GenSigSwitchedByIgnition" SG_ 1411 BCM_HSK_Freigabe 0;
BA_ "GenSigSendType" SG_ 1411 BCM_Komfortfkt_Freigabe 3;
BA_ "GenSigSwitchedByIgnition" SG_ 1411 BCM_Komfortfkt_Freigabe 0;
BA_ "GenSigSendType" SG_ 1411 BCM_Tankklappensteller_Fehler 0;
BA_ "GenSigSwitchedByIgnition" SG_ 1411 BCM_Tankklappensteller_Fehler 0;
BA_ "Fehlerwert" SG_ 1411 BCM_Tankklappensteller_Fehler 1;
BA_ "GenSigSendType" SG_ 1411 BCM_Verdeck_Freigabe 3;
BA_ "GenSigSwitchedByIgnition" SG_ 1411 BCM_Verdeck_Freigabe 0;
BA_ "GenSigSendType" SG_ 1411 DWA_aktiv 3;
BA_ "GenSigSwitchedByIgnition" SG_ 1411 DWA_aktiv 0;
BA_ "GenSigSendType" SG_ 1411 FBS_IDG_in_Reichweite 6;
BA_ "GenSigSwitchedByIgnition" SG_ 1411 FBS_IDG_in_Reichweite 0;
BA_ "GenSigSendType" SG_ 1411 FBS_Warn_Schluessel_Batt 3;
BA_ "GenSigSwitchedByIgnition" SG_ 1411 FBS_Warn_Schluessel_Batt 0;
BA_ "GenSigSendType" SG_ 1411 FFB_Auf_Taste 6;
BA_ "GenSigSwitchedByIgnition" SG_ 1411 FFB_Auf_Taste 0;
BA_ "GenSigSendType" SG_ 1411 FFB_CarFinder 6;
BA_ "GenSigSwitchedByIgnition" SG_ 1411 FFB_CarFinder 0;
BA_ "GenSigSendType" SG_ 1411 FFB_HDF_Taste 6;
BA_ "GenSigSwitchedByIgnition" SG_ 1411 FFB_HDF_Taste 0;
BA_ "GenSigSendType" SG_ 1411 FFB_Komfortoeffnen 6;
BA_ "GenSigSwitchedByIgnition" SG_ 1411 FFB_Komfortoeffnen 0;
BA_ "GenSigSendType" SG_ 1411 FFB_Komfortschliessen 6;
BA_ "GenSigSwitchedByIgnition" SG_ 1411 FFB_Komfortschliessen 0;
BA_ "GenSigSendType" SG_ 1411 FFB_Panik_Taste 6;
BA_ "GenSigSwitchedByIgnition" SG_ 1411 FFB_Panik_Taste 0;
BA_ "GenSigSendType" SG_ 1411 FFB_Zu_Taste 6;
BA_ "GenSigSwitchedByIgnition" SG_ 1411 FFB_Zu_Taste 0;
BA_ "GenSigSendType" SG_ 1411 HBFS_gesafet 3;
BA_ "GenSigSwitchedByIgnition" SG_ 1411 HBFS_gesafet 0;
BA_ "GenSigSendType" SG_ 1411 HBFS_verriegelt 3;
BA_ "GenSigSwitchedByIgnition" SG_ 1411 HBFS_verriegelt 0;
BA_ "GenSigSendType" SG_ 1411 HD_Hauptraste 3;
BA_ "GenSigSwitchedByIgnition" SG_ 1411 HD_Hauptraste 0;
BA_ "GenSigSendType" SG_ 1411 HD_Vorraste 3;
BA_ "GenSigSwitchedByIgnition" SG_ 1411 HD_Vorraste 0;
BA_ "GenSigSendType" SG_ 1411 HFS_gesafet 3;
BA_ "GenSigSwitchedByIgnition" SG_ 1411 HFS_gesafet 0;
BA_ "GenSigSendType" SG_ 1411 HFS_verriegelt 3;
BA_ "GenSigSwitchedByIgnition" SG_ 1411 HFS_verriegelt 0;
BA_ "GenSigSendType" SG_ 1411 IRUE_aktiv 3;
BA_ "GenSigSwitchedByIgnition" SG_ 1411 IRUE_aktiv 0;
BA_ "GenSigSendType" SG_ 1411 IRUE_Taster_Fkts_LED 3;
BA_ "GenSigSwitchedByIgnition" SG_ 1411 IRUE_Taster_Fkts_LED 0;
BA_ "GenSigSendType" SG_ 1411 VIP_Sensor_STSG_HBFS_betaetigt 6;
BA_ "GenSigSwitchedByIgnition" SG_ 1411 VIP_Sensor_STSG_HBFS_betaetigt 0;
BA_ "GenSigSendType" SG_ 1411 VIP_Sensor_STSG_HFS_betaetigt 6;
BA_ "GenSigSwitchedByIgnition" SG_ 1411 VIP_Sensor_STSG_HFS_betaetigt 0;
BA_ "GenSigSendType" SG_ 1411 ZV_Anf_Challenge_Auth 6;
BA_ "GenSigSwitchedByIgnition" SG_ 1411 ZV_Anf_Challenge_Auth 0;
BA_ "GenSigSendType" SG_ 1411 ZV_BT_offen 3;
BA_ "GenSigSwitchedByIgnition" SG_ 1411 ZV_BT_offen 0;
BA_ "GenSigSendType" SG_ 1411 ZV_Einzeltuerentriegelung 3;
BA_ "GenSigSwitchedByIgnition" SG_ 1411 ZV_Einzeltuerentriegelung 0;
BA_ "GenSigSendType" SG_ 1411 ZV_eRWK_Umfeld_Pruefung 6;
BA_ "GenSigSwitchedByIgnition" SG_ 1411 ZV_eRWK_Umfeld_Pruefung 0;
BA_ "GenSigSendType" SG_ 1411 ZV_FT_offen 3;
BA_ "GenSigSwitchedByIgnition" SG_ 1411 ZV_FT_offen 0;
BA_ "GenSigSendType" SG_ 1411 ZV_gesafet_extern_ist 3;
BA_ "GenSigSwitchedByIgnition" SG_ 1411 ZV_gesafet_extern_ist 0;
BA_ "GenSigSendType" SG_ 1411 ZV_gesafet_extern_soll 3;
BA_ "GenSigSwitchedByIgnition" SG_ 1411 ZV_gesafet_extern_soll 0;
BA_ "GenSigSendType" SG_ 1411 ZV_HBFS_offen 3;
BA_ "GenSigSwitchedByIgnition" SG_ 1411 ZV_HBFS_offen 0;
BA_ "GenSigSendType" SG_ 1411 ZV_HD_offen 3;
BA_ "GenSigSwitchedByIgnition" SG_ 1411 ZV_HD_offen 0;
BA_ "GenSigSendType" SG_ 1411 ZV_Heckeinzelentriegelung 3;
BA_ "GenSigSwitchedByIgnition" SG_ 1411 ZV_Heckeinzelentriegelung 0;
BA_ "GenSigSendType" SG_ 1411 ZV_HFS_offen 3;
BA_ "GenSigSwitchedByIgnition" SG_ 1411 ZV_HFS_offen 0;
BA_ "GenSigSendType" SG_ 1411 ZV_HS_offen 3;
BA_ "GenSigSwitchedByIgnition" SG_ 1411 ZV_HS_offen 0;
BA_ "GenSigSendType" SG_ 1411 ZV_ist_Zustand_verfuegbar 3;
BA_ "GenSigSwitchedByIgnition" SG_ 1411 ZV_ist_Zustand_verfuegbar 0;
BA_ "GenSigSendType" SG_ 1411 ZV_Oeffnungsmodus 3;
BA_ "GenSigSwitchedByIgnition" SG_ 1411 ZV_Oeffnungsmodus 0;
BA_ "GenSigSendType" SG_ 1411 ZV_Rollo_auf 3;
BA_ "GenSigSwitchedByIgnition" SG_ 1411 ZV_Rollo_auf 0;
BA_ "GenSigSendType" SG_ 1411 ZV_Rollo_zu 3;
BA_ "GenSigSwitchedByIgnition" SG_ 1411 ZV_Rollo_zu 0;
BA_ "GenSigSendType" SG_ 1411 ZV_SAD_auf 3;
BA_ "GenSigSwitchedByIgnition" SG_ 1411 ZV_SAD_auf 0;
BA_ "GenSigSendType" SG_ 1411 ZV_SAD_zu 3;
BA_ "GenSigSwitchedByIgnition" SG_ 1411 ZV_SAD_zu 0;
BA_ "GenSigSendType" SG_ 1411 ZV_SafeFunktion_aktiv 3;
BA_ "GenSigSwitchedByIgnition" SG_ 1411 ZV_SafeFunktion_aktiv 0;
BA_ "GenSigSendType" SG_ 1411 ZV_Schluessel_Zugang 3;
BA_ "GenSigSwitchedByIgnition" SG_ 1411 ZV_Schluessel_Zugang 0;
BA_ "GenSigSendType" SG_ 1411 ZV_STSG_Crashzustand 4;
BA_ "GenSigSwitchedByIgnition" SG_ 1411 ZV_STSG_Crashzustand 0;
BA_ "GenSigSendType" SG_ 1411 ZV_STSG_eKiSi_defekt 4;
BA_ "GenSigSwitchedByIgnition" SG_ 1411 ZV_STSG_eKiSi_defekt 0;
BA_ "GenSigSendType" SG_ 1411 ZV_STSG_HBFS_Anf 3;
BA_ "GenSigSwitchedByIgnition" SG_ 1411 ZV_STSG_HBFS_Anf 0;
BA_ "GenSigSendType" SG_ 1411 ZV_STSG_HFS_Anf 3;
BA_ "GenSigSwitchedByIgnition" SG_ 1411 ZV_STSG_HFS_Anf 0;
BA_ "GenSigSendType" SG_ 1411 ZV_Tankklappe_offen 0;
BA_ "GenSigSwitchedByIgnition" SG_ 1411 ZV_Tankklappe_offen 0;
BA_ "GenSigSendType" SG_ 1411 ZV_verriegeln_Anf 6;
BA_ "GenSigSwitchedByIgnition" SG_ 1411 ZV_verriegeln_Anf 0;
BA_ "GenSigSendType" SG_ 1411 ZV_verriegelt_extern_ist 3;
BA_ "GenSigSwitchedByIgnition" SG_ 1411 ZV_verriegelt_extern_ist 0;
BA_ "GenSigSendType" SG_ 1411 ZV_verriegelt_extern_soll 3;
BA_ "GenSigSwitchedByIgnition" SG_ 1411 ZV_verriegelt_extern_soll 0;
BA_ "GenSigSendType" SG_ 1411 ZV_verriegelt_intern_ist 3;
BA_ "GenSigSwitchedByIgnition" SG_ 1411 ZV_verriegelt_intern_ist 0;
BA_ "GenSigSendType" SG_ 1411 ZV_verriegelt_intern_soll 3;
BA_ "GenSigSwitchedByIgnition" SG_ 1411 ZV_verriegelt_intern_soll 0;
BA_ "GenSigSendType" SG_ 1411 ZV_verriegelt_soll 3;
BA_ "GenSigSwitchedByIgnition" SG_ 1411 ZV_verriegelt_soll 0;
BA_REL_ "GenSigTimeoutTime" BU_SG_REL_ Gateway_Max SG_ 181 WH_gespeicherte_Fahrstufe 500;
BA_REL_ "GenSigTimeoutTime" BU_SG_REL_ Gateway_Max SG_ 916 WBA_Fahrstufe_02 1600;
BA_REL_ "GenSigTimeoutTime" BU_SG_REL_ Getriebe_DQ SG_ 313 VMM_02_CRC 500;
BA_REL_ "GenSigTimeoutTime" BU_SG_REL_ Getriebe_DQ SG_ 313 VMM_02_BZ 500;
BA_REL_ "GenSigTimeoutTime" BU_SG_REL_ Getriebe_DQ SG_ 313 HMS_P_beibehalten_GE 500;
BA_REL_ "GenSigTimeoutTime" BU_SG_REL_ Getriebe_DQ SG_ 313 VZM_Unterdrueckung_Antriebsmom 500;
BA_REL_ "GenSigTimeoutTime" BU_SG_REL_ Getriebe_DQ SG_ 313 HMS_halten_nicht_verfuegbar 500;
BA_REL_ "GenSigTimeoutTime" BU_SG_REL_ Getriebe_DQ SG_ 313 HMS_parken_nicht_verfuegbar 500;
BA_REL_ "GenSigTimeoutTime" BU_SG_REL_ Getriebe_DQ SG_ 313 HMS_Anforderung_GE 500;
BA_REL_ "GenSigTimeoutTime" BU_SG_REL_ Getriebe_DQ SG_ 313 HMS_Systemstatus 500;
BA_REL_ "GenSigTimeoutTime" BU_SG_REL_ Getriebe_DQ SG_ 313 HMS_Stillstand 500;
BA_REL_ "GenSigTimeoutTime" BU_SG_REL_ Getriebe_DQ SG_ 313 HMS_aktives_System 500;
BA_REL_ "GenSigTimeoutTime" BU_SG_REL_ Getriebe_DQ SG_ 313 HMS_Fehlerstatus 500;
BA_REL_ "GenSigTimeoutTime" BU_SG_REL_ Getriebe_DQ SG_ 181 Waehlhebel_04_CRC 500;
BA_REL_ "GenSigTimeoutTime" BU_SG_REL_ Getriebe_DQ SG_ 181 Waehlhebel_04_BZ 500;
BA_REL_ "GenSigTimeoutTime" BU_SG_REL_ Getriebe_DQ SG_ 181 WH_gespeicherte_Fahrstufe 500;
BA_REL_ "GenSigTimeoutTime" BU_SG_REL_ Getriebe_DQ SG_ 181 WH_Variante 500;
BA_REL_ "GenSigTimeoutTime" BU_SG_REL_ Getriebe_DQ SG_ 181 WH_Entsperrtaste_02 500;
BA_REL_ "GenSigTimeoutTime" BU_SG_REL_ Getriebe_DQ SG_ 181 WH_P_Taste 500;
BA_REL_ "GenSigTimeoutTime" BU_SG_REL_ Getriebe_DQ SG_ 181 WH_Fahrstufe 500;
BA_REL_ "GenSigTimeoutTime" BU_SG_REL_ Getriebe_DQ SG_ 2463978687 WH_Fehler_CRC_SBM 5000;
BA_REL_ "GenSigTimeoutTime" BU_SG_REL_ Getriebe_DQ SG_ 2463978687 WH_Fehler_CRC_SBM_Status 5000;
BA_REL_ "GenSigTimeoutTime" BU_SG_REL_ Getriebe_DQ SG_ 2463978687 WH_Fehler_Timeout_SBM 5000;
BA_REL_ "GenSigTimeoutTime" BU_SG_REL_ Getriebe_DQ SG_ 2463978687 WH_Fehler_Timeout_SBM_Status 5000;
BA_REL_ "GenSigTimeoutTime" BU_SG_REL_ Getriebe_DQ SG_ 2463978687 WH_Fehler_Ueberspannung 5000;
BA_REL_ "GenSigTimeoutTime" BU_SG_REL_ Getriebe_DQ SG_ 2463978687 WH_Fehler_Ueberspannung_Status 5000;
BA_REL_ "GenSigTimeoutTime" BU_SG_REL_ Getriebe_DQ SG_ 2463978687 WH_Fehler_BZ_SBM 5000;
BA_REL_ "GenSigTimeoutTime" BU_SG_REL_ Getriebe_DQ SG_ 2463978687 WH_Fehler_BZ_SBM_Status 5000;
BA_REL_ "GenSigTimeoutTime" BU_SG_REL_ Getriebe_DQ SG_ 2463978687 WH_Fehler_Unterspannung 5000;
BA_REL_ "GenSigTimeoutTime" BU_SG_REL_ Getriebe_DQ SG_ 2463978687 WH_Fehler_Unterspannung_Status 5000;
BA_REL_ "GenSigTimeoutTime" BU_SG_REL_ Getriebe_DQ SG_ 2463978687 WH_Fehler_Ausleuchtung 5000;
BA_REL_ "GenSigTimeoutTime" BU_SG_REL_ Getriebe_DQ SG_ 2463978687 WH_Fehler_Ausleuchtung_Status 5000;
BA_REL_ "GenSigTimeoutTime" BU_SG_REL_ Getriebe_DQ SG_ 2463978687 WH_Fehler_Entsperrtaste 5000;
BA_REL_ "GenSigTimeoutTime" BU_SG_REL_ Getriebe_DQ SG_ 2463978687 WH_Fehler_Entsperrtaste_Status 5000;
BA_REL_ "GenSigTimeoutTime" BU_SG_REL_ Getriebe_DQ SG_ 2463978687 WH_Fehler_P_Taste 5000;
BA_REL_ "GenSigTimeoutTime" BU_SG_REL_ Getriebe_DQ SG_ 2463978687 WH_Fehler_P_Taste_Status 5000;
BA_REL_ "GenSigTimeoutTime" BU_SG_REL_ Getriebe_DQ SG_ 2463978687 WH_Fehler_Sensor_einfach 5000;
BA_REL_ "GenSigTimeoutTime" BU_SG_REL_ Getriebe_DQ SG_ 2463978687 WH_Fehler_Sensor_einfach_Status 5000;
BA_REL_ "GenSigTimeoutTime" BU_SG_REL_ Getriebe_DQ SG_ 2463978687 WH_Fehler_Sensor_mehrfach 5000;
BA_REL_ "GenSigTimeoutTime" BU_SG_REL_ Getriebe_DQ SG_ 2463978687 WH_Fehler_Sensor_mehrfach_Status 5000;
BA_REL_ "GenSigTimeoutTime" BU_SG_REL_ Getriebe_DQ SG_ 2463978687 WH_Fehler_Shiftlock 5000;
BA_REL_ "GenSigTimeoutTime" BU_SG_REL_ Getriebe_DQ SG_ 2463978687 WH_Fehler_Shiftlock_Status 5000;
BA_REL_ "GenSigTimeoutTime" BU_SG_REL_ Getriebe_DQ SG_ 388 ZV_entriegeln_Anf 5000;
BA_REL_ "GenSigTimeoutTime" BU_SG_REL_ Getriebe_DQ SG_ 1411 ZV_FT_offen 2000;
BA_REL_ "GenSigTimeoutTime" BU_SG_REL_ Motor_konv SG_ 313 VMM_02_CRC 500;
BA_REL_ "GenSigTimeoutTime" BU_SG_REL_ Motor_konv SG_ 313 VMM_02_BZ 500;
BA_REL_ "GenSigTimeoutTime" BU_SG_REL_ Motor_konv SG_ 313 VZM_aktiver_Basisservice 500;
BA_REL_ "GenSigTimeoutTime" BU_SG_REL_ Motor_konv SG_ 313 VZM_Fahrer_bremst 500;
BA_REL_ "GenSigTimeoutTime" BU_SG_REL_ Motor_konv SG_ 313 VZM_QBit_Fahrer_bremst 500;
BA_REL_ "GenSigTimeoutTime" BU_SG_REL_ Motor_konv SG_ 313 VMM_Notstopp_Status 500;
BA_REL_ "GenSigTimeoutTime" BU_SG_REL_ Motor_konv SG_ 313 VMM_Bremslicht_defekt 500;
BA_REL_ "GenSigTimeoutTime" BU_SG_REL_ Motor_konv SG_ 313 VZM_TSK_SRBM_Anf 500;
BA_REL_ "GenSigTimeoutTime" BU_SG_REL_ Motor_konv SG_ 313 VZM_TSK_SRBM_nicht_verfuegbar 500;
BA_REL_ "GenSigTimeoutTime" BU_SG_REL_ Motor_konv SG_ 313 VZM_Verz_Reg_aktiv 500;
BA_REL_ "GenSigTimeoutTime" BU_SG_REL_ Motor_konv SG_ 313 VZM_Verz_Reg_nicht_verfuegbar 500;
BA_REL_ "GenSigTimeoutTime" BU_SG_REL_ Motor_konv SG_ 313 VMM_Bremslicht_unplausibel 500;
BA_REL_ "GenSigTimeoutTime" BU_SG_REL_ Motor_konv SG_ 313 VMM_Inkonsistenz_TSK 500;
BA_REL_ "GenSigTimeoutTime" BU_SG_REL_ Motor_konv SG_ 313 VMM_Inkonsistenz_MO 500;
BA_REL_ "GenSigTimeoutTime" BU_SG_REL_ Motor_konv SG_ 313 VMM_Fahrer_Bremskraft_bestimmend 500;
BA_REL_ "GenSigTimeoutTime" BU_SG_REL_ Motor_konv SG_ 313 VZM_Status_Wegregelung 500;
BA_REL_ "GenSigTimeoutTime" BU_SG_REL_ Motor_konv SG_ 313 VZM_Verz_ASIL_Verfuegbarkeit 500;
BA_REL_ "GenSigTimeoutTime" BU_SG_REL_ Motor_konv SG_ 313 VZM_aktives_System 500;
BA_REL_ "GenSigTimeoutTime" BU_SG_REL_ Motor_konv SG_ 313 VZM_Verz_Begrenzung 500;
BA_REL_ "GenSigTimeoutTime" BU_SG_REL_ Motor_konv SG_ 313 VZM_Systemstatus 500;
BA_REL_ "GenSigTimeoutTime" BU_SG_REL_ Motor_konv SG_ 313 VZM_SRBM_Ist 500;
BA_REL_ "GenSigTimeoutTime" BU_SG_REL_ Motor_konv SG_ 313 VZM_SRBM_max_Gradient 500;
BA_REL_ "GenSigTimeoutTime" BU_SG_REL_ Motor_konv SG_ 313 VZM_Unterdrueckung_Antriebsmom 500;
BA_REL_ "GenSigTimeoutTime" BU_SG_REL_ Motor_konv SG_ 313 HMS_Systemstatus 500;
BA_REL_ "GenSigTimeoutTime" BU_SG_REL_ Motor_konv SG_ 313 HMS_Stillstand 500;
BA_REL_ "GenSigTimeoutTime" BU_SG_REL_ Motor_konv SG_ 313 HMS_aktives_System 500;
BA_REL_ "GenSigTimeoutTime" BU_SG_REL_ Motor_konv SG_ 313 HMS_Fehlerstatus 500;
BA_REL_ "GenSigTimeoutTime" BU_SG_REL_ Motor_konv SG_ 313 HMS_Index_Haltemoment 500;
BA_REL_ "GenSigTimeoutTime" BU_SG_REL_ Motor_konv SG_ 313 HMS_Haltemoment 500;
BA_REL_ "GenSigTimeoutTime" BU_SG_REL_ Motor_konv SG_ 2331595858 vREM_Status 500;
BA_REL_ "GenSigTimeoutTime" BU_SG_REL_ Motor_konv SG_ 2331595858 vREM_Abstand_P0 500;
BA_REL_ "GenSigTimeoutTime" BU_SG_REL_ Motor_konv SG_ 2331595858 vREM_Abstand_P1 500;
BA_REL_ "GenSigTimeoutTime" BU_SG_REL_ Motor_konv SG_ 2331595858 vREM_Abstand_P2 500;
BA_REL_ "GenSigTimeoutTime" BU_SG_REL_ Motor_konv SG_ 2331595858 vREM_Abstand_P3 500;
BA_REL_ "GenSigTimeoutTime" BU_SG_REL_ Motor_konv SG_ 2331595858 vREM_Abstand_P4 500;
BA_REL_ "GenSigTimeoutTime" BU_SG_REL_ Motor_konv SG_ 2331595858 vREM_Abstand_P5 500;
BA_REL_ "GenSigTimeoutTime" BU_SG_REL_ Motor_konv SG_ 2331595858 vREM_Abstand_P6 500;
BA_REL_ "GenSigTimeoutTime" BU_SG_REL_ Motor_konv SG_ 2331595858 vREM_Abstand_P7 500;
BA_REL_ "GenSigTimeoutTime" BU_SG_REL_ Motor_konv SG_ 2331595858 vREM_Abstand_P8 500;
BA_REL_ "GenSigTimeoutTime" BU_SG_REL_ Motor_konv SG_ 2331595858 vREM_Abstand_P9 500;
BA_REL_ "GenSigTimeoutTime" BU_SG_REL_ Motor_konv SG_ 2331595858 vREM_Abstand_P10 500;
BA_REL_ "GenSigTimeoutTime" BU_SG_REL_ Motor_konv SG_ 2331595858 vREM_Abstand_P11 500;
BA_REL_ "GenSigTimeoutTime" BU_SG_REL_ Motor_konv SG_ 2331595858 vREM_Abstand_P12 500;
BA_REL_ "GenSigTimeoutTime" BU_SG_REL_ Motor_konv SG_ 2331595858 vREM_Abstand_P13 500;
BA_REL_ "GenSigTimeoutTime" BU_SG_REL_ Motor_konv SG_ 2331595858 vREM_Abstand_P14 500;
BA_REL_ "GenSigTimeoutTime" BU_SG_REL_ Motor_konv SG_ 2331595858 vREM_Abstand_P15 500;
BA_REL_ "GenSigTimeoutTime" BU_SG_REL_ Motor_konv SG_ 2331595858 vREM_Abstand_P16 500;
BA_REL_ "GenSigTimeoutTime" BU_SG_REL_ Motor_konv SG_ 2331595858 vREM_Abstand_P17 500;
BA_REL_ "GenSigTimeoutTime" BU_SG_REL_ Motor_konv SG_ 2331595858 vREM_Abstand_P18 500;
BA_REL_ "GenSigTimeoutTime" BU_SG_REL_ Motor_konv SG_ 2331595858 vREM_Abstand_P19 500;
BA_REL_ "GenSigTimeoutTime" BU_SG_REL_ Motor_konv SG_ 2331595858 vREM_Abstand_P20 500;
BA_REL_ "GenSigTimeoutTime" BU_SG_REL_ Motor_konv SG_ 2331595858 vREM_Abstand_P21 500;
BA_REL_ "GenSigTimeoutTime" BU_SG_REL_ Motor_konv SG_ 2331595858 vREM_Abstand_P22 500;
BA_REL_ "GenSigTimeoutTime" BU_SG_REL_ Motor_konv SG_ 2331595858 vREM_Abstand_P23 500;
BA_REL_ "GenSigTimeoutTime" BU_SG_REL_ Motor_konv SG_ 2331595858 vREM_Abstand_P24 500;
BA_REL_ "GenSigTimeoutTime" BU_SG_REL_ Motor_konv SG_ 2331595858 vREM_Abstand_P25 500;
BA_REL_ "GenSigTimeoutTime" BU_SG_REL_ Motor_konv SG_ 2331595858 vREM_Abstand_P26 500;
BA_REL_ "GenSigTimeoutTime" BU_SG_REL_ Motor_konv SG_ 2331595858 vREM_Abstand_P27 500;
BA_REL_ "GenSigTimeoutTime" BU_SG_REL_ Motor_konv SG_ 2331595858 vREM_Abstand_P28 500;
BA_REL_ "GenSigTimeoutTime" BU_SG_REL_ Motor_konv SG_ 2331595858 vREM_Abstand_P29 500;
BA_REL_ "GenSigTimeoutTime" BU_SG_REL_ Motor_konv SG_ 2331595858 vREM_Akt_Zaehler 500;
BA_REL_ "GenSigTimeoutTime" BU_SG_REL_ Motor_konv SG_ 2331595859 vREM_Geschw_P0 500;
BA_REL_ "GenSigTimeoutTime" BU_SG_REL_ Motor_konv SG_ 2331595859 vREM_Geschw_P1 500;
BA_REL_ "GenSigTimeoutTime" BU_SG_REL_ Motor_konv SG_ 2331595859 vREM_Geschw_P2 500;
BA_REL_ "GenSigTimeoutTime" BU_SG_REL_ Motor_konv SG_ 2331595859 vREM_Geschw_P3 500;
BA_REL_ "GenSigTimeoutTime" BU_SG_REL_ Motor_konv SG_ 2331595859 vREM_Geschw_P4 500;
BA_REL_ "GenSigTimeoutTime" BU_SG_REL_ Motor_konv SG_ 2331595859 vREM_Geschw_P5 500;
BA_REL_ "GenSigTimeoutTime" BU_SG_REL_ Motor_konv SG_ 2331595859 vREM_Geschw_P6 500;
BA_REL_ "GenSigTimeoutTime" BU_SG_REL_ Motor_konv SG_ 2331595859 vREM_Geschw_P7 500;
BA_REL_ "GenSigTimeoutTime" BU_SG_REL_ Motor_konv SG_ 2331595859 vREM_Geschw_P8 500;
BA_REL_ "GenSigTimeoutTime" BU_SG_REL_ Motor_konv SG_ 2331595859 vREM_Geschw_P9 500;
BA_REL_ "GenSigTimeoutTime" BU_SG_REL_ Motor_konv SG_ 2331595859 vREM_Geschw_P10 500;
BA_REL_ "GenSigTimeoutTime" BU_SG_REL_ Motor_konv SG_ 2331595859 vREM_Geschw_P11 500;
BA_REL_ "GenSigTimeoutTime" BU_SG_REL_ Motor_konv SG_ 2331595859 vREM_Geschw_P12 500;
BA_REL_ "GenSigTimeoutTime" BU_SG_REL_ Motor_konv SG_ 2331595859 vREM_Geschw_P13 500;
BA_REL_ "GenSigTimeoutTime" BU_SG_REL_ Motor_konv SG_ 2331595859 vREM_Geschw_P14 500;
BA_REL_ "GenSigTimeoutTime" BU_SG_REL_ Motor_konv SG_ 2331595859 vREM_Geschw_P15 500;
BA_REL_ "GenSigTimeoutTime" BU_SG_REL_ Motor_konv SG_ 2331595859 vREM_Geschw_P16 500;
BA_REL_ "GenSigTimeoutTime" BU_SG_REL_ Motor_konv SG_ 2331595859 vREM_Geschw_P17 500;
BA_REL_ "GenSigTimeoutTime" BU_SG_REL_ Motor_konv SG_ 2331595859 vREM_Geschw_P18 500;
BA_REL_ "GenSigTimeoutTime" BU_SG_REL_ Motor_konv SG_ 2331595859 vREM_Geschw_P19 500;
BA_REL_ "GenSigTimeoutTime" BU_SG_REL_ Motor_konv SG_ 2331595859 vREM_Geschw_P20 500;
BA_REL_ "GenSigTimeoutTime" BU_SG_REL_ Motor_konv SG_ 2331595859 vREM_Geschw_P21 500;
BA_REL_ "GenSigTimeoutTime" BU_SG_REL_ Motor_konv SG_ 2331595859 vREM_Geschw_P22 500;
BA_REL_ "GenSigTimeoutTime" BU_SG_REL_ Motor_konv SG_ 2331595859 vREM_Geschw_P23 500;
BA_REL_ "GenSigTimeoutTime" BU_SG_REL_ Motor_konv SG_ 2331595859 vREM_Geschw_P24 500;
BA_REL_ "GenSigTimeoutTime" BU_SG_REL_ Motor_konv SG_ 2331595859 vREM_Geschw_P25 500;
BA_REL_ "GenSigTimeoutTime" BU_SG_REL_ Motor_konv SG_ 2331595859 vREM_Geschw_P26 500;
BA_REL_ "GenSigTimeoutTime" BU_SG_REL_ Motor_konv SG_ 2331595859 vREM_Geschw_P27 500;
BA_REL_ "GenSigTimeoutTime" BU_SG_REL_ Motor_konv SG_ 2331595859 vREM_Geschw_P28 500;
BA_REL_ "GenSigTimeoutTime" BU_SG_REL_ Motor_konv SG_ 2331595859 vREM_Geschw_P29 500;
BA_REL_ "GenSigTimeoutTime" BU_SG_REL_ Motor_konv SG_ 2463978663 VZE_Hinweistext 2000;
BA_REL_ "GenSigTimeoutTime" BU_SG_REL_ Motor_konv SG_ 2463978663 VZE_Verkehrszeichen_1 2000;
BA_REL_ "GenSigTimeoutTime" BU_SG_REL_ Motor_konv SG_ 2463978663 VZE_Zeichen_01_KameraWied 2000;
BA_REL_ "GenSigTimeoutTime" BU_SG_REL_ Motor_konv SG_ 2463978663 VZE_Zeichen_01_Kamera 2000;
BA_REL_ "GenSigTimeoutTime" BU_SG_REL_ Motor_konv SG_ 2463978663 VZE_Verkehrszeichen_4 2000;
BA_REL_ "GenSigTimeoutTime" BU_SG_REL_ Motor_konv SG_ 2463978663 VZE_Verkehrszeichen_5 2000;
BA_REL_ "GenSigTimeoutTime" BU_SG_REL_ Motor_konv SG_ 2463978663 VZE_Anhaenger_Vmax 2000;
BA_REL_ "GenSigTimeoutTime" BU_SG_REL_ Motor_konv SG_ 2463978663 VZE_Zeichen_05_Entfernung 2000;
BA_REL_ "GenSigTimeoutTime" BU_SG_REL_ Motor_konv SG_ 2463978663 VZE_Zeichen_05_Entfernung_StdA 2000;
BA_REL_ "GenSigTimeoutTime" BU_SG_REL_ Motor_konv SG_ 2463978663 VZE_Verkehrszeichen_6 2000;
BA_REL_ "GenSigTimeoutTime" BU_SG_REL_ Motor_konv SG_ 2463978663 VZE_Zeichen_06_Entfernung 2000;
BA_REL_ "GenSigTimeoutTime" BU_SG_REL_ Motor_konv SG_ 2463978663 VZE_Zeichen_06_Entfernung_StdA 2000;
BA_REL_ "GenSigTimeoutTime" BU_SG_REL_ Motor_konv SG_ 2463978663 VZE_Umweltinfo_Naesse 2000;
BA_REL_ "GenSigTimeoutTime" BU_SG_REL_ Motor_konv SG_ 2463978663 VZE_Umweltinfo_Nebel 2000;
BA_REL_ "GenSigTimeoutTime" BU_SG_REL_ Motor_konv SG_ 2463978663 VZE_Umweltinfo_Anhaengerbetrieb 2000;
BA_REL_ "GenSigTimeoutTime" BU_SG_REL_ Motor_konv SG_ 2463978663 VZE_FoD_Status 2000;
BA_REL_ "GenSigTimeoutTime" BU_SG_REL_ Motor_konv SG_ 916 WBA_Segeln_aktiv 1600;
BA_REL_ "GenSigTimeoutTime" BU_SG_REL_ Motor_konv SG_ 916 GE_Sollgang 1600;
BA_REL_ "GenSigTimeoutTime" BU_SG_REL_ Motor_konv SG_ 1361 WFS_ID_Geb_autorisiert_in_Kl15 2000;
BA_REL_ "GenSigTimeoutTime" BU_SG_REL_ Motor_konv SG_ 1361 WFS_Klemmenfreigabe 2000;
BA_REL_ "GenSigTimeoutTime" BU_SG_REL_ Motor_konv SG_ 1702 Wischer_vorne_aktiv 5000;
BA_REL_ "GenSigTimeoutTime" BU_SG_REL_ Motor_konv SG_ 1702 Waschen_vorne_aktiv 5000;
BA_REL_ "GenSigTimeoutTime" BU_SG_REL_ Motor_konv SG_ 1411 ZV_FT_offen 2000;
BA_REL_ "GenSigTimeoutTime" BU_SG_REL_ Motor_konv SG_ 1411 ZV_BT_offen 2000;
BA_REL_ "GenSigTimeoutTime" BU_SG_REL_ Motor_konv SG_ 1411 ZV_HFS_offen 2000;
BA_REL_ "GenSigTimeoutTime" BU_SG_REL_ Motor_konv SG_ 1411 ZV_HBFS_offen 2000;
BA_REL_ "GenSigTimeoutTime" BU_SG_REL_ Motor_konv SG_ 1411 ZV_HD_offen 2000;
VAL_ 313 VZM_aktiver_Basisservice 0 "Keine_Aktivitaet" 1 "Bremsenkonditionierung" 2 "Bremsruck" 3 "Verzoegerungsregelung" 4 "Wegregelung" ;
VAL_ 313 VZM_Anhalteweg_nicht_verfuegbar 0 "verfuegbar" 1 "nicht_verfuegbar" ;
VAL_ 313 VZM_Fahrer_bremst 0 "Bremsdruckschwelle_nicht_ueberschritten" 1 "Bremsdruckschwelle_ueberschritten" ;
VAL_ 313 VZM_QBit_Fahrer_bremst 0 "gueltiger_Wert" 1 "Ersatz_Init_oder_Fehlerwert" ;
VAL_ 313 VMM_MKB_codiert 0 "MKB_nicht_codiert" 1 "MKB_codiert" ;
VAL_ 313 VMM_Inkonsistenz_EBKV 0 "konsistent" 1 "nicht_konsistent" ;
VAL_ 313 VMM_Notstopp_Status 0 "Init" 1 "verfuegbar" 2 "warten_auf_sekundaer_System" 3 "passiv_Ueberwachung" 4 "aktiv_ausgeloest" 7 "Fehler" ;
VAL_ 313 VZM_Warnruck_nicht_verfuegbar 0 "verfuegbar" 1 "nicht_verfuegbar" ;
VAL_ 313 VZM_Warnruckeln_nicht_verfuegbar 0 "verfuegbar" 1 "nicht_verfuegbar" ;
VAL_ 313 VZM_Bkd_nicht_verfuegbar 0 "verfuegbar" 1 "nicht_verfuegbar" ;
VAL_ 313 VMM_Bremslicht_defekt 0 "Bremslichter_nicht_defekt" 1 "Bremslichter_defekt" ;
VAL_ 313 VZM_Fahrer_bremst_deutlich 0 "Fahrer_bremst_nicht_deutlich" 1 "Fahrer_bremst_deutlich" ;
VAL_ 313 VZM_TSK_SRBM_Anf 0 "keine_Aktivitaet" 1 "Aktivitaet_durch_TSK" ;
VAL_ 313 VZM_TSK_SRBM_nicht_verfuegbar 0 "verfuegbar" 1 "nicht_verfuegbar" ;
VAL_ 313 VZM_Verz_Reg_aktiv 0 "keine_Aktivitaet" 2 "Aktivitaet_durch_AWV_PCF" 3 "Aktivitaet_durch_EA" 4 "Aktivitaet_durch_TSK" 5 "Aktivitaet_durch_RCTA" 6 "Aktivitaet_durch_ParkAssist" 7 "Aktivitaet_durch_ACC" 8 "Aktivitaet_durch_ARA" 9 "Aktivitaet_durch_NV" 10 "Aktivitaet_durch_KAS" 11 "Aktivitaet_durch_FAS_VK" 12 "Aktivitaet_durch_vESC" 13 "Aktivitaet_durch_KAM" 14 "Aktivitaet_durch_BRS_intern" 15 "Aktivitaet_durch_AEB" 16 "Aktivitaet_durch_MKB" ;
VAL_ 313 VZM_Verz_Reg_nicht_verfuegbar 0 "verfuegbar" 1 "nicht_verfuegbar" ;
VAL_ 313 VMM_Inkonsistenz_KAS 0 "konsistent" 1 "nicht_konsistent" ;
VAL_ 313 VMM_Bremslicht_unplausibel 0 "plausibel" 1 "unplausibel" ;
VAL_ 313 VMM_Inkonsistenz_ACC 0 "konsistent" 1 "nicht_konsistent" ;
VAL_ 313 VMM_Inkonsistenz_AWV_PCF 0 "konsistent" 1 "nicht_konsistent" ;
VAL_ 313 VMM_Inkonsistenz_ARA 0 "konsistent" 1 "nicht_konsistent" ;
VAL_ 313 VMM_Inkonsistenz_ParkAssist 0 "konsistent" 1 "nicht_konsistent" ;
VAL_ 313 VMM_Inkonsistenz_FAS_VK 0 "konsistent" 1 "nicht_konsistent" ;
VAL_ 313 VMM_Inkonsistenz_NV 0 "konsistent" 1 "nicht_konsistent" ;
VAL_ 313 VMM_Inkonsistenz_RCTA 0 "konsistent" 1 "nicht_konsistent" ;
VAL_ 313 VMM_Inkonsistenz_TSK 0 "konsistent" 1 "nicht_konsistent" ;
VAL_ 313 VMM_Inkonsistenz_MO 0 "konsistent" 1 "nicht_konsistent" ;
VAL_ 313 VMM_Inkonsistenz_AEB 0 "konsistent" 1 "nicht_konsistent" ;
VAL_ 313 VMM_Fahrer_Bremskraft_bestimmend 0 "Nicht_Bremskraft_bestimmend" 1 "Bremskraft_bestimmend" ;
VAL_ 313 VMM_Inkonsistenz_EA 0 "konsistent" 1 "nicht_konsistent" ;
VAL_ 313 VZM_Status_Wegregelung 0 "Inaktiv" 1 "Passiv" 2 "Aktiv" 3 "Passiv_Ueberwachend" ;
VAL_ 313 VZM_Verz_ASIL_Verfuegbarkeit 0 "Nicht_verfuegbar" 1 "Verfuegbar_ab_ASIL_QM" 2 "Verfuegbar_ab_ASIL_A" 3 "Verfuegbar_ab_ASIL_B" 4 "Verfuegbar_ab_ASIL_C" ;
VAL_ 313 VZM_aktives_System 0 "Kein_aktiver_Teilnehmer" 1 "VZM_intern" 2 "AWV_PCF" 3 "EA" 4 "TSK" 5 "RCTA" 6 "ParkAssist" 7 "ACC" 8 "ARA" 9 "NV" 10 "KAS" 11 "FAS_VK" 12 "vESC" 13 "KAM" 14 "reserviert" 15 "AEB" 16 "MKB" 17 "ECD" 18 "RHP" ;
VAL_ 313 VZM_Verz_Begrenzung 0 "keine_Begrenzung" 1 "Begrenzung_aktiv" ;
VAL_ 313 VZM_Systemstatus 0 "Initialisierung" 1 "Verfuegbar" 2 "Verfuegbar_eingeschr_Performance" 3 "Nicht_Verfuegbar" 4 "Fehler" 5 "Sonderbetriebsmodus" ;
VAL_ 313 VZM_SRBM_Soll 4094 "Init" 4095 "Fehler" ;
VAL_ 313 VZM_SRBM_Ist 4094 "Init" 4095 "Fehler" ;
VAL_ 313 VZM_SRBM_max_Gradient 126 "Init" 127 "Fehler" ;
VAL_ 313 VMM_Inkonsistenz_KAM 0 "konsistent" 1 "nicht_konsistent" ;
VAL_ 313 VMM_Inkonsistenz_RHP 0 "konsistent" 1 "nicht_konsistent" ;
VAL_ 313 HMS_P_beibehalten_GE 0 "P_nicht_beibehalten" 1 "P_beibehalten" 2 "Init" 3 "Fehler" ;
VAL_ 313 VZM_Unterdrueckung_Antriebsmom 0 "Pos_Antriebsmoment_moeglich" 1 "Pos_Antriebsmoment_unterdruecken" ;
VAL_ 313 VMM_Inkonsistenz_VLK 0 "konsistent" 1 "nicht_konsistent" ;
VAL_ 313 HMS_halten_nicht_verfuegbar_02 0 "verfuegbar" 1 "nicht_verfuegbar" 2 "verfuegbar_ohne_Anwesenheitserk" 3 "reserviert" ;
VAL_ 313 HMS_halten_nicht_verfuegbar 0 "verfuegbar" 1 "nicht_verfuegbar" ;
VAL_ 313 HMS_parken_nicht_verfuegbar 0 "verfuegbar" 1 "nicht_verfuegbar" ;
VAL_ 313 HMS_Anforderung_GE 0 "keine_Anforderung" 1 "P_einlegen" ;
VAL_ 313 HMS_Systemstatus 0 "keine_Funktion_aktiv" 1 "Halten_aktiv" 2 "Parken_angefordert" 3 "Parken_aktiv" 4 "Parken_beibehalten_aktiv" 5 "Anfahren_aktiv" 6 "Loeseanforderung_aktiv" 7 "Loeseanforderung_durch_Fahrer" 8 "Abrutschen_erkannt" 9 "Halten_Standby_aktiv" 10 "Anfahren_Standby_aktiv" 14 "Init" 15 "Fehler" ;
VAL_ 313 HMS_Stillstand 0 "kein_Stillstand" 1 "Stillstand_frueh" 2 "Stillstand" 6 "Init" 7 "Fehler" ;
VAL_ 313 HMS_aktives_System 0 "kein_System__Init_Fehler" 1 "Fahreranforderung_aktiv" 2 "HMS_intern_aktiv" 3 "ACC_aktiv" 4 "Autohold_aktiv" 5 "HHC_aktiv" 6 "HVLM_aktiv" 7 "Getriebe_aktiv" 8 "EBKV_aktiv" 9 "ParkAssist_aktiv" 10 "ARA_aktiv" 11 "HTO_aktiv" 12 "autonomous_Hold_aktiv" 13 "STA_aktiv" 14 "Motor_aktiv" 15 "EA_aktiv" 16 "VLK_aktiv" 17 "RHP_aktiv" 18 "ORU_aktiv" ;
VAL_ 313 VMM_Inkonsistenz_GE 0 "konsistent" 1 "nicht_konsistent" ;
VAL_ 313 VMM_Inkonsistenz_HVLM 0 "konsistent" 1 "nicht_konsistent" ;
VAL_ 313 HMS_Fehlerstatus 0 "kein_Fehler" 1 "Halten_nicht_moeglich" 2 "Sonderbetriebsmodus_aktiv" 3 "Systemeinschraenkung" 4 "Systemstoerung" ;
VAL_ 313 HMS_Index_Haltemoment 0 "Bremsmoment" 1 "Antriebsmoment" ;
VAL_ 313 HMS_Haltemoment 1022 "Init" 1023 "Fehler" ;
VAL_ 2331595858 vREM_Status 0 "Init" 1 "vREM_aktuell" 2 "DP_Wechsel" ;
VAL_ 2331595858 vREM_Abstand_P0 511 "kein_Abstand_vorhanden_Init" ;
VAL_ 2331595858 vREM_Abstand_P1 511 "kein_Abstand_vorhanden_Init" ;
VAL_ 2331595858 vREM_Abstand_P2 511 "kein_Abstand_vorhanden_Init" ;
VAL_ 2331595858 vREM_Abstand_P3 511 "kein_Abstand_vorhanden_Init" ;
VAL_ 2331595858 vREM_Abstand_P4 511 "kein_Abstand_vorhanden_Init" ;
VAL_ 2331595858 vREM_Abstand_P5 511 "kein_Abstand_vorhanden_Init" ;
VAL_ 2331595858 vREM_Abstand_P6 511 "kein_Abstand_vorhanden_Init" ;
VAL_ 2331595858 vREM_Abstand_P7 511 "kein_Abstand_vorhanden_Init" ;
VAL_ 2331595858 vREM_Abstand_P8 511 "kein_Abstand_vorhanden_Init" ;
VAL_ 2331595858 vREM_Abstand_P9 511 "kein_Abstand_vorhanden_Init" ;
VAL_ 2331595858 vREM_Abstand_P10 511 "kein_Abstand_vorhanden_Init" ;
VAL_ 2331595858 vREM_Abstand_P11 511 "kein_Abstand_vorhanden_Init" ;
VAL_ 2331595858 vREM_Abstand_P12 511 "kein_Abstand_vorhanden_Init" ;
VAL_ 2331595858 vREM_Abstand_P13 511 "kein_Abstand_vorhanden_Init" ;
VAL_ 2331595858 vREM_Abstand_P14 511 "kein_Abstand_vorhanden_Init" ;
VAL_ 2331595858 vREM_Abstand_P15 511 "kein_Abstand_vorhanden_Init" ;
VAL_ 2331595858 vREM_Abstand_P16 511 "kein_Abstand_vorhanden_Init" ;
VAL_ 2331595858 vREM_Abstand_P17 511 "kein_Abstand_vorhanden_Init" ;
VAL_ 2331595858 vREM_Abstand_P18 511 "kein_Abstand_vorhanden_Init" ;
VAL_ 2331595858 vREM_Abstand_P19 511 "kein_Abstand_vorhanden_Init" ;
VAL_ 2331595858 vREM_Abstand_P20 511 "kein_Abstand_vorhanden_Init" ;
VAL_ 2331595858 vREM_Abstand_P21 511 "kein_Abstand_vorhanden_Init" ;
VAL_ 2331595858 vREM_Abstand_P22 511 "kein_Abstand_vorhanden_Init" ;
VAL_ 2331595858 vREM_Abstand_P23 511 "kein_Abstand_vorhanden_Init" ;
VAL_ 2331595858 vREM_Abstand_P24 511 "kein_Abstand_vorhanden_Init" ;
VAL_ 2331595858 vREM_Abstand_P25 511 "kein_Abstand_vorhanden_Init" ;
VAL_ 2331595858 vREM_Abstand_P26 511 "kein_Abstand_vorhanden_Init" ;
VAL_ 2331595858 vREM_Abstand_P27 511 "kein_Abstand_vorhanden_Init" ;
VAL_ 2331595858 vREM_Abstand_P28 511 "kein_Abstand_vorhanden_Init" ;
VAL_ 2331595858 vREM_Abstand_P29 511 "kein_Abstand_vorhanden_Init" ;
VAL_ 2331595859 vREM_Geschw_P0 254 "keine_Geschw_vorhanden_Init" ;
VAL_ 2331595859 vREM_Geschw_P1 254 "keine_Geschw_vorhanden_Init" ;
VAL_ 2331595859 vREM_Geschw_P2 254 "keine_Geschw_vorhanden_Init" ;
VAL_ 2331595859 vREM_Geschw_P3 254 "keine_Geschw_vorhanden_Init" ;
VAL_ 2331595859 vREM_Geschw_P4 254 "keine_Geschw_vorhanden_Init" ;
VAL_ 2331595859 vREM_Geschw_P5 254 "keine_Geschw_vorhanden_Init" ;
VAL_ 2331595859 vREM_Geschw_P6 254 "keine_Geschw_vorhanden_Init" ;
VAL_ 2331595859 vREM_Geschw_P7 254 "keine_Geschw_vorhanden_Init" ;
VAL_ 2331595859 vREM_Geschw_P8 254 "keine_Geschw_vorhanden_Init" ;
VAL_ 2331595859 vREM_Geschw_P9 254 "keine_Geschw_vorhanden_Init" ;
VAL_ 2331595859 vREM_Geschw_P10 254 "keine_Geschw_vorhanden_Init" ;
VAL_ 2331595859 vREM_Geschw_P11 254 "keine_Geschw_vorhanden_Init" ;
VAL_ 2331595859 vREM_Geschw_P12 254 "keine_Geschw_vorhanden_Init" ;
VAL_ 2331595859 vREM_Geschw_P13 254 "keine_Geschw_vorhanden_Init" ;
VAL_ 2331595859 vREM_Geschw_P14 254 "keine_Geschw_vorhanden_Init" ;
VAL_ 2331595859 vREM_Geschw_P15 254 "keine_Geschw_vorhanden_Init" ;
VAL_ 2331595859 vREM_Geschw_P16 254 "keine_Geschw_vorhanden_Init" ;
VAL_ 2331595859 vREM_Geschw_P17 254 "keine_Geschw_vorhanden_Init" ;
VAL_ 2331595859 vREM_Geschw_P18 254 "keine_Geschw_vorhanden_Init" ;
VAL_ 2331595859 vREM_Geschw_P19 254 "keine_Geschw_vorhanden_Init" ;
VAL_ 2331595859 vREM_Geschw_P20 254 "keine_Geschw_vorhanden_Init" ;
VAL_ 2331595859 vREM_Geschw_P21 254 "keine_Geschw_vorhanden_Init" ;
VAL_ 2331595859 vREM_Geschw_P22 254 "keine_Geschw_vorhanden_Init" ;
VAL_ 2331595859 vREM_Geschw_P23 254 "keine_Geschw_vorhanden_Init" ;
VAL_ 2331595859 vREM_Geschw_P24 254 "keine_Geschw_vorhanden_Init" ;
VAL_ 2331595859 vREM_Geschw_P25 254 "keine_Geschw_vorhanden_Init" ;
VAL_ 2331595859 vREM_Geschw_P26 254 "keine_Geschw_vorhanden_Init" ;
VAL_ 2331595859 vREM_Geschw_P27 254 "keine_Geschw_vorhanden_Init" ;
VAL_ 2331595859 vREM_Geschw_P28 254 "keine_Geschw_vorhanden_Init" ;
VAL_ 2331595859 vREM_Geschw_P29 254 "keine_Geschw_vorhanden_Init" ;
VAL_ 2463978663 VZE_Anzeigemodus 0 "EU_RDW" 1 "USA" 2 "Canada" 3 "China" ;
VAL_ 2463978663 VZE_Hinweistext 0 "kein_Hinweistext" ;
VAL_ 2463978663 VZE_Akustik_Limitwechsel 0 "keine_akustische_Signalisierung" 1 "akustische_Signalisierung_an" ;
VAL_ 2463978663 VZE_Modus_OptischeWarnung 0 "konstant" 1 "blinkend" ;
VAL_ 2463978663 VZE_Verkehrszeichen_Einheit 0 "kmh" 1 "mph" ;
VAL_ 2463978663 VZE_Anzeigeunterdrueck_Zeichen_3 0 "anzeigerelevant" 1 "nicht_anzeigerelevant" ;
VAL_ 2463978663 VZE_Anzeigeunterdrueck_Zeichen_2 0 "anzeigerelevant" 1 "nicht_anzeigerelevant" ;
VAL_ 2463978663 VZE_Verkehrszeichen_1 0 "kein_Verkehrszeichen" ;
VAL_ 2463978663 VZE_Verkehrszeichen_2 0 "kein_Verkehrszeichen" ;
VAL_ 2463978663 VZE_Verkehrszeichen_3 0 "kein_Verkehrszeichen" ;
VAL_ 2463978663 VZE_Warnung_Verkehrszeichen_1 0 "keine_Warnung_Initialwert_Fehlerwert" 1 "Warnung" ;
VAL_ 2463978663 VZE_Warnung_Verkehrszeichen_2 0 "keine_Warnung_Initialwert_Fehlerwert" 1 "Warnung" ;
VAL_ 2463978663 VZE_Warnung_Verkehrszeichen_3 0 "keine_Warnung_Initialwert_Fehlerwert" 1 "Warnung" ;
VAL_ 2463978663 VZE_Zusatzschild_1 0 "keine_Zusatzschild_Initialwert_Fehlerwert" ;
VAL_ 2463978663 VZE_Zusatzschild_2 0 "keine_Zusatzschild_Initialwert_Fehlerwert" ;
VAL_ 2463978663 VZE_Zusatzschild_3 0 "keine_Zusatzschild_Initialwert_Fehlerwert" ;
VAL_ 2463978663 VZE_Anzeigeunterdrueck_Zeichen_1 0 "anzeigerelevant" 1 "nicht_anzeigerelevant" ;
VAL_ 2463978663 VZE_Zeichen_01_KameraWied 0 "inaktiv" 1 "aktiv" ;
VAL_ 2463978663 VZE_Zeichen_02_KameraWied 0 "inaktiv" 1 "aktiv" ;
VAL_ 2463978663 VZE_Zeichen_03_KameraWied 0 "inaktiv" 1 "aktiv" ;
VAL_ 2463978663 VZE_Zeichen_01_Kamera 0 "nicht_erkannt" 1 "erkannt" ;
VAL_ 2463978663 VZE_Zeichen_01_Karte 0 "inaktiv" 1 "aktiv" ;
VAL_ 2463978663 VZE_Zeichen_01_Gesetz 0 "nicht_erkannt" 1 "erkannt" ;
VAL_ 2463978663 VZE_Zeichen_02_Kamera 0 "nicht_erkannt" 1 "erkannt" ;
VAL_ 2463978663 VZE_Zeichen_02_Karte 0 "inaktiv" 1 "aktiv" ;
VAL_ 2463978663 VZE_Zeichen_02_Gesetz 0 "nicht_erkannt" 1 "erkannt" ;
VAL_ 2463978663 VZE_Zeichen_03_Kamera 0 "nicht_erkannt" 1 "erkannt" ;
VAL_ 2463978663 VZE_Zeichen_03_Karte 0 "inaktiv" 1 "aktiv" ;
VAL_ 2463978663 VZE_Zeichen_03_Gesetz 0 "nicht_erkannt" 1 "erkannt" ;
VAL_ 2463978663 VZE_Gong 0 "Gong_deaktiv" 1 "Gong_aktiv" ;
VAL_ 2463978663 VZE_Akustik_Limitwechsel_Status 0 "keine_akustische_Signalisierung" 1 "akustische_Signalisierung_an" ;
VAL_ 2463978663 VZE_SLWF_Status 0 "Init" 1 "aktiv" 2 "deaktiv" ;
VAL_ 2463978663 VZE_Anzeigeunterdrueck_Zeichen_5 0 "anzeigerelevant" 1 "nicht_anzeigerelevant" ;
VAL_ 2463978663 VZE_Zeichen_05_KameraWied 0 "inaktiv" 1 "aktiv" ;
VAL_ 2463978663 VZE_Zeichen_05_Kamera 0 "nicht_erkannt" 1 "erkannt" ;
VAL_ 2463978663 VZE_Verkehrszeichen_4 0 "kein_Verkehrszeichen" ;
VAL_ 2463978663 VZE_Verkehrszeichen_5 0 "kein_Verkehrszeichen" ;
VAL_ 2463978663 VZE_Anhaenger_Vmax 14 "Init" 15 "Fehler" ;
VAL_ 2463978663 VZE_Zeichen_04_Gesetz 0 "nicht_erkannt" 1 "erkannt" ;
VAL_ 2463978663 VZE_Zeichen_04_Kamera 0 "nicht_erkannt" 1 "erkannt" ;
VAL_ 2463978663 VZE_Zeichen_04_KameraWied 0 "inaktiv" 1 "aktiv" ;
VAL_ 2463978663 VZE_Zeichen_04_Karte 0 "inaktiv" 1 "aktiv" ;
VAL_ 2463978663 VZE_Warnung_Verkehrszeichen_4 0 "keine_Warnung_Initialwert_Fehlerwert" 1 "Warnung" ;
VAL_ 2463978663 VZE_Warnung_Verkehrszeichen_5 0 "keine_Warnung_Initialwert_Fehlerwert" 1 "Warnung" ;
VAL_ 2463978663 VZE_Zeichen_05_Gesetz 0 "nicht_erkannt" 1 "erkannt" ;
VAL_ 2463978663 VZE_Zusatzschild_4 0 "keine_Zusatzschild_Initialwert_Fehlerwert" ;
VAL_ 2463978663 VZE_Zusatzschild_5 0 "keine_Zusatzschild_Initialwert_Fehlerwert" ;
VAL_ 2463978663 VZE_Baustelle 0 "Keine_Baustelle" 1 "Baustelle_erkannt" ;
VAL_ 2463978663 VZE_Zeichen_05_Karte 0 "inaktiv" 1 "aktiv" ;
VAL_ 2463978663 VZE_Zeichen_05_Entfernung 0 "Init" ;
VAL_ 2463978663 VZE_Zeichen_05_Entfernung_StdA 0 "Init" ;
VAL_ 2463978663 VZE_Anzeigeunterdrueck_Zeichen_4 0 "anzeigerelevant" 1 "nicht_anzeigerelevant" ;
VAL_ 2463978663 VZE_Verkehrszeichen_6 0 "kein_Verkehrszeichen" ;
VAL_ 2463978663 VZE_Zusatzschild_6 0 "keine_Zusatzschild_Initialwert_Fehlerwert" ;
VAL_ 2463978663 VZE_Zeichen_06_Entfernung 0 "Init" ;
VAL_ 2463978663 VZE_Zeichen_06_Entfernung_StdA 0 "Init" ;
VAL_ 2463978663 VZE_Umweltinfo_Naesse 0 "inaktiv" 1 "aktiv" ;
VAL_ 2463978663 VZE_Umweltinfo_Nebel 0 "inaktiv" 1 "aktiv" ;
VAL_ 2463978663 VZE_Umweltinfo_Anhaengerbetrieb 0 "inaktiv" 1 "aktiv" ;
VAL_ 2463978663 VZE_Erweiterte_Information 0 "keine_Information" ;
VAL_ 2463978663 VZE_Tempowarnung_Status 0 "inaktiv" 1 "aktiv" ;
VAL_ 2463978663 VZE_Tempowarnung_Einheit 0 "kmh" 1 "mph" ;
VAL_ 2463978663 VZE_Tempowarnung_Offset 0 "Init" ;
VAL_ 2463978663 VZE_FoD_Status 0 "Init" 1 "Funktion_inaktiv" 2 "Funktion_aktiv" ;
VAL_ 2463978663 VZE_Anzeige_ZS_1 0 "Init" ;
VAL_ 2463978663 VZE_Anzeige_ZS_2 0 "Init" ;
VAL_ 2463978663 VZE_Anzeige_ZS_3 0 "Init" ;
VAL_ 2463978663 VZE_Hinweistext_03 0 "kein_Hinweistext" ;
VAL_ 2463978663 VZE_Land 0 "Init" ;
VAL_ 2463978663 VZE_Warnung_VZ_1 0 "keine_Warnung" 1 "Warnung" ;
VAL_ 2463978663 VZE_Warnung_VZ_2 0 "keine_Warnung" 1 "Warnung" ;
VAL_ 2463978663 VZE_Warnung_VZ_3 0 "keine_Warnung" 1 "Warnung" ;
VAL_ 2463978663 VZE_Anzeige_VZ_1 0 "kein_Verkehrszeichen" ;
VAL_ 2463978663 VZE_Anzeige_VZ_2 0 "kein_Verkehrszeichen" ;
VAL_ 2463978663 VZE_Anzeige_VZ_3 0 "kein_Verkehrszeichen" ;
VAL_ 181 WH_gespeicherte_Fahrstufe 0 "keine_Speicherung" 1 "P" 2 "R" 3 "N" 4 "D" 5 "S" 6 "Tipp_Gasse" ;
VAL_ 181 WH_Initialisierung 0 "keine Initphase" 1 "Initphase" ;
VAL_ 181 WH_SensorPos_roh 0 "Init" 1 "Pos_1" 2 "Pos_2" 3 "Pos_3" 4 "Pos_4" 5 "Pos_5" 6 "Pos_6" 7 "Pos_7" 8 "Pos_8" 9 "Pos_9" 10 "Pos_10" 11 "Pos_11" 12 "Pos_12" 13 "Pos_13" 14 "Pos_14" 15 "Fehler" ;
VAL_ 181 WH_SensorPos_roh_inv 0 "Fehler" 1 "Pos_14" 2 "Pos_13" 3 "Pos_12" 4 "Pos_11" 5 "Pos_10" 6 "Pos_9" 7 "Pos_8" 8 "Pos_7" 9 "Pos_6" 10 "Pos_5" 11 "Pos_4" 12 "Pos_3" 13 "Pos_2" 14 "Pos_1" 15 "Init" ;
VAL_ 181 WH_Test_Aktiv 0 "kein Testergebnis" 1 "Testergebnis" ;
VAL_ 181 WH_Ist_Haltemagnet 0 "Init__nicht_verbaut" 1 "haelt_nicht" 2 "haelt" 3 "Fehler" ;
VAL_ 181 WH_Variante 0 "Init" 1 "Rastierter_Waehlhebel" 2 "Tasten" 4 "Monostabil_2x2" 5 "Sport_Tasten" 6 "Monostabil_2x2_reduziert" 7 "Monostabil_2x2_Walzensegment" 8 "Monostabil_2x2_Lenkstock_DK3" ;
VAL_ 181 WH_Entsperrtaste_02 0 "Init_nicht_verbaut" 1 "nicht_betaetigt" 2 "betaetigt" 3 "Fehler" ;
VAL_ 181 WH_P_Taste 0 "Init" 1 "nicht_betaetigt" 2 "betaetigt" 3 "Fehler" ;
VAL_ 181 WH_Ende_N_Haltephase 0 "nicht_aktiv" 1 "aktiv" ;
VAL_ 181 WH_Fahrstufe 0 "Init" 4 "nicht_betaetigt" 5 "D" 6 "N" 7 "R" 8 "P" 9 "N_ohne_Spotausleuchtung" 10 "Tipp_Plus" 11 "Tipp_Minus" 12 "S" 14 "Tipp_Gasse" 15 "Fehler" ;
VAL_ 181 WH_Status_Shiftlock 0 "Init" 2 "WH_freigegeben" 3 "WH_gesperrt" 6 "Shiftlock_nicht_verbaut" 7 "Fehler" ;
VAL_ 181 WH_Zustand_N_Haltephase 0 "inaktiv" 1 "aktiv__Timer_laeuft" 2 "beendet__Timer_abgelaufen" 3 "beendet__P_Taste_betaetigt" ;
VAL_ 181 WH_Zustand_N_Haltephase_2 0 "inaktiv" 1 "aktiv_Timer_laeuft" 2 "beendet_Timer_abgelaufen" 3 "beendet_P_taste_betaetigt" 5 "aktiv_Hinweismeldung" ;
VAL_ 2589283476 WH_Warnung_02 0 "Keine_Anzeige" 1 "Waehlhebel_defekt_Weiterfahrt_moeglich" 2 "Waehlhebel_in_Automatgasse_zurueckstellen" 3 "P_Taste_defekt" 4 "Zeitueberschr_P_wird_eingelegt" 5 "Wegrollgefahr__P_nicht_moeglich" ;
VAL_ 2589283476 WH_Warnung_03 0 "keine_Anzeige" 1 "Fahrstufe_D_mit_rechtem_Paddle" 2 "Fahrstufe_D_ueber_MD_Button" ;
VAL_ 2589283476 WH_Verbau_Entsperrtaste 0 "keine_Entsperrtaste_verbaut" 1 "Entsperrtaste_verbaut" ;
VAL_ 2589283476 WH_Schaltschema_Orientierung 0 "R_N_D" 1 "D_N_R" ;
VAL_ 2589283476 WH_FSA_HMI_Meldungen_01 0 "keine_Anzeige" 1 "Aufwaermphase_akt__nur_P_oder_N" 2 "Parksperre_defekt__Weiterfahrt" 3 "Parksperre_defekt__Liegenbleiber" ;
VAL_ 2463978687 WH_Fehler_Haltemagnet 0 "Fehler_passiv" 1 "Fehler_aktiv" ;
VAL_ 2463978687 WH_Fehler_Haltemagnet_Status 0 "Test_nicht_durchgefuehrt" 1 "Test_durchgefuehrt" ;
VAL_ 2463978687 WH_Fehler_CRC_SBM 0 "Fehler_passiv" 1 "Fehler_aktiv" ;
VAL_ 2463978687 WH_Fehler_CRC_SBM_Status 0 "Test_nicht_durchgefuehrt" 1 "Test_durchgefuehrt" ;
VAL_ 2463978687 WH_Fehler_Timeout_SBM 0 "Fehler_passiv" 1 "Fehler_aktiv" ;
VAL_ 2463978687 WH_Fehler_Timeout_SBM_Status 0 "Test_nicht_durchgefuehrt" 1 "Test_durchgefuehrt" ;
VAL_ 2463978687 WH_Fehler_Ueberspannung 0 "Fehler_passiv" 1 "Fehler_aktiv" ;
VAL_ 2463978687 WH_Fehler_Ueberspannung_Status 0 "Test_nicht_durchgefuehrt" 1 "Test_durchgefuehrt" ;
VAL_ 2463978687 WH_Fehler_BZ_SBM 0 "Fehler_passiv" 1 "Fehler_aktiv" ;
VAL_ 2463978687 WH_Fehler_BZ_SBM_Status 0 "Test_nicht_durchgefuehrt" 1 "Test_durchgefuehrt" ;
VAL_ 2463978687 WH_Fehler_Unterspannung 0 "Fehler_passiv" 1 "Fehler_aktiv" ;
VAL_ 2463978687 WH_Fehler_Unterspannung_Status 0 "Test_nicht_durchgefuehrt" 1 "Test_durchgefuehrt" ;
VAL_ 2463978687 WH_Fehler_Ausleuchtung 0 "Fehler_passiv" 1 "Fehler_aktiv" ;
VAL_ 2463978687 WH_Fehler_Ausleuchtung_Status 0 "Test_nicht_durchgefuehrt" 1 "Test_durchgefuehrt" ;
VAL_ 2463978687 WH_Fehler_Entsperrtaste 0 "Fehler_passiv" 1 "Fehler_aktiv" ;
VAL_ 2463978687 WH_Fehler_Entsperrtaste_Status 0 "Test_nicht_durchgefuehrt" 1 "Test_durchgefuehrt" ;
VAL_ 2463978687 WH_Fehler_P_Taste 0 "Fehler_passiv" 1 "Fehler_aktiv" ;
VAL_ 2463978687 WH_Fehler_P_Taste_Status 0 "Test_nicht_durchgefuehrt" 1 "Test_durchgefuehrt" ;
VAL_ 2463978687 WH_Fehler_Sensor_einfach 0 "Fehler_passiv" 1 "Fehler_aktiv" ;
VAL_ 2463978687 WH_Fehler_Sensor_einfach_Status 0 "Test_nicht_durchgefuehrt" 1 "Test_durchgefuehrt" ;
VAL_ 2463978687 WH_Fehler_Sensor_mehrfach 0 "Fehler_passiv" 1 "Fehler_aktiv" ;
VAL_ 2463978687 WH_Fehler_Sensor_mehrfach_Status 0 "Test_nicht_durchgefuehrt" 1 "Test_durchgefuehrt" ;
VAL_ 2463978687 WH_Fehler_Shiftlock 0 "Fehler_passiv" 1 "Fehler_aktiv" ;
VAL_ 2463978687 WH_Fehler_Shiftlock_Status 0 "Test_nicht_durchgefuehrt" 1 "Test_durchgefuehrt" ;
VAL_ 916 WBA_Fahrstufe_02 0 "Zwischenstellung_keine_Position" 1 "Position_P" 2 "Position_R" 3 "Position_N" 4 "Position_D" 5 "Position_S" 6 "Position_M_Tippfunktion" 7 "Kurzzeit_M" 8 "Position_E" 9 "Position_MS" 10 "Position_S_Plus" 11 "Position_MS_Plus" 12 "Position_Offroad" 13 "Position_B" 14 "Position_M_Plus" ;
VAL_ 916 WBA_ZielFahrstufe 0 "keine_Gangempfehlung_kein_Gang_eingelegt" 1 "Pfeil_nach_S" 2 "Pfeil_nach_D" 3 "Pfeil_nach_M" 4 "Pfeil_nach_E" ;
VAL_ 916 WBA_GE_Warnung_02 0 "keine_Anzeige" 1 "Fehlereskalationsstufe_I" 2 "Fehlereskalationsstufe_II" 3 "Weiterfahrt_nur_eingeschraenkt_moeglich__Kein_R_Gang" 4 "Getriebefehler_Weiterfahrt_nur_in_D_moeglich__P_bei_Motor_aus" 5 "Wegrollgefahr__P_nicht_moeglich" 6 "Paddlenotbetrieb_Schema+Warnung" 7 "Paddlenotbetrieb_Schema" 8 "Geschwindigkeitsbegrenzung_Notlauf" 9 "Fehlereskalationsst_o_Einschr" 10 "Fehlereskalationsstufe_v_Limit" 11 "Parksperre_Infostufe" 12 "Parksperre_Warnstufe_I" 13 "Parksperre_Warnstufe_II" ;
VAL_ 916 WBA_eing_Gang_02 0 "keine_Ganganzeige" 1 "Gang_1" 2 "Gang_2" 3 "Gang_3" 4 "Gang_4" 5 "Gang_5" 6 "Gang_6" 7 "Gang_7" 8 "Gang_8" 9 "Gang_9" 10 "Funktion_Ganganzeigeunterdrueckung" 11 "Gang_10" ;
VAL_ 916 WBA_GE_Texte 0 "keine_Anzeige" 1 "zum_Einlegen_einer_Fahrstufe_Fussbremse_betaetigen__ShiftLock_Information" 2 "zum_Einlegen_von_R_N_D_Fussbremse_betaetigen_und_Motor_starten" 3 "Wegrollgefahr_bitte_P_einlegen" 4 "Achtung_Zeitueberschreitung_P_wird_eingelegt" 5 "Wiederanmeldeprozedur_Bremse_betaetigen" 6 "P_nur_im_Stillstand_moeglich" 7 "Rennstart_aktiv" ;
VAL_ 916 WBA_Segeln_aktiv 0 "inaktiv" 1 "aktiv" ;
VAL_ 916 WBA_Schaltschema_02 0 "kein_Schaltschema" 1 "R_N_DS" 2 "R_N_ES" 3 "R_N_DB" 4 "R_N_D" 5 "R_N_SSplus" ;
VAL_ 916 WBA_Schaltschema_FS_inaktiv 0 "alle_Fahrstufen_aktiv" 1 "Fahrstufe_Rueckwaerts_inaktiv" 2 "nur_P_und_N_aktiv" 3 "alle_Fahrstufen_inaktiv" ;
VAL_ 916 WBA_GE_Zusatzwarnungen 0 "keine_Anzeige" 1 "Getriebeueberhitzung_Warnstufe_I" 2 "Getriebeueberhitzung_Warnstufe_II" 3 "Getriebefehler_Bitte_anhalten_und_P_einlegen" ;
VAL_ 916 GE_Sollgang 0 "keine_Empfehlung" 1 "Gang_1" 2 "Gang_2" 3 "Gang_3" 4 "Gang_4" 5 "Gang_5" 6 "Gang_6" 7 "Gang_7" 8 "Gang_8" 9 "Gang_9" 11 "Gang_10" ;
VAL_ 916 GE_Tipschaltempf_verfuegbar 0 "nicht_verfuegbar" 1 "verfuegbar" ;
VAL_ 916 WBA_GE_Texte_02 0 "Keine_Anzeige" 1 "Fahrtrichtungswechsel_nur_nach_Stillstandt" 2 "Ladestecker_gesteckt" 3 "zusaetzlicher_Service_erforderlich" 4 "eLaunch_Aktiv" 5 "eLaunch_nicht_moeglich" 6 "WH_S_nicht_moeglich_Offroad" 7 "WH_S_nicht_moeglich_RangeMode" ;
VAL_ 916 WBA_Schaltschema_Tippgasse 0 "keine_Tippgasse_vorhanden" 1 "Tippgasse_vorhanden" ;
VAL_ 916 WBA_Schaltschema_Fahreraktion 0 "keine_Fahreraktion" 1 "Fahreraktion" ;
VAL_ 916 WBA_Schaltschema_FS_vorwaerts 0 "FS1_aktiv__FS2_moeglich" 1 "FS2_aktiv__FS1_moeglich" 2 "FS1_aktiv__FS2_nicht_moeglich" 3 "FS2_aktiv__FS1_nicht_moeglich" ;
VAL_ 916 WBA_Shiftlock_Lampe 0 "Shiftlock_Lampe_AUS" 1 "Shiftlock_Lampe_EIN" ;
VAL_ 916 WBA_Anforderung_Akustik 0 "Akustik_aus" 1 "Akustik_ein" ;
VAL_ 916 WBA_Blinken 0 "kein_WBA_Blinken" 1 "WBA_Blinken" ;
VAL_ 916 GE_Wiederstart_Anz_Std 0 "keine_Anzeige" 1 "Standard_Wiederstartgrund" ;
VAL_ 916 GE_Stoppverbot_Anz_01 0 "keine_Anzeige" 1 "Temperaturbedingung" ;
VAL_ 916 GE_Stoppverbot_Anz_02 0 "keine_Anzeige" 1 "Drucksensorausfall" ;
VAL_ 916 GE_Stoppverbot_Anz_03 0 "keine_Anzeige" 1 "Grundeinstellung" ;
VAL_ 916 GE_Stoppverbot_Anz_04 0 "keine_Anzeige" 1 "Demontagestellung" ;
VAL_ 916 GE_Stoppverbot_Anz_05 0 "keine_Anzeige" 1 "Eingeschraenkte_Fahrfunktion_Notlauf_Liegenbleiber" ;
VAL_ 916 GE_Stoppverbot_Anz_06 0 "keine_Anzeige" 1 "Stoppverbot_ueber_Applikation" ;
VAL_ 916 GE_Stoppverbot_Anz_07 0 "keine_Anzeige" 1 "Schaltung_aktiv" ;
VAL_ 916 GE_Stoppverbot_Anz_Std 0 "keine_Anzeige" 1 "Standard_Stoppvetogrund" ;
VAL_ 1361 WFS_Schluessel_Fahrberecht 0 "kein authorisierter Schluessel erkannt" 1 "aktive_Funkschluessel_Nr_01" 2 "aktive_Funkschluessel_Nr_02" 3 "aktive_Funkschluessel_Nr_03" 4 "aktive_Funkschluessel_Nr_04" 5 "aktive_Funkschluessel_Nr_05" 6 "aktive_Funkschluessel_Nr_06" 7 "aktive_Funkschluessel_Nr_07" 8 "aktive_Funkschluessel_Nr_08" 9 "ungueltig_09" 10 "ungueltig_10" 11 "ungueltig_11" 12 "ungueltig_12" 13 "ungueltig_13" 14 "ungueltig_14" 15 "digitaler_Schluessel_aktiv" ;
VAL_ 1361 WFS_Verbauinfo_ELV 0 "ELV_nicht_verbaut" 1 "ELV_verbaut" ;
VAL_ 1361 WFS_ID_Geb_autorisiert 0 "Schluessel_nicht_authorisiert" 1 "Schluessel_authorisiert" ;
VAL_ 1361 WFS_ID_Geb_autorisiert_in_Kl15 0 "nicht_authorisiert_in_Kl15" 1 "authorisiert_in_Kl15" ;
VAL_ 1361 WFS_ID_Geb_steckt 0 "kein_Schluessel_im_Zuendschloss" 1 " Schluessel steckt im Zuendschloss" ;
VAL_ 1361 WFS_Safe 0 "Init" 1 "WFS nicht deaktiviert" ;
VAL_ 1361 WFS_LZ 0 "nicht def." 1 "LZ 1" 2 "LZ 2" 3 "LZ 3" ;
VAL_ 1361 WFS_ELV_authorisiert 0 "ELV_nicht_authorisiert" 1 "ELV_authorisiert" ;
VAL_ 1361 WFS_LF_Aktiv 0 "Funktempfang_nicht_aktiv" 1 "LF_Funkempfang_aktiv" ;
VAL_ 1361 WFS_Betrieb_Lesespule 0 "keine_Schluesselkomm_Lesespule" 1 "Schluesselkomm_Lesespule" ;
VAL_ 1361 WFS_Klemmenfreigabe 0 "keine_Freigabe" 1 "Freigabe" ;
VAL_ 1361 WFS_Fahrerhinweise 0 "Keine_Anzeigeanforderung" 1 "Schuessel_Auth_niO" 2 "Notlauf_aktiv" 3 "Schluessel_Kessy_nicht_gefunden" ;
VAL_ 1361 WFS_Parken_Status 0 "Limitierung_inaktiv" 1 "Limitierung_aktiv" 2 "Abbruch" ;
VAL_ 1702 Wischer_vorne_aktiv 0 "Init" 1 "Wischer_vorne_laeuft" ;
VAL_ 1702 Waschen_vorne_aktiv 0 "inaktiv" 1 "Waschen_aktiv" ;
VAL_ 1702 Wischer_vorne_Normal 1 "Wischer Front normal aktiv" ;
VAL_ 1702 Wischer_vorne_Schnell 1 "Wischer vorne schnell aktiv" ;
VAL_ 1702 Wischer_vorne_Parklage 0 "Wischer_Front_nicht_in_Parklage" 1 "Wischer_Front_in_Parklage__Initialzustand" ;
VAL_ 1702 WWSs_01_alt 0 "aktuell" 1 "veraltet" ;
VAL_ 1702 Wischer_vorne_defekt 0 "Init" 1 "Wischer vorne defekt" ;
VAL_ 1702 Wischer_vorne_blockiert 1 "Wischer vorne blockiert" ;
VAL_ 1702 Wischer1_Wischgeschwindigkeit 0 "0 U/min" 62 "Init" 63 "Fehler" ;
VAL_ 1702 BCM1_SRA_aktiv 0 "nicht aktiv" 1 "aktiv" ;
VAL_ 1702 Heckwischer_Anforderung 0 "Aus" 1 "Ein" ;
VAL_ 1702 Wischer_Anzeigetext 0 "keine_Anzeige" 1 "Hinweis_Service_Position" 2 "void" 3 "void" ;
VAL_ 1702 Wischer_WH_Typ 0 "Lenkstockschalter_0_Int_Stufen" 1 "Lenkstockschalter_2_Int_Stufen" 2 "Lenkstockschalter_4_Int_Stufen" ;
VAL_ 1702 Wischer_WH_PopUp_Anf 0 "keine_Anzeige" 1 "Intervallstufe_1_aktiv" 2 "Intervallstufe_2_aktiv" 3 "Intervallstufe_3_aktiv" 4 "Intervallstufe_4_aktiv" 5 "Regensensorstufe_1_aktiv" 6 "Regensensorstufe_2_aktiv" 7 "Regensensorstufe_3_aktiv" 8 "Regensensorstufe_4_aktiv" 9 "Wischerstufe_1_aktiv" 10 "Wischerstufe_2_aktiv" 11 "Tippwischen_aktiv" 12 "Heckwischen_aktiv" ;
VAL_ 1602 WIV_Verschleissindex 65535 "Fehler" ;
VAL_ 1602 WIV_Russindex 65535 "Fehler" ;
VAL_ 388 ZV_FT_verriegeln 0 "FT_nicht_verriegeln" 1 "FT_verriegeln" ;
VAL_ 388 ZV_FT_entriegeln 0 "FT_nicht_entriegeln" 1 "FT_entriegeln" ;
VAL_ 388 ZV_BT_verriegeln 0 "BT_nicht_verriegeln" 1 "BT_verriegeln" ;
VAL_ 388 ZV_BT_entriegeln 0 "BT_nicht_entriegeln" 1 "BT_ist_zu_entriegeln" ;
VAL_ 388 ZV_HFS_verriegeln 0 "inaktiv" 1 "aktiv" ;
VAL_ 388 ZV_HFS_entriegeln 0 "inaktiv" 1 "aktiv" ;
VAL_ 388 ZV_HBFS_verriegeln 0 "inaktiv" 1 "aktiv" ;
VAL_ 388 ZV_HBFS_entriegeln 0 "inaktiv" 1 "aktiv" ;
VAL_ 388 ZV_zentral_safen 0 "nicht_safen" 1 "Befehl_zentral_safen" ;
VAL_ 388 ZV_zentral_entsafen 0 "Init" 1 "Befehl_zentral_entsafen" ;
VAL_ 388 ZV_Spg_Anklappen 0 "inaktiv" 1 "aktiv" ;
VAL_ 388 ZV_Softtouch_betaetigt 0 "Softtouch_nicht_betaetigt" 1 "Softtouch_betaetigt" ;
VAL_ 388 ZV_LED_Steuerung 0 "LED_aus" 1 "LED_ein" ;
VAL_ 388 ZV_LED_Uebernahme 0 "Init" 1 "TSG_uebernimmt_LED_Steuerung" ;
VAL_ 388 ZV_auf_FT 0 "nicht_betaetigt" 1 "betaetigt" ;
VAL_ 388 ZV_zu_FT 0 "nicht_betaetigt" 1 "betaetigt" ;
VAL_ 388 ZV_auf_BT 0 "nicht_betaetigt" 1 "betaetigt" ;
VAL_ 388 ZV_zu_BT 0 "nicht_betaetigt" 1 "betaetigt" ;
VAL_ 388 ZV_auf_Funk 0 "nicht_betaetigt" 1 "betaetigt" ;
VAL_ 388 ZV_zu_Funk 0 "nicht_betaetigt" 1 "betaetigt" ;
VAL_ 388 VIP_Sensor_betaetigt 0 "Heckentr_VIP_nicht_angefordert" 1 "Heckentr_VIP_angefordert" ;
VAL_ 388 VIP_Freigabe 0 "keine_Freigabe" 1 "Freigabe" ;
VAL_ 388 ZV_zu_Zeitl_Nachverr 0 "Init" 1 "Nachverriegeln" ;
VAL_ 388 ZV_HSK_entriegeln 0 "Handschuhkasten nicht entriegeln" 1 "Handschuhkasten entriegeln" ;
VAL_ 388 ZV_HSK_verriegeln 0 "Handschuhkasten nicht verriegeln" 1 "Handschuhkasten_verriegelt" ;
VAL_ 388 ZV_Verdeck_zu 0 "inaktiv" 1 "aktiv" ;
VAL_ 388 ZV_Verdeck_auf 0 "inaktiv" 1 "aktiv" ;
VAL_ 388 FH_FT_hoch 0 "keine_Anforderung" 1 "FT_hoch" ;
VAL_ 388 FH_FT_tief 0 "keine_Anforderung" 1 "FT_tief" ;
VAL_ 388 FH_BT_hoch 0 "keine_Anforderung" 1 "BT_hoch" ;
VAL_ 388 FH_BT_tief 0 "keine_Anforderung" 1 "BT_tief" ;
VAL_ 388 FH_HFS_hoch 0 "inaktiv" 1 "aktiv" ;
VAL_ 388 FH_HFS_tief 0 "inaktiv" 1 "aktiv" ;
VAL_ 388 FH_HBFS_hoch 0 "inaktiv" 1 "aktiv" ;
VAL_ 388 FH_HBFS_tief 0 "inaktiv" 1 "aktiv" ;
VAL_ 388 BCM_Spg_Synchron 0 "inaktiv" 1 "aktiv" ;
VAL_ 388 BCM_BF_Spg_Absenkung 0 "inaktiv" 1 "aktiv" ;
VAL_ 388 ZV_entriegeln_Anf 0 "nicht_betaetigt" 1 "betaetigt" ;
VAL_ 388 ZV_auto_Ansteuerung 0 "Kein_Autolock_Unlock" 1 "Autolock_Unlock" ;
VAL_ 1411 ZV_verriegeln_Anf 0 "nicht_betaetigt" 1 "betaetigt" ;
VAL_ 1411 ZV_STSG_HFS_Anf 0 "keine_Anforderung" 1 "Anforderung" ;
VAL_ 1411 ZV_STSG_HBFS_Anf 0 "keine_Anforderung" 1 "Anforderung" ;
VAL_ 1411 ZV_Anf_Challenge_Auth 0 "nicht_aktiv" 1 "aktiv" ;
VAL_ 1411 ZV_STSG_Crashzustand 0 "inaktiv" 1 "aktiv" ;
VAL_ 1411 ZV_STSG_eKiSi_defekt 0 "inaktiv" 1 "aktiv" ;
VAL_ 1411 ZV_eRWK_Umfeld_Pruefung 0 "nicht_aktiv" 1 "aktiv" ;
VAL_ 1411 VIP_Sensor_STSG_HFS_betaetigt 0 "keine_VIP_Anforderung_STSG_HFS" 1 "VIP_Anforderung_STSG_HFS" ;
VAL_ 1411 VIP_Sensor_STSG_HBFS_betaetigt 0 "keine_VIP_Anforderung_STSG_HBFS" 1 "VIP_Anforderung_STSG_HBFS" ;
VAL_ 1411 BCM_FH_Freigabe 1 "Funktionsfreigabe Fensterheber" ;
VAL_ 1411 BCM_Komfortfkt_Freigabe 0 "Komfortfunktion gesperrt" 1 "globale Freigabe der Komfortfunktion erteilt" ;
VAL_ 1411 BCM_HSK_Freigabe 0 "erlauben" 1 "sperren" ;
VAL_ 1411 BCM_Verdeck_Freigabe 0 "Verdeckbetrieb nicht erlaubt" 1 "Verdeckbetrieb erlaubt" ;
VAL_ 1411 ZV_verriegelt_intern_ist 1 "Fahrzeug innen verriegelt; Istzustand" ;
VAL_ 1411 ZV_verriegelt_extern_ist 1 "Fahrzeug_aussen_verriegelt_Istzustand" ;
VAL_ 1411 ZV_verriegelt_intern_soll 1 "Fahrzeug verriegelt intern; Sollzusstand" ;
VAL_ 1411 ZV_verriegelt_extern_soll 1 "Fahrzeug verriegelt extern; Sollzusstand" ;
VAL_ 1411 ZV_gesafet_extern_ist 1 "Fahrzeug aussen gesafet; Istzustand" ;
VAL_ 1411 ZV_gesafet_extern_soll 1 "Fahrzeug_aussen_gesafet_Sollzustand" ;
VAL_ 1411 ZV_Einzeltuerentriegelung 1 "Fahrzeug an Einzeltuer entriegelt" ;
VAL_ 1411 ZV_Heckeinzelentriegelung 1 "Heckdeckeleinzelentriegelung" ;
VAL_ 1411 ZV_FT_offen 0 "FT_geschlossen" 1 "FT_geoeffnet" ;
VAL_ 1411 ZV_BT_offen 0 "BT_geschlossen" 1 "BT_geoeffnet" ;
VAL_ 1411 ZV_HFS_offen 0 "geschlossen" 1 "offen" ;
VAL_ 1411 ZV_HBFS_offen 0 "geschlossen" 1 "offen" ;
VAL_ 1411 ZV_HD_offen 1 "Heckdeckel_auf" ;
VAL_ 1411 ZV_HS_offen 0 "Heckscheibe_geschlossen" 1 "Heckscheibe auf" ;
VAL_ 1411 IRUE_aktiv 0 "unscharf" 1 "scharf" ;
VAL_ 1411 DWA_aktiv 0 "unscharf" 1 "scharf" ;
VAL_ 1411 HD_Hauptraste 0 "geschlossen" 1 "offen" ;
VAL_ 1411 HD_Vorraste 0 "geschlossen" 1 "offen" ;
VAL_ 1411 FFB_HDF_Taste 0 "Taste_nicht_betaetigt" 1 "HDF_Taste_am_Funkschluessel_betaetigt" ;
VAL_ 1411 FFB_Panik_Taste 0 "Taste_nicht_betaetigt" 1 "Panik_Taste_am_Funkschluessel_betaetigt" ;
VAL_ 1411 FFB_Auf_Taste 0 "Taste_nicht_betaetigt" 1 "Oeffnentaste_betaetigt" ;
VAL_ 1411 FFB_Zu_Taste 0 "Taste_nicht_betaetigt" 1 "Zu_Taste_am_Funkschluessel_betaetigt" ;
VAL_ 1411 FFB_CarFinder 0 "nicht aktiv" 1 "aktiv" ;
VAL_ 1411 FFB_Komfortoeffnen 0 "kein_Komfortoeffnen_empfangen" 1 "Komfortoeffnen ueber Funk empfangen" ;
VAL_ 1411 FFB_Komfortschliessen 0 "kein_Komfortschliessen_empfangen" 1 "Komfortschliessen ueber Funk empfangen" ;
VAL_ 1411 FBS_IDG_in_Reichweite 0 "ausser_Reichweite_bzw_nicht_ermittelbar" 1 "innerhalb_Reichweite" ;
VAL_ 1411 ZV_Schluessel_Zugang 0 "kein_auth_Schluessel_erkannt" 1 "aktive_Funkschluessel_Nr_01" 2 "aktive_Funkschluessel_Nr_02" 3 "aktive_Funkschluessel_Nr_03" 4 "aktive_Funkschluessel_Nr_04" 5 "aktive_Funkschluessel_Nr_05" 6 "aktive_Funkschluessel_Nr_06" 7 "aktive_Funkschluessel_Nr_07" 8 "aktive_Funkschluessel_Nr_08" 9 "aktive_SmartDevice_Nr_09" 10 "ungueltig_10" 11 "ungueltig_11" 12 "ungueltig_12" 13 "ungueltig_13" 14 "ungueltig_14" 15 "ungueltig_15" ;
VAL_ 1411 ZV_SafeFunktion_aktiv 0 "inaktiv" 1 "aktiv" ;
VAL_ 1411 FBS_Warn_Schluessel_Batt 0 "i.O." 1 "defekt" ;
VAL_ 1411 ZV_Oeffnungsmodus 0 "globale_Oeffnung" 1 "ZV_mit_Einzeltuerentr" 2 "ZV_individuell_selektiv" 3 "ZV_seitenselektiv" ;
VAL_ 1411 HFS_verriegelt 0 "nicht_verriegelt" 1 "verriegelt" ;
VAL_ 1411 HFS_gesafet 0 "nicht_gesafet" 1 "gesafet" ;
VAL_ 1411 HBFS_verriegelt 0 "nicht_verriegelt" 1 "verriegelt" ;
VAL_ 1411 HBFS_gesafet 0 "nicht_gesafet" 1 "gesafet" ;
VAL_ 1411 ZV_ist_Zustand_verfuegbar 0 "nicht_verfuegbar" 1 "verfuegbar_alle_TSGs_am_Bus" ;
VAL_ 1411 IRUE_Taster_Fkts_LED 0 "LED_aus" 1 "LED_ein" ;
VAL_ 1411 ZV_Tankklappe_offen 0 "Tankklappe_geschlossen" 1 "Tankklappe_offen" ;
VAL_ 1411 ZV_Rollo_auf 0 "inaktiv" 1 "aktiv" ;
VAL_ 1411 ZV_Rollo_zu 0 "inaktiv" 1 "aktiv" ;
VAL_ 1411 ZV_SAD_auf 0 "inaktiv" 1 "aktiv" ;
VAL_ 1411 ZV_SAD_zu 0 "inaktiv" 1 "aktiv" ;
VAL_ 1411 BCM_Tankklappensteller_Fehler 0 "kein_Fehler" 1 "Fehler" ;
VAL_ 1411 ZV_verriegelt_soll 0 "Init" 1 "nicht_verriegelt" 2 "verriegelt" ;
